VERSION ""

NS_ :

BS_:

BU_: PowertrainControlModule AtmosphericSensor SafetyRestraintSystem2 Aftertreatment_2_GasOutlet Aftertreatment_2_GasIntake DieselParticulateFilterControl Turbocharger SafetyRestraintSystem1 CabDisplay2 Aftertreatment_1_GasOutlet Aftertreatment_1_GasIntake OnBoardDataLogger OffBoardDiagnosticTool2 OffBoardDiagnosticTool1 FileServer ParkingBrakeController SeatController2 FanDriveController SteeringColumnUnit CommunicationUnitRadio CommunicationUnitSatellite CommunicationUnitCellular PropulsionBatteryCharger ChassisController2 ChassisController1 EngineValveControl AuxiliaryHeater2 AuxiliaryHeater1 ClutchUnit RampControl InformationSystem1 SuspensionSystemController2 OilSensor VehicleDynamicStability ExhaustEmissionController TransmissionDisplay2 TransmissionDisplay1 ClimateControl2 WaterPumpController RearAxleSteeringController LightingOperatorControl SeatController1 IgnitionController2 IgnitionController1 TirePressureController CabController2 CabController1 PneumaticSystemController SuspensionSystemController1 HydraulicPumpController EnduranceBrakingSystem RetarderExhaustEngine2 OnBoardDiagnosticUnit HeadwayController RetarderExhaustEngine1 CabDisplay1 ManagementComputer VirtualTerminal OffVehicleGateway PowerTakeOffFront HitchControl AuxiliaryValveControl BodyController TractorTrailerBridge1 StarterSystem ElectricalSystem VehicleSecurity VehicleNavigation AerodynamicControl ElectricalChargingSystem ClimateControl1 TripRecorder InstrumentCluster SuspensionDriveAxle2 SuspensionDriveAxle1 SuspensionSteerAxle SteeringController FuelSystem CruiseControl RetarderDriveline RetarderEngine BrakesDriveAxle2 BrakesDriveAxle1 BrakesSystemController BrakesSteerAxle AxleDrive2 AxleDrive1 AxleSteering PowerTakeOff ShiftConsoleSecondary ShiftConsolePrimary Transmission2 Transmission1 Engine2 Engine1

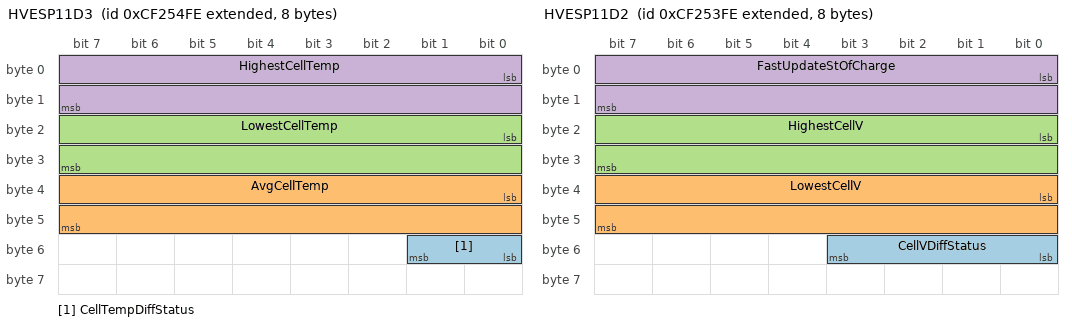
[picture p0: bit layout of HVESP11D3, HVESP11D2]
BO_ 2364691710 HVESP11D3: 8 Vector__XXX
 SG_ CellTempDiffStatus : 48|2@1+ (1,0) [0|3] "" Vector__XXX
 SG_ AvgCellTemp : 32|16@1+ (0.03125,-273) [-273|1734.96875] "°C" Vector__XXX
 SG_ LowestCellTemp : 16|16@1+ (0.03125,-273) [-273|1734.96875] "°C" Vector__XXX
 SG_ HighestCellTemp : 0|16@1+ (0.03125,-273) [-273|1734.96875] "°C" Vector__XXX

BO_ 2364691454 HVESP11D2: 8 Vector__XXX
 SG_ CellVDiffStatus : 48|4@1+ (1,0) [0|15] "" Vector__XXX
 SG_ LowestCellV : 32|16@1+ (0.001,0) [0|64.255] "V" Vector__XXX
 SG_ HighestCellV : 16|16@1+ (0.001,0) [0|64.255] "V" Vector__XXX
 SG_ FastUpdateStOfCharge : 0|16@1+ (0.0015625,0) [0|100.3984375] "%" Vector__XXX

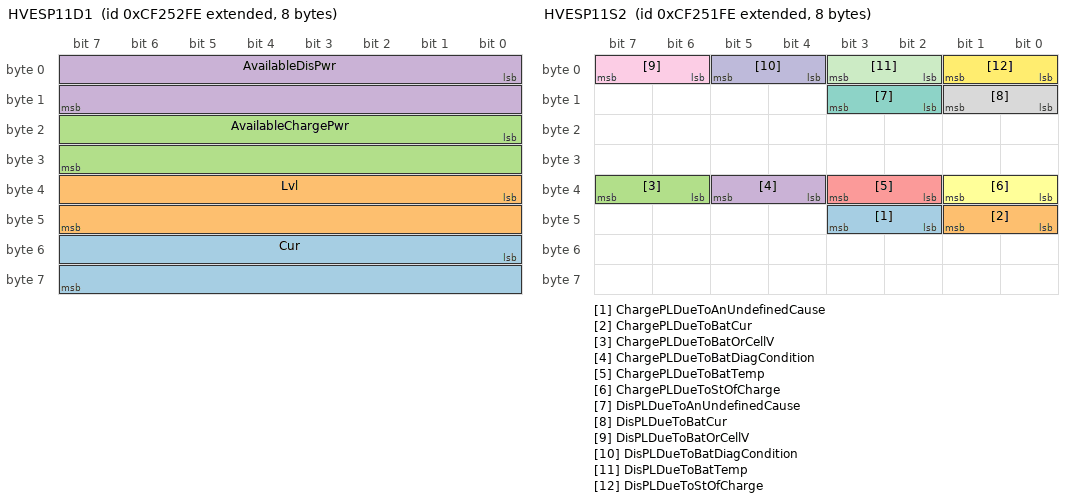
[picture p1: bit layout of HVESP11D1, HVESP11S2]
BO_ 2364691198 HVESP11D1: 8 Vector__XXX
 SG_ Cur : 48|16@1+ (0.05,-1600) [-1600|1612.75] "A" Vector__XXX
 SG_ Lvl : 32|16@1+ (0.05,0) [0|3212.75] "V" Vector__XXX
 SG_ AvailableChargePwr : 16|16@1+ (0.05,0) [0|3212.75] "kW" Vector__XXX
 SG_ AvailableDisPwr : 0|16@1+ (0.05,0) [0|3212.75] "kW" Vector__XXX

BO_ 2364690942 HVESP11S2: 8 Vector__XXX
 SG_ ChargePLDueToAnUndefinedCause : 42|2@1+ (1,0) [0|3] "" Vector__XXX
 SG_ ChargePLDueToBatCur : 40|2@1+ (1,0) [0|3] "" Vector__XXX
 SG_ ChargePLDueToBatOrCellV : 38|2@1+ (1,0) [0|3] "" Vector__XXX
 SG_ ChargePLDueToBatDiagCondition : 36|2@1+ (1,0) [0|3] "" Vector__XXX
 SG_ ChargePLDueToBatTemp : 34|2@1+ (1,0) [0|3] "" Vector__XXX
 SG_ ChargePLDueToStOfCharge : 32|2@1+ (1,0) [0|3] "" Vector__XXX
 SG_ DisPLDueToAnUndefinedCause : 10|2@1+ (1,0) [0|3] "" Vector__XXX
 SG_ DisPLDueToBatCur : 8|2@1+ (1,0) [0|3] "" Vector__XXX
 SG_ DisPLDueToBatOrCellV : 6|2@1+ (1,0) [0|3] "" Vector__XXX
 SG_ DisPLDueToBatDiagCondition : 4|2@1+ (1,0) [0|3] "" Vector__XXX
 SG_ DisPLDueToBatTemp : 2|2@1+ (1,0) [0|3] "" Vector__XXX
 SG_ DisPLDueToStOfCharge : 0|2@1+ (1,0) [0|3] "" Vector__XXX

BO_ 2364690686 EATC1: 8 Vector__XXX
 SG_ OutSpd : 0|16@1+ (0.125,0) [0|8031.875] "rpm" Vector__XXX

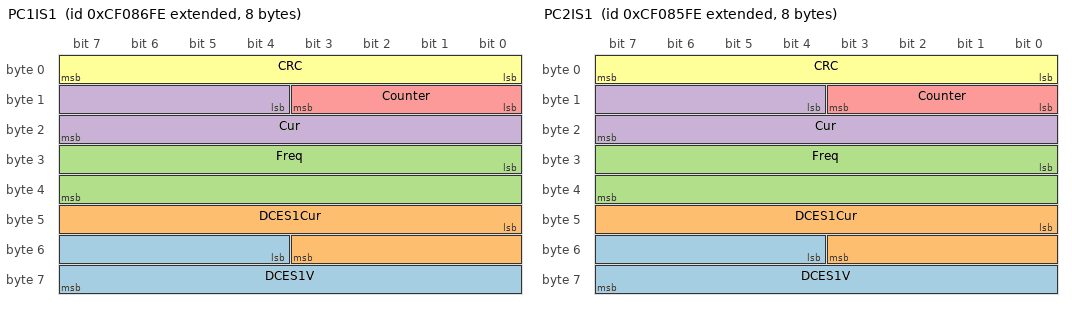
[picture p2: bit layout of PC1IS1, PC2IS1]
BO_ 2364573438 PC1IS1: 8 Vector__XXX
 SG_ DCES1V : 52|12@1+ (0.0625,-125) [-125|125.9375] "%" Vector__XXX
 SG_ DCES1Cur : 40|12@1+ (0.0625,-125) [-125|125.9375] "%" Vector__XXX
 SG_ Freq : 24|16@1+ (0.00390625,-125) [-125|125.99609375] "%" Vector__XXX
 SG_ Cur : 12|12@1+ (0.0625,-125) [-125|125.9375] "%" Vector__XXX
 SG_ Counter : 8|4@1+ (1,0) [0|15] "" Vector__XXX
 SG_ CRC : 0|8@1+ (1,0) [0|255] "" Vector__XXX

BO_ 2364573182 PC2IS1: 8 Vector__XXX
 SG_ DCES1V : 52|12@1+ (0.0625,-125) [-125|125.9375] "%" Vector__XXX
 SG_ DCES1Cur : 40|12@1+ (0.0625,-125) [-125|125.9375] "%" Vector__XXX
 SG_ Freq : 24|16@1+ (0.00390625,-125) [-125|125.99609375] "%" Vector__XXX
 SG_ Cur : 12|12@1+ (0.0625,-125) [-125|125.9375] "%" Vector__XXX
 SG_ Counter : 8|4@1+ (1,0) [0|15] "" Vector__XXX
 SG_ CRC : 0|8@1+ (1,0) [0|255] "" Vector__XXX

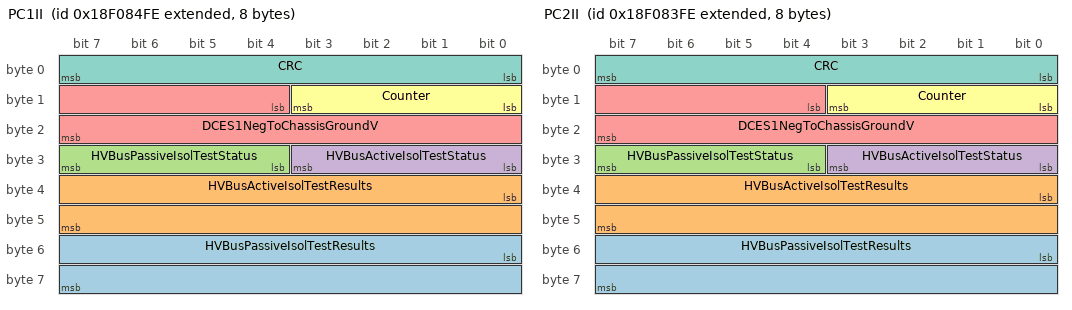
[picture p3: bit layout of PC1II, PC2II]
BO_ 2565899518 PC1II: 8 Vector__XXX
 SG_ HVBusPassiveIsolTestResults : 48|16@1+ (0.1,0) [0|6425.5] "Ohm/V" Vector__XXX
 SG_ HVBusActiveIsolTestResults : 32|16@1+ (0.1,0) [0|6425.5] "Ohm/V" Vector__XXX
 SG_ HVBusPassiveIsolTestStatus : 28|4@1+ (1,0) [0|15] "" Vector__XXX
 SG_ HVBusActiveIsolTestStatus : 24|4@1+ (1,0) [0|15] "" Vector__XXX
 SG_ DCES1NegToChassisGroundV : 12|12@1+ (0.0625,-125) [-125|125.9375] "%" Vector__XXX
 SG_ Counter : 8|4@1+ (1,0) [0|15] "" Vector__XXX
 SG_ CRC : 0|8@1+ (1,0) [0|255] "" Vector__XXX

BO_ 2565899262 PC2II: 8 Vector__XXX
 SG_ HVBusPassiveIsolTestResults : 48|16@1+ (0.1,0) [0|6425.5] "Ohm/V" Vector__XXX
 SG_ HVBusActiveIsolTestResults : 32|16@1+ (0.1,0) [0|6425.5] "Ohm/V" Vector__XXX
 SG_ HVBusPassiveIsolTestStatus : 28|4@1+ (1,0) [0|15] "" Vector__XXX
 SG_ HVBusActiveIsolTestStatus : 24|4@1+ (1,0) [0|15] "" Vector__XXX
 SG_ DCES1NegToChassisGroundV : 12|12@1+ (0.0625,-125) [-125|125.9375] "%" Vector__XXX
 SG_ Counter : 8|4@1+ (1,0) [0|15] "" Vector__XXX
 SG_ CRC : 0|8@1+ (1,0) [0|255] "" Vector__XXX

BO_ 2565899006 PC2IRLA1: 8 Vector__XXX
 SG_ AbsCurRateLmt : 24|12@1+ (2,0) [0|8030] "%/s" Vector__XXX
 SG_ Counter : 8|4@1+ (1,0) [0|15] "" Vector__XXX
 SG_ CRC : 0|8@1+ (1,0) [0|255] "" Vector__XXX

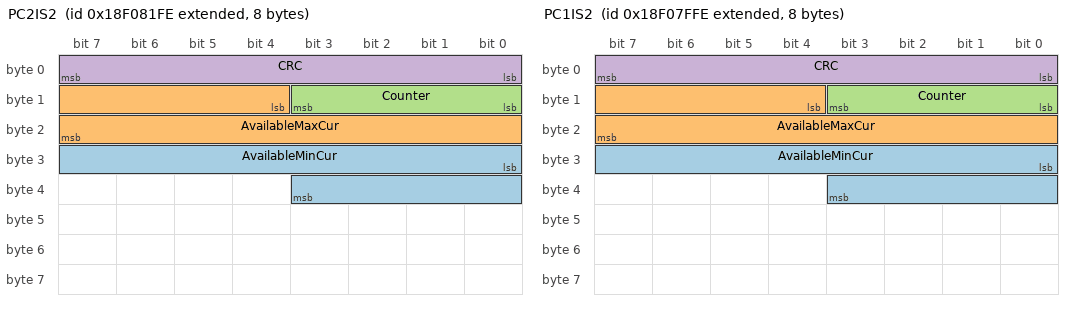
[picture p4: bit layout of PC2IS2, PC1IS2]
BO_ 2565898750 PC2IS2: 8 Vector__XXX
 SG_ AvailableMinCur : 24|12@1+ (0.0625,-125) [-125|125.9375] "%" Vector__XXX
 SG_ AvailableMaxCur : 12|12@1+ (0.0625,-125) [-125|125.9375] "%" Vector__XXX
 SG_ Counter : 8|4@1+ (1,0) [0|15] "" Vector__XXX
 SG_ CRC : 0|8@1+ (1,0) [0|255] "" Vector__XXX

BO_ 2565898494 PC1IRLA1: 8 Vector__XXX
 SG_ AbsCurRateLmt : 24|12@1+ (2,0) [0|8030] "%/s" Vector__XXX
 SG_ Counter : 8|4@1+ (1,0) [0|15] "" Vector__XXX
 SG_ CRC : 0|8@1+ (1,0) [0|255] "" Vector__XXX

BO_ 2565898238 PC1IS2: 8 Vector__XXX
 SG_ AvailableMinCur : 24|12@1+ (0.0625,-125) [-125|125.9375] "%" Vector__XXX
 SG_ AvailableMaxCur : 12|12@1+ (0.0625,-125) [-125|125.9375] "%" Vector__XXX
 SG_ Counter : 8|4@1+ (1,0) [0|15] "" Vector__XXX
 SG_ CRC : 0|8@1+ (1,0) [0|255] "" Vector__XXX

BO_ 2565897982 PC2ILV: 8 Vector__XXX
 SG_ UnswitchedSLIV : 16|16@1+ (0.05,0) [0|3212.75] "V" Vector__XXX
 SG_ SwitchedIgntV : 0|16@1+ (0.05,0) [0|3212.75] "V" Vector__XXX

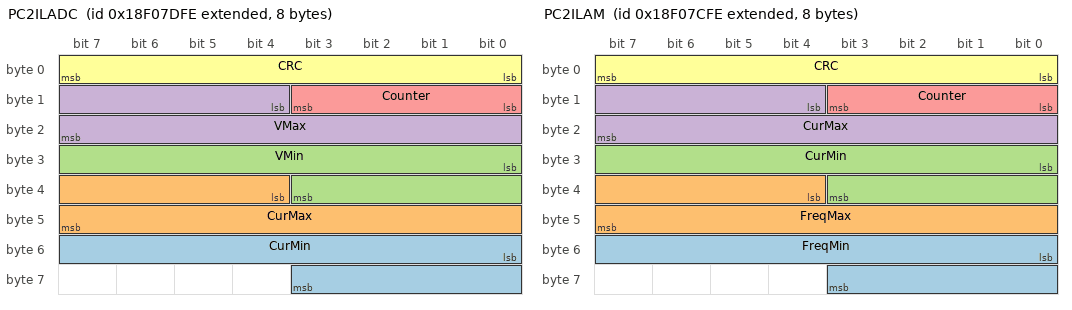
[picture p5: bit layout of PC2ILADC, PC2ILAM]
BO_ 2565897726 PC2ILADC: 8 Vector__XXX
 SG_ CurMin : 48|12@1+ (0.0625,-125) [-125|125.9375] "%" Vector__XXX
 SG_ CurMax : 36|12@1+ (0.0625,-125) [-125|125.9375] "%" Vector__XXX
 SG_ VMin : 24|12@1+ (0.0625,-125) [-125|125.9375] "%" Vector__XXX
 SG_ VMax : 12|12@1+ (0.0625,-125) [-125|125.9375] "%" Vector__XXX
 SG_ Counter : 8|4@1+ (1,0) [0|15] "" Vector__XXX
 SG_ CRC : 0|8@1+ (1,0) [0|255] "" Vector__XXX

BO_ 2565897470 PC2ILAM: 8 Vector__XXX
 SG_ FreqMin : 48|12@1+ (0.0625,-125) [-125|125.9375] "%" Vector__XXX
 SG_ FreqMax : 36|12@1+ (0.0625,-125) [-125|125.9375] "%" Vector__XXX
 SG_ CurMin : 24|12@1+ (0.0625,-125) [-125|125.9375] "%" Vector__XXX
 SG_ CurMax : 12|12@1+ (0.0625,-125) [-125|125.9375] "%" Vector__XXX
 SG_ Counter : 8|4@1+ (1,0) [0|15] "" Vector__XXX
 SG_ CRC : 0|8@1+ (1,0) [0|255] "" Vector__XXX

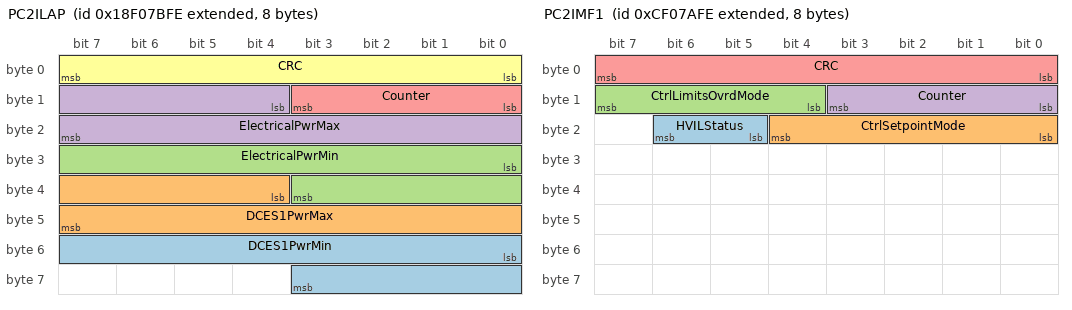
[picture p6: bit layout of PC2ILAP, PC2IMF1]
BO_ 2565897214 PC2ILAP: 8 Vector__XXX
 SG_ DCES1PwrMin : 48|12@1+ (0.0625,-125) [-125|125.9375] "%" Vector__XXX
 SG_ DCES1PwrMax : 36|12@1+ (0.0625,-125) [-125|125.9375] "%" Vector__XXX
 SG_ ElectricalPwrMin : 24|12@1+ (0.0625,-125) [-125|125.9375] "%" Vector__XXX
 SG_ ElectricalPwrMax : 12|12@1+ (0.0625,-125) [-125|125.9375] "%" Vector__XXX
 SG_ Counter : 8|4@1+ (1,0) [0|15] "" Vector__XXX
 SG_ CRC : 0|8@1+ (1,0) [0|255] "" Vector__XXX

BO_ 2364570366 PC2IMF1: 8 Vector__XXX
 SG_ HVILStatus : 21|2@1+ (1,0) [0|3] "" Vector__XXX
 SG_ CtrlSetpointMode : 16|5@1+ (1,0) [0|31] "" Vector__XXX
 SG_ CtrlLimitsOvrdMode : 12|4@1+ (1,0) [0|15] "" Vector__XXX
 SG_ Counter : 8|4@1+ (1,0) [0|15] "" Vector__XXX
 SG_ CRC : 0|8@1+ (1,0) [0|255] "" Vector__XXX

BO_ 2565896702 PC1ILV: 8 Vector__XXX
 SG_ UnswitchedSLIV : 16|16@1+ (0.05,0) [0|3212.75] "V" Vector__XXX
 SG_ SwitchedIgntV : 0|16@1+ (0.05,0) [0|3212.75] "V" Vector__XXX

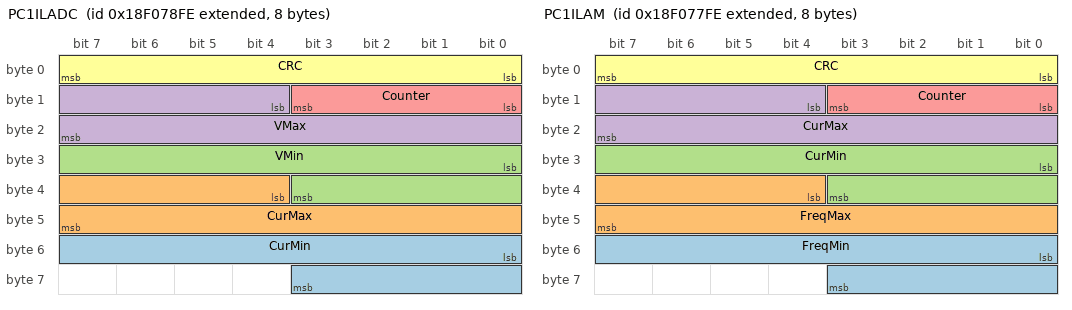
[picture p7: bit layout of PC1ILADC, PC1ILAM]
BO_ 2565896446 PC1ILADC: 8 Vector__XXX
 SG_ CurMin : 48|12@1+ (0.0625,-125) [-125|125.9375] "%" Vector__XXX
 SG_ CurMax : 36|12@1+ (0.0625,-125) [-125|125.9375] "%" Vector__XXX
 SG_ VMin : 24|12@1+ (0.0625,-125) [-125|125.9375] "%" Vector__XXX
 SG_ VMax : 12|12@1+ (0.0625,-125) [-125|125.9375] "%" Vector__XXX
 SG_ Counter : 8|4@1+ (1,0) [0|15] "" Vector__XXX
 SG_ CRC : 0|8@1+ (1,0) [0|255] "" Vector__XXX

BO_ 2565896190 PC1ILAM: 8 Vector__XXX
 SG_ FreqMin : 48|12@1+ (0.0625,-125) [-125|125.9375] "%" Vector__XXX
 SG_ FreqMax : 36|12@1+ (0.0625,-125) [-125|125.9375] "%" Vector__XXX
 SG_ CurMin : 24|12@1+ (0.0625,-125) [-125|125.9375] "%" Vector__XXX
 SG_ CurMax : 12|12@1+ (0.0625,-125) [-125|125.9375] "%" Vector__XXX
 SG_ Counter : 8|4@1+ (1,0) [0|15] "" Vector__XXX
 SG_ CRC : 0|8@1+ (1,0) [0|255] "" Vector__XXX

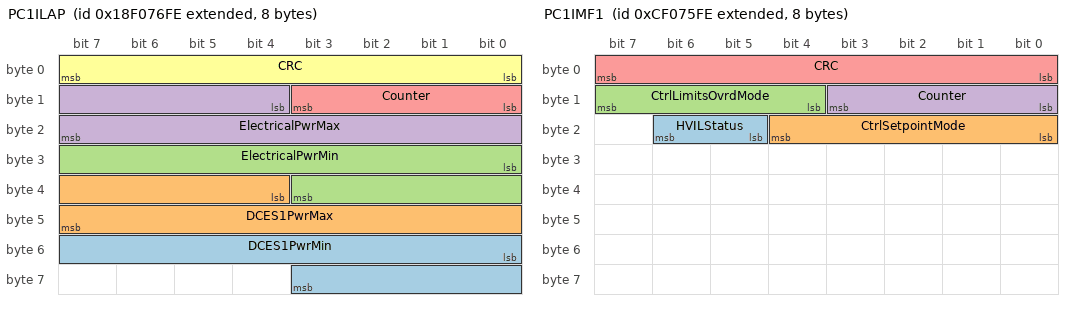
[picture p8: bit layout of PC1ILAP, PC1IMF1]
BO_ 2565895934 PC1ILAP: 8 Vector__XXX
 SG_ DCES1PwrMin : 48|12@1+ (0.0625,-125) [-125|125.9375] "%" Vector__XXX
 SG_ DCES1PwrMax : 36|12@1+ (0.0625,-125) [-125|125.9375] "%" Vector__XXX
 SG_ ElectricalPwrMin : 24|12@1+ (0.0625,-125) [-125|125.9375] "%" Vector__XXX
 SG_ ElectricalPwrMax : 12|12@1+ (0.0625,-125) [-125|125.9375] "%" Vector__XXX
 SG_ Counter : 8|4@1+ (1,0) [0|15] "" Vector__XXX
 SG_ CRC : 0|8@1+ (1,0) [0|255] "" Vector__XXX

BO_ 2364569086 PC1IMF1: 8 Vector__XXX
 SG_ HVILStatus : 21|2@1+ (1,0) [0|3] "" Vector__XXX
 SG_ CtrlSetpointMode : 16|5@1+ (1,0) [0|31] "" Vector__XXX
 SG_ CtrlLimitsOvrdMode : 12|4@1+ (1,0) [0|15] "" Vector__XXX
 SG_ Counter : 8|4@1+ (1,0) [0|15] "" Vector__XXX
 SG_ CRC : 0|8@1+ (1,0) [0|255] "" Vector__XXX

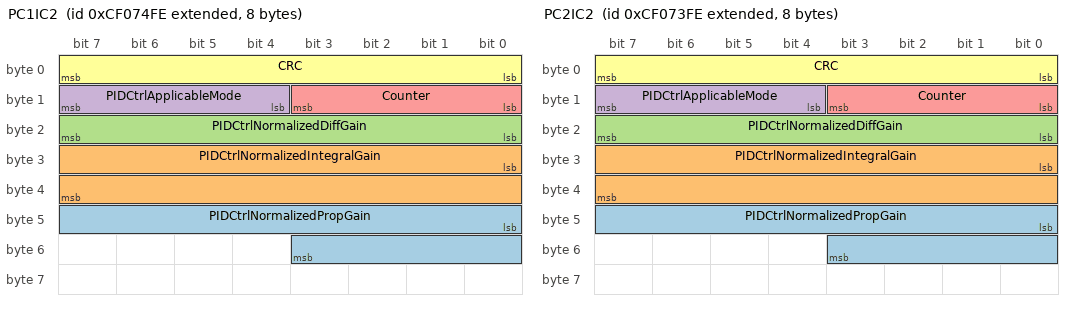
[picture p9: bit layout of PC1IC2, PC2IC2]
BO_ 2364568830 PC1IC2: 8 Vector__XXX
 SG_ PIDCtrlNormalizedPropGain : 40|12@1+ (0.0625,0) [0|250.9375] "%/%" Vector__XXX
 SG_ PIDCtrlNormalizedIntegralGain : 24|16@1+ (0.015625,0) [0|1003.984375] "%/(%*s)" Vector__XXX
 SG_ PIDCtrlNormalizedDiffGain : 16|8@1+ (0.03125,0) [0|7.8125] "%/(%/s)" Vector__XXX
 SG_ PIDCtrlApplicableMode : 12|4@1+ (1,0) [0|15] "" Vector__XXX
 SG_ Counter : 8|4@1+ (1,0) [0|15] "" Vector__XXX
 SG_ CRC : 0|8@1+ (1,0) [0|255] "" Vector__XXX

BO_ 2364568574 PC2IC2: 8 Vector__XXX
 SG_ PIDCtrlNormalizedPropGain : 40|12@1+ (0.0625,0) [0|250.9375] "%/%" Vector__XXX
 SG_ PIDCtrlNormalizedIntegralGain : 24|16@1+ (0.015625,0) [0|1003.984375] "%/(%*s)" Vector__XXX
 SG_ PIDCtrlNormalizedDiffGain : 16|8@1+ (0.03125,0) [0|7.8125] "%/(%/s)" Vector__XXX
 SG_ PIDCtrlApplicableMode : 12|4@1+ (1,0) [0|15] "" Vector__XXX
 SG_ Counter : 8|4@1+ (1,0) [0|15] "" Vector__XXX
 SG_ CRC : 0|8@1+ (1,0) [0|255] "" Vector__XXX

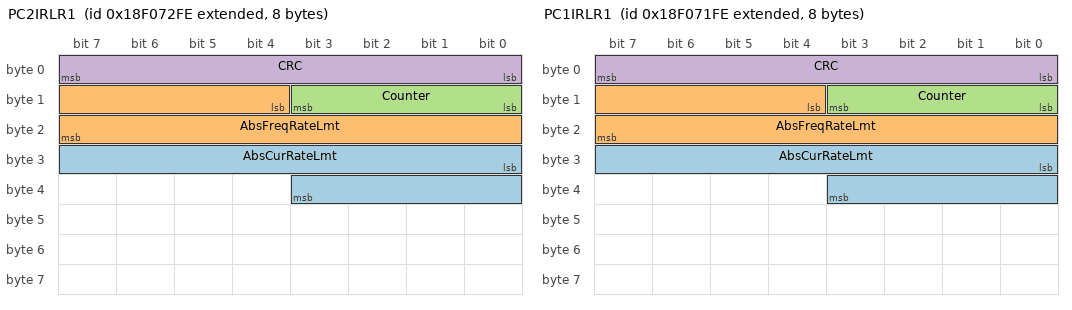
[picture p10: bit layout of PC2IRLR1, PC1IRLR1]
BO_ 2565894910 PC2IRLR1: 8 Vector__XXX
 SG_ AbsCurRateLmt : 24|12@1+ (2,0) [0|8030] "%/s" Vector__XXX
 SG_ AbsFreqRateLmt : 12|12@1+ (0.25,0) [0|1003.75] "%/s" Vector__XXX
 SG_ Counter : 8|4@1+ (1,0) [0|15] "" Vector__XXX
 SG_ CRC : 0|8@1+ (1,0) [0|255] "" Vector__XXX

BO_ 2565894654 PC1IRLR1: 8 Vector__XXX
 SG_ AbsCurRateLmt : 24|12@1+ (2,0) [0|8030] "%/s" Vector__XXX
 SG_ AbsFreqRateLmt : 12|12@1+ (0.25,0) [0|1003.75] "%/s" Vector__XXX
 SG_ Counter : 8|4@1+ (1,0) [0|15] "" Vector__XXX
 SG_ CRC : 0|8@1+ (1,0) [0|255] "" Vector__XXX

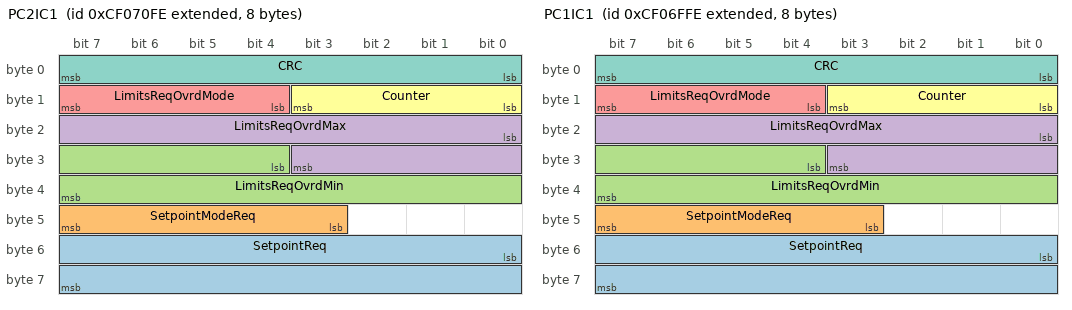
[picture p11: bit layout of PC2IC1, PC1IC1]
BO_ 2364567806 PC2IC1: 8 Vector__XXX
 SG_ SetpointReq : 48|16@1+ (0.00390625,-125) [-125|125.99609375] "%" Vector__XXX
 SG_ SetpointModeReq : 43|5@1+ (1,0) [0|31] "" Vector__XXX
 SG_ LimitsReqOvrdMin : 28|12@1+ (0.0625,-125) [-125|125.9375] "%" Vector__XXX
 SG_ LimitsReqOvrdMax : 16|12@1+ (0.0625,-125) [-125|125.9375] "%" Vector__XXX
 SG_ LimitsReqOvrdMode : 12|4@1+ (1,0) [0|15] "" Vector__XXX
 SG_ Counter : 8|4@1+ (1,0) [0|15] "" Vector__XXX
 SG_ CRC : 0|8@1+ (1,0) [0|255] "" Vector__XXX

BO_ 2364567550 PC1IC1: 8 Vector__XXX
 SG_ SetpointReq : 48|16@1+ (0.00390625,-125) [-125|125.99609375] "%" Vector__XXX
 SG_ SetpointModeReq : 43|5@1+ (1,0) [0|31] "" Vector__XXX
 SG_ LimitsReqOvrdMin : 28|12@1+ (0.0625,-125) [-125|125.9375] "%" Vector__XXX
 SG_ LimitsReqOvrdMax : 16|12@1+ (0.0625,-125) [-125|125.9375] "%" Vector__XXX
 SG_ LimitsReqOvrdMode : 12|4@1+ (1,0) [0|15] "" Vector__XXX
 SG_ Counter : 8|4@1+ (1,0) [0|15] "" Vector__XXX
 SG_ CRC : 0|8@1+ (1,0) [0|255] "" Vector__XXX

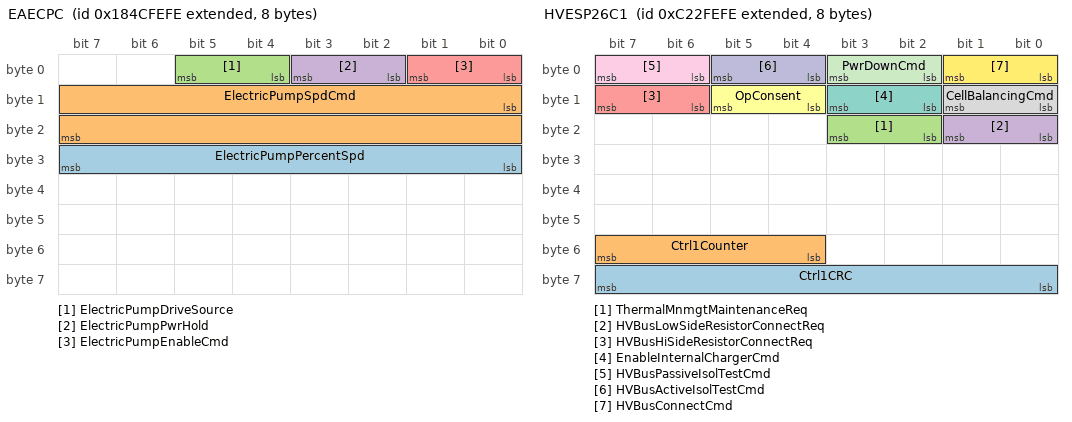
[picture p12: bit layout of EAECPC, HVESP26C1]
BO_ 2555182846 EAECPC: 8 Vector__XXX
 SG_ ElectricPumpPercentSpd : 24|8@1+ (0.5,0) [0|125] "%" Vector__XXX
 SG_ ElectricPumpSpdCmd : 8|16@1+ (0.5,0) [0|32127.5] "rpm" Vector__XXX
 SG_ ElectricPumpDriveSource : 4|2@1+ (1,0) [0|3] "" Vector__XXX
 SG_ ElectricPumpPwrHold : 2|2@1+ (1,0) [0|3] "" Vector__XXX
 SG_ ElectricPumpEnableCmd : 0|2@1+ (1,0) [0|3] "" Vector__XXX

BO_ 2351103742 HVESP26C1: 8 Vector__XXX
 SG_ Ctrl1CRC : 56|8@1+ (1,0) [0|255] "" Vector__XXX
 SG_ Ctrl1Counter : 52|4@1+ (1,0) [0|15] "" Vector__XXX
 SG_ ThermalMnmgtMaintenanceReq : 18|2@1+ (1,0) [0|3] "" Vector__XXX
 SG_ HVBusLowSideResistorConnectReq : 16|2@1+ (1,0) [0|3] "" Vector__XXX
 SG_ HVBusHiSideResistorConnectReq : 14|2@1+ (1,0) [0|3] "" Vector__XXX
 SG_ OpConsent : 12|2@1+ (1,0) [0|3] "" Vector__XXX
 SG_ EnableInternalChargerCmd : 10|2@1+ (1,0) [0|3] "" Vector__XXX
 SG_ CellBalancingCmd : 8|2@1+ (1,0) [0|3] "" Vector__XXX
 SG_ HVBusPassiveIsolTestCmd : 6|2@1+ (1,0) [0|3] "" Vector__XXX
 SG_ HVBusActiveIsolTestCmd : 4|2@1+ (1,0) [0|3] "" Vector__XXX
 SG_ PwrDownCmd : 2|2@1+ (1,0) [0|3] "" Vector__XXX
 SG_ HVBusConnectCmd : 0|2@1+ (1,0) [0|3] "" Vector__XXX

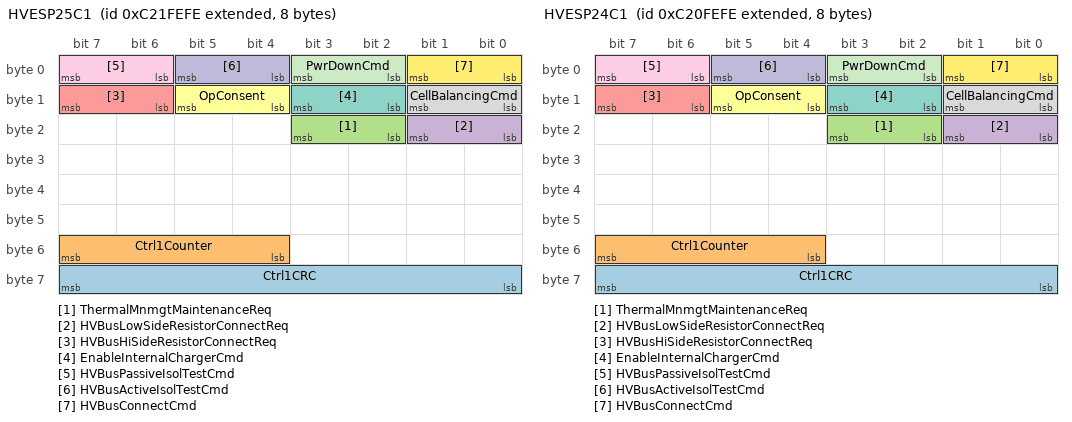
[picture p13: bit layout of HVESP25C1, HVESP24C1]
BO_ 2351038206 HVESP25C1: 8 Vector__XXX
 SG_ Ctrl1CRC : 56|8@1+ (1,0) [0|255] "" Vector__XXX
 SG_ Ctrl1Counter : 52|4@1+ (1,0) [0|15] "" Vector__XXX
 SG_ ThermalMnmgtMaintenanceReq : 18|2@1+ (1,0) [0|3] "" Vector__XXX
 SG_ HVBusLowSideResistorConnectReq : 16|2@1+ (1,0) [0|3] "" Vector__XXX
 SG_ HVBusHiSideResistorConnectReq : 14|2@1+ (1,0) [0|3] "" Vector__XXX
 SG_ OpConsent : 12|2@1+ (1,0) [0|3] "" Vector__XXX
 SG_ EnableInternalChargerCmd : 10|2@1+ (1,0) [0|3] "" Vector__XXX
 SG_ CellBalancingCmd : 8|2@1+ (1,0) [0|3] "" Vector__XXX
 SG_ HVBusPassiveIsolTestCmd : 6|2@1+ (1,0) [0|3] "" Vector__XXX
 SG_ HVBusActiveIsolTestCmd : 4|2@1+ (1,0) [0|3] "" Vector__XXX
 SG_ PwrDownCmd : 2|2@1+ (1,0) [0|3] "" Vector__XXX
 SG_ HVBusConnectCmd : 0|2@1+ (1,0) [0|3] "" Vector__XXX

BO_ 2350972670 HVESP24C1: 8 Vector__XXX
 SG_ Ctrl1CRC : 56|8@1+ (1,0) [0|255] "" Vector__XXX
 SG_ Ctrl1Counter : 52|4@1+ (1,0) [0|15] "" Vector__XXX
 SG_ ThermalMnmgtMaintenanceReq : 18|2@1+ (1,0) [0|3] "" Vector__XXX
 SG_ HVBusLowSideResistorConnectReq : 16|2@1+ (1,0) [0|3] "" Vector__XXX
 SG_ HVBusHiSideResistorConnectReq : 14|2@1+ (1,0) [0|3] "" Vector__XXX
 SG_ OpConsent : 12|2@1+ (1,0) [0|3] "" Vector__XXX
 SG_ EnableInternalChargerCmd : 10|2@1+ (1,0) [0|3] "" Vector__XXX
 SG_ CellBalancingCmd : 8|2@1+ (1,0) [0|3] "" Vector__XXX
 SG_ HVBusPassiveIsolTestCmd : 6|2@1+ (1,0) [0|3] "" Vector__XXX
 SG_ HVBusActiveIsolTestCmd : 4|2@1+ (1,0) [0|3] "" Vector__XXX
 SG_ PwrDownCmd : 2|2@1+ (1,0) [0|3] "" Vector__XXX
 SG_ HVBusConnectCmd : 0|2@1+ (1,0) [0|3] "" Vector__XXX

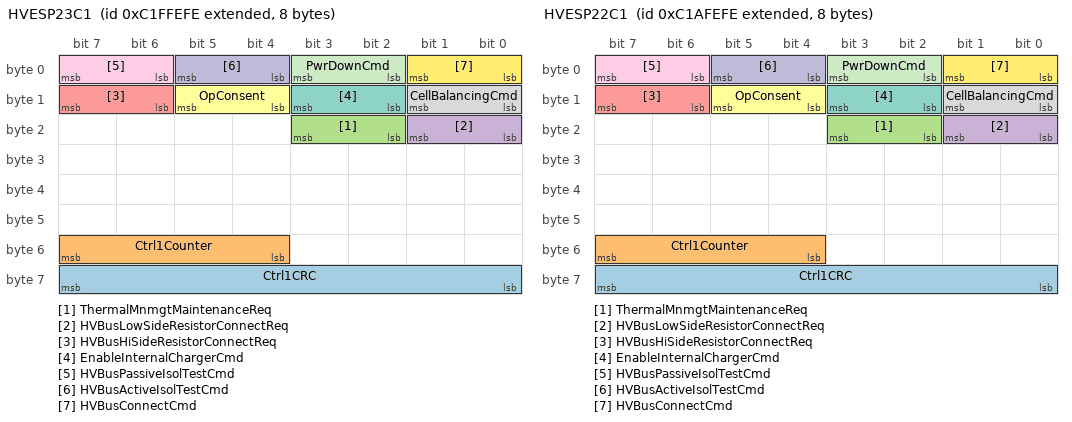
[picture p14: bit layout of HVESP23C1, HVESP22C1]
BO_ 2350907134 HVESP23C1: 8 Vector__XXX
 SG_ Ctrl1CRC : 56|8@1+ (1,0) [0|255] "" Vector__XXX
 SG_ Ctrl1Counter : 52|4@1+ (1,0) [0|15] "" Vector__XXX
 SG_ ThermalMnmgtMaintenanceReq : 18|2@1+ (1,0) [0|3] "" Vector__XXX
 SG_ HVBusLowSideResistorConnectReq : 16|2@1+ (1,0) [0|3] "" Vector__XXX
 SG_ HVBusHiSideResistorConnectReq : 14|2@1+ (1,0) [0|3] "" Vector__XXX
 SG_ OpConsent : 12|2@1+ (1,0) [0|3] "" Vector__XXX
 SG_ EnableInternalChargerCmd : 10|2@1+ (1,0) [0|3] "" Vector__XXX
 SG_ CellBalancingCmd : 8|2@1+ (1,0) [0|3] "" Vector__XXX
 SG_ HVBusPassiveIsolTestCmd : 6|2@1+ (1,0) [0|3] "" Vector__XXX
 SG_ HVBusActiveIsolTestCmd : 4|2@1+ (1,0) [0|3] "" Vector__XXX
 SG_ PwrDownCmd : 2|2@1+ (1,0) [0|3] "" Vector__XXX
 SG_ HVBusConnectCmd : 0|2@1+ (1,0) [0|3] "" Vector__XXX

BO_ 2350579454 HVESP22C1: 8 Vector__XXX
 SG_ Ctrl1CRC : 56|8@1+ (1,0) [0|255] "" Vector__XXX
 SG_ Ctrl1Counter : 52|4@1+ (1,0) [0|15] "" Vector__XXX
 SG_ ThermalMnmgtMaintenanceReq : 18|2@1+ (1,0) [0|3] "" Vector__XXX
 SG_ HVBusLowSideResistorConnectReq : 16|2@1+ (1,0) [0|3] "" Vector__XXX
 SG_ HVBusHiSideResistorConnectReq : 14|2@1+ (1,0) [0|3] "" Vector__XXX
 SG_ OpConsent : 12|2@1+ (1,0) [0|3] "" Vector__XXX
 SG_ EnableInternalChargerCmd : 10|2@1+ (1,0) [0|3] "" Vector__XXX
 SG_ CellBalancingCmd : 8|2@1+ (1,0) [0|3] "" Vector__XXX
 SG_ HVBusPassiveIsolTestCmd : 6|2@1+ (1,0) [0|3] "" Vector__XXX
 SG_ HVBusActiveIsolTestCmd : 4|2@1+ (1,0) [0|3] "" Vector__XXX
 SG_ PwrDownCmd : 2|2@1+ (1,0) [0|3] "" Vector__XXX
 SG_ HVBusConnectCmd : 0|2@1+ (1,0) [0|3] "" Vector__XXX

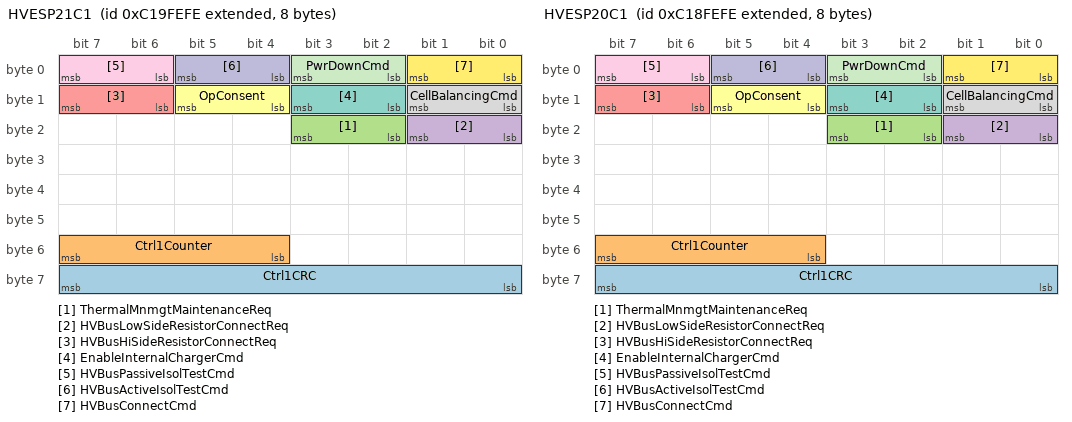
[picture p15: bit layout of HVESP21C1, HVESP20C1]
BO_ 2350513918 HVESP21C1: 8 Vector__XXX
 SG_ Ctrl1CRC : 56|8@1+ (1,0) [0|255] "" Vector__XXX
 SG_ Ctrl1Counter : 52|4@1+ (1,0) [0|15] "" Vector__XXX
 SG_ ThermalMnmgtMaintenanceReq : 18|2@1+ (1,0) [0|3] "" Vector__XXX
 SG_ HVBusLowSideResistorConnectReq : 16|2@1+ (1,0) [0|3] "" Vector__XXX
 SG_ HVBusHiSideResistorConnectReq : 14|2@1+ (1,0) [0|3] "" Vector__XXX
 SG_ OpConsent : 12|2@1+ (1,0) [0|3] "" Vector__XXX
 SG_ EnableInternalChargerCmd : 10|2@1+ (1,0) [0|3] "" Vector__XXX
 SG_ CellBalancingCmd : 8|2@1+ (1,0) [0|3] "" Vector__XXX
 SG_ HVBusPassiveIsolTestCmd : 6|2@1+ (1,0) [0|3] "" Vector__XXX
 SG_ HVBusActiveIsolTestCmd : 4|2@1+ (1,0) [0|3] "" Vector__XXX
 SG_ PwrDownCmd : 2|2@1+ (1,0) [0|3] "" Vector__XXX
 SG_ HVBusConnectCmd : 0|2@1+ (1,0) [0|3] "" Vector__XXX

BO_ 2350448382 HVESP20C1: 8 Vector__XXX
 SG_ Ctrl1CRC : 56|8@1+ (1,0) [0|255] "" Vector__XXX
 SG_ Ctrl1Counter : 52|4@1+ (1,0) [0|15] "" Vector__XXX
 SG_ ThermalMnmgtMaintenanceReq : 18|2@1+ (1,0) [0|3] "" Vector__XXX
 SG_ HVBusLowSideResistorConnectReq : 16|2@1+ (1,0) [0|3] "" Vector__XXX
 SG_ HVBusHiSideResistorConnectReq : 14|2@1+ (1,0) [0|3] "" Vector__XXX
 SG_ OpConsent : 12|2@1+ (1,0) [0|3] "" Vector__XXX
 SG_ EnableInternalChargerCmd : 10|2@1+ (1,0) [0|3] "" Vector__XXX
 SG_ CellBalancingCmd : 8|2@1+ (1,0) [0|3] "" Vector__XXX
 SG_ HVBusPassiveIsolTestCmd : 6|2@1+ (1,0) [0|3] "" Vector__XXX
 SG_ HVBusActiveIsolTestCmd : 4|2@1+ (1,0) [0|3] "" Vector__XXX
 SG_ PwrDownCmd : 2|2@1+ (1,0) [0|3] "" Vector__XXX
 SG_ HVBusConnectCmd : 0|2@1+ (1,0) [0|3] "" Vector__XXX

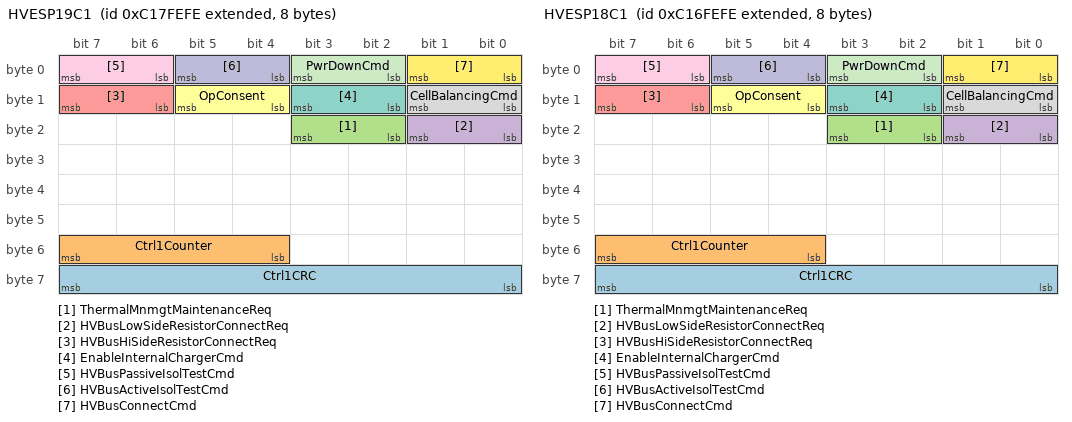
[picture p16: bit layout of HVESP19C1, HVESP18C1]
BO_ 2350382846 HVESP19C1: 8 Vector__XXX
 SG_ Ctrl1CRC : 56|8@1+ (1,0) [0|255] "" Vector__XXX
 SG_ Ctrl1Counter : 52|4@1+ (1,0) [0|15] "" Vector__XXX
 SG_ ThermalMnmgtMaintenanceReq : 18|2@1+ (1,0) [0|3] "" Vector__XXX
 SG_ HVBusLowSideResistorConnectReq : 16|2@1+ (1,0) [0|3] "" Vector__XXX
 SG_ HVBusHiSideResistorConnectReq : 14|2@1+ (1,0) [0|3] "" Vector__XXX
 SG_ OpConsent : 12|2@1+ (1,0) [0|3] "" Vector__XXX
 SG_ EnableInternalChargerCmd : 10|2@1+ (1,0) [0|3] "" Vector__XXX
 SG_ CellBalancingCmd : 8|2@1+ (1,0) [0|3] "" Vector__XXX
 SG_ HVBusPassiveIsolTestCmd : 6|2@1+ (1,0) [0|3] "" Vector__XXX
 SG_ HVBusActiveIsolTestCmd : 4|2@1+ (1,0) [0|3] "" Vector__XXX
 SG_ PwrDownCmd : 2|2@1+ (1,0) [0|3] "" Vector__XXX
 SG_ HVBusConnectCmd : 0|2@1+ (1,0) [0|3] "" Vector__XXX

BO_ 2350317310 HVESP18C1: 8 Vector__XXX
 SG_ Ctrl1CRC : 56|8@1+ (1,0) [0|255] "" Vector__XXX
 SG_ Ctrl1Counter : 52|4@1+ (1,0) [0|15] "" Vector__XXX
 SG_ ThermalMnmgtMaintenanceReq : 18|2@1+ (1,0) [0|3] "" Vector__XXX
 SG_ HVBusLowSideResistorConnectReq : 16|2@1+ (1,0) [0|3] "" Vector__XXX
 SG_ HVBusHiSideResistorConnectReq : 14|2@1+ (1,0) [0|3] "" Vector__XXX
 SG_ OpConsent : 12|2@1+ (1,0) [0|3] "" Vector__XXX
 SG_ EnableInternalChargerCmd : 10|2@1+ (1,0) [0|3] "" Vector__XXX
 SG_ CellBalancingCmd : 8|2@1+ (1,0) [0|3] "" Vector__XXX
 SG_ HVBusPassiveIsolTestCmd : 6|2@1+ (1,0) [0|3] "" Vector__XXX
 SG_ HVBusActiveIsolTestCmd : 4|2@1+ (1,0) [0|3] "" Vector__XXX
 SG_ PwrDownCmd : 2|2@1+ (1,0) [0|3] "" Vector__XXX
 SG_ HVBusConnectCmd : 0|2@1+ (1,0) [0|3] "" Vector__XXX

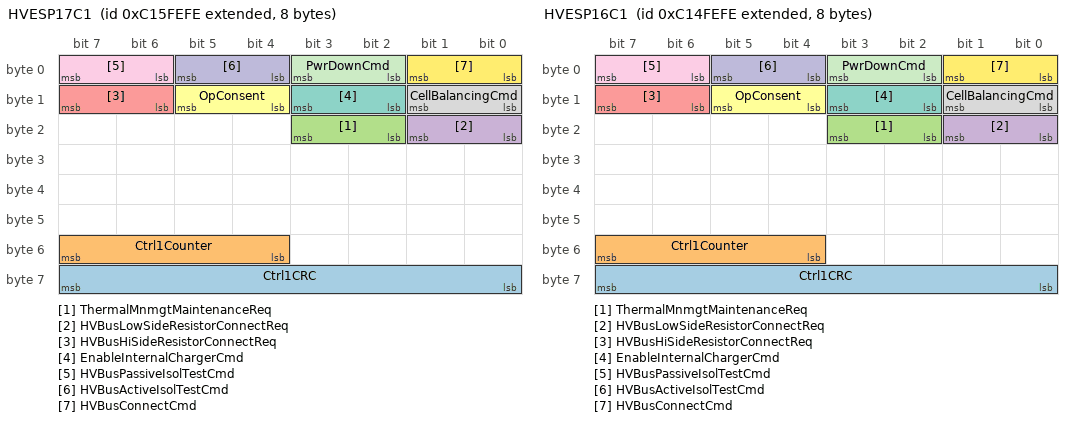
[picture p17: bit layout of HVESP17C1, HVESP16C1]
BO_ 2350251774 HVESP17C1: 8 Vector__XXX
 SG_ Ctrl1CRC : 56|8@1+ (1,0) [0|255] "" Vector__XXX
 SG_ Ctrl1Counter : 52|4@1+ (1,0) [0|15] "" Vector__XXX
 SG_ ThermalMnmgtMaintenanceReq : 18|2@1+ (1,0) [0|3] "" Vector__XXX
 SG_ HVBusLowSideResistorConnectReq : 16|2@1+ (1,0) [0|3] "" Vector__XXX
 SG_ HVBusHiSideResistorConnectReq : 14|2@1+ (1,0) [0|3] "" Vector__XXX
 SG_ OpConsent : 12|2@1+ (1,0) [0|3] "" Vector__XXX
 SG_ EnableInternalChargerCmd : 10|2@1+ (1,0) [0|3] "" Vector__XXX
 SG_ CellBalancingCmd : 8|2@1+ (1,0) [0|3] "" Vector__XXX
 SG_ HVBusPassiveIsolTestCmd : 6|2@1+ (1,0) [0|3] "" Vector__XXX
 SG_ HVBusActiveIsolTestCmd : 4|2@1+ (1,0) [0|3] "" Vector__XXX
 SG_ PwrDownCmd : 2|2@1+ (1,0) [0|3] "" Vector__XXX
 SG_ HVBusConnectCmd : 0|2@1+ (1,0) [0|3] "" Vector__XXX

BO_ 2350186238 HVESP16C1: 8 Vector__XXX
 SG_ Ctrl1CRC : 56|8@1+ (1,0) [0|255] "" Vector__XXX
 SG_ Ctrl1Counter : 52|4@1+ (1,0) [0|15] "" Vector__XXX
 SG_ ThermalMnmgtMaintenanceReq : 18|2@1+ (1,0) [0|3] "" Vector__XXX
 SG_ HVBusLowSideResistorConnectReq : 16|2@1+ (1,0) [0|3] "" Vector__XXX
 SG_ HVBusHiSideResistorConnectReq : 14|2@1+ (1,0) [0|3] "" Vector__XXX
 SG_ OpConsent : 12|2@1+ (1,0) [0|3] "" Vector__XXX
 SG_ EnableInternalChargerCmd : 10|2@1+ (1,0) [0|3] "" Vector__XXX
 SG_ CellBalancingCmd : 8|2@1+ (1,0) [0|3] "" Vector__XXX
 SG_ HVBusPassiveIsolTestCmd : 6|2@1+ (1,0) [0|3] "" Vector__XXX
 SG_ HVBusActiveIsolTestCmd : 4|2@1+ (1,0) [0|3] "" Vector__XXX
 SG_ PwrDownCmd : 2|2@1+ (1,0) [0|3] "" Vector__XXX
 SG_ HVBusConnectCmd : 0|2@1+ (1,0) [0|3] "" Vector__XXX

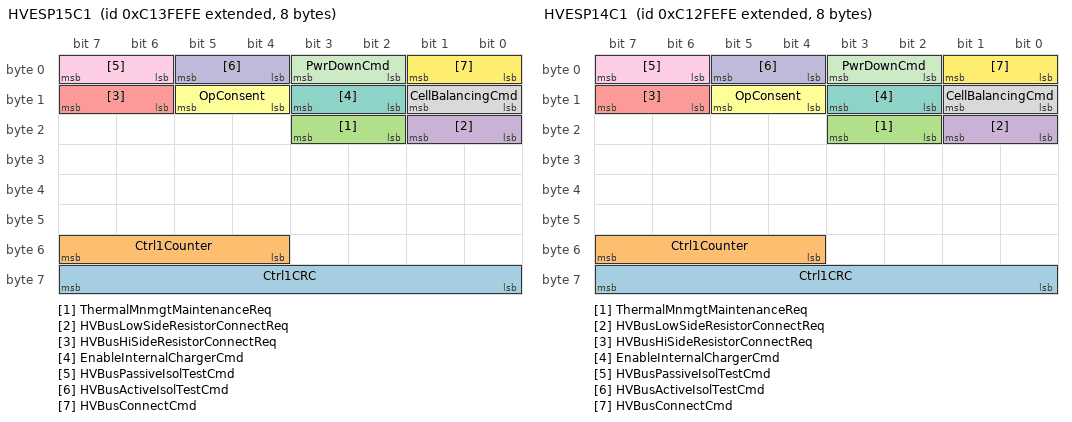
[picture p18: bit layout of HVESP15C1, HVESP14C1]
BO_ 2350120702 HVESP15C1: 8 Vector__XXX
 SG_ Ctrl1CRC : 56|8@1+ (1,0) [0|255] "" Vector__XXX
 SG_ Ctrl1Counter : 52|4@1+ (1,0) [0|15] "" Vector__XXX
 SG_ ThermalMnmgtMaintenanceReq : 18|2@1+ (1,0) [0|3] "" Vector__XXX
 SG_ HVBusLowSideResistorConnectReq : 16|2@1+ (1,0) [0|3] "" Vector__XXX
 SG_ HVBusHiSideResistorConnectReq : 14|2@1+ (1,0) [0|3] "" Vector__XXX
 SG_ OpConsent : 12|2@1+ (1,0) [0|3] "" Vector__XXX
 SG_ EnableInternalChargerCmd : 10|2@1+ (1,0) [0|3] "" Vector__XXX
 SG_ CellBalancingCmd : 8|2@1+ (1,0) [0|3] "" Vector__XXX
 SG_ HVBusPassiveIsolTestCmd : 6|2@1+ (1,0) [0|3] "" Vector__XXX
 SG_ HVBusActiveIsolTestCmd : 4|2@1+ (1,0) [0|3] "" Vector__XXX
 SG_ PwrDownCmd : 2|2@1+ (1,0) [0|3] "" Vector__XXX
 SG_ HVBusConnectCmd : 0|2@1+ (1,0) [0|3] "" Vector__XXX

BO_ 2350055166 HVESP14C1: 8 Vector__XXX
 SG_ Ctrl1CRC : 56|8@1+ (1,0) [0|255] "" Vector__XXX
 SG_ Ctrl1Counter : 52|4@1+ (1,0) [0|15] "" Vector__XXX
 SG_ ThermalMnmgtMaintenanceReq : 18|2@1+ (1,0) [0|3] "" Vector__XXX
 SG_ HVBusLowSideResistorConnectReq : 16|2@1+ (1,0) [0|3] "" Vector__XXX
 SG_ HVBusHiSideResistorConnectReq : 14|2@1+ (1,0) [0|3] "" Vector__XXX
 SG_ OpConsent : 12|2@1+ (1,0) [0|3] "" Vector__XXX
 SG_ EnableInternalChargerCmd : 10|2@1+ (1,0) [0|3] "" Vector__XXX
 SG_ CellBalancingCmd : 8|2@1+ (1,0) [0|3] "" Vector__XXX
 SG_ HVBusPassiveIsolTestCmd : 6|2@1+ (1,0) [0|3] "" Vector__XXX
 SG_ HVBusActiveIsolTestCmd : 4|2@1+ (1,0) [0|3] "" Vector__XXX
 SG_ PwrDownCmd : 2|2@1+ (1,0) [0|3] "" Vector__XXX
 SG_ HVBusConnectCmd : 0|2@1+ (1,0) [0|3] "" Vector__XXX

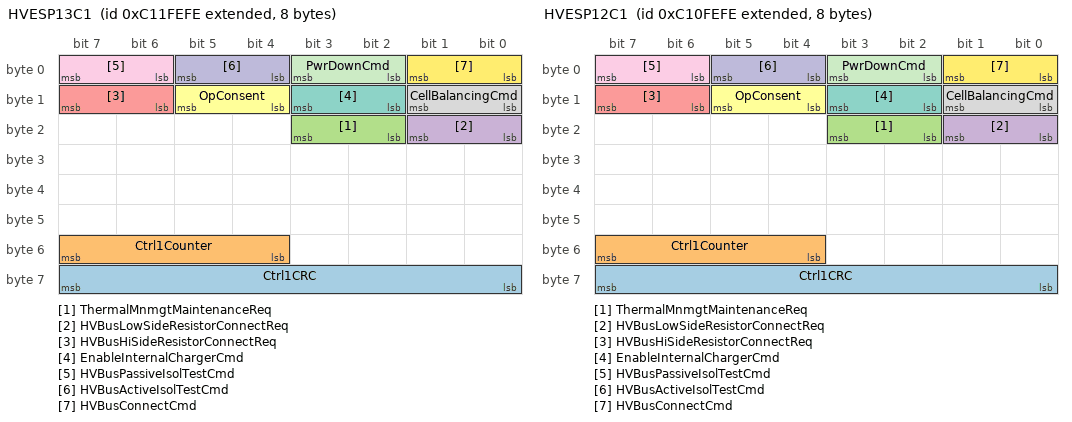
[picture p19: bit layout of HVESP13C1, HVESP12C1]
BO_ 2349989630 HVESP13C1: 8 Vector__XXX
 SG_ Ctrl1CRC : 56|8@1+ (1,0) [0|255] "" Vector__XXX
 SG_ Ctrl1Counter : 52|4@1+ (1,0) [0|15] "" Vector__XXX
 SG_ ThermalMnmgtMaintenanceReq : 18|2@1+ (1,0) [0|3] "" Vector__XXX
 SG_ HVBusLowSideResistorConnectReq : 16|2@1+ (1,0) [0|3] "" Vector__XXX
 SG_ HVBusHiSideResistorConnectReq : 14|2@1+ (1,0) [0|3] "" Vector__XXX
 SG_ OpConsent : 12|2@1+ (1,0) [0|3] "" Vector__XXX
 SG_ EnableInternalChargerCmd : 10|2@1+ (1,0) [0|3] "" Vector__XXX
 SG_ CellBalancingCmd : 8|2@1+ (1,0) [0|3] "" Vector__XXX
 SG_ HVBusPassiveIsolTestCmd : 6|2@1+ (1,0) [0|3] "" Vector__XXX
 SG_ HVBusActiveIsolTestCmd : 4|2@1+ (1,0) [0|3] "" Vector__XXX
 SG_ PwrDownCmd : 2|2@1+ (1,0) [0|3] "" Vector__XXX
 SG_ HVBusConnectCmd : 0|2@1+ (1,0) [0|3] "" Vector__XXX

BO_ 2349924094 HVESP12C1: 8 Vector__XXX
 SG_ Ctrl1CRC : 56|8@1+ (1,0) [0|255] "" Vector__XXX
 SG_ Ctrl1Counter : 52|4@1+ (1,0) [0|15] "" Vector__XXX
 SG_ ThermalMnmgtMaintenanceReq : 18|2@1+ (1,0) [0|3] "" Vector__XXX
 SG_ HVBusLowSideResistorConnectReq : 16|2@1+ (1,0) [0|3] "" Vector__XXX
 SG_ HVBusHiSideResistorConnectReq : 14|2@1+ (1,0) [0|3] "" Vector__XXX
 SG_ OpConsent : 12|2@1+ (1,0) [0|3] "" Vector__XXX
 SG_ EnableInternalChargerCmd : 10|2@1+ (1,0) [0|3] "" Vector__XXX
 SG_ CellBalancingCmd : 8|2@1+ (1,0) [0|3] "" Vector__XXX
 SG_ HVBusPassiveIsolTestCmd : 6|2@1+ (1,0) [0|3] "" Vector__XXX
 SG_ HVBusActiveIsolTestCmd : 4|2@1+ (1,0) [0|3] "" Vector__XXX
 SG_ PwrDownCmd : 2|2@1+ (1,0) [0|3] "" Vector__XXX
 SG_ HVBusConnectCmd : 0|2@1+ (1,0) [0|3] "" Vector__XXX

CM_ BO_ 2364691710 "High Voltage Energy Storage Pack 11 Data 3
Data set 3 (thermal data) for High Voltage Energy Storage Pack 11.";
CM_ SG_ 2364691710 CellTempDiffStatus "Indicates whether or not the differential between the highest and lowest cell temperatures are within acceptable limits per this High Voltage Energy Storage Pack instance. The actual temperature differential can be calculated by subtracting SPN ...";
CM_ SG_ 2364691710 AvgCellTemp "The average temperature level of all cells in this High Voltage Energy Storage Pack instance.
This parameter is for one of multiple packs in an HVESS.  If there is only one pack in the system, the HVESS parameters should be used.  If there are ...";
CM_ SG_ 2364691710 LowestCellTemp "The lowest temperature level reported by any cell in this High Voltage Energy Storage Pack instance. If a single temperature sensor covers more than one cell, the value in this parameter is for the smallest group of cells measured. See SPN 15384 ...";
CM_ SG_ 2364691710 HighestCellTemp "The highest temperature level reported by any cell in this High Voltage Energy Storage Pack instance. If a single temperature sensor covers more than one cell, the value in this parameter is for the smallest group of cells measured. See SPN 15382 ...";
CM_ BO_ 2364691454 "High Voltage Energy Storage Pack 11 Data 2
Data set 2 (electrical data) for High Voltage Energy Storage Pack 11.";
CM_ SG_ 2364691454 CellVDiffStatus "Indicates whether or not the differential between the highest and lowest cell voltages are within acceptable limits, according to this High Voltage Energy Storage Pack instance. The actual voltage differential can be calculated by subtracting SPN ...";
CM_ SG_ 2364691454 LowestCellV "The lowest voltage level reported by any cell in this High Voltage Energy Storage Pack instance. If a single voltage sensor covers more than one cell, the value in this parameter is for the smallest group of cells measured. See SPN 15379 (HVESP11 ...";
CM_ SG_ 2364691454 HighestCellV "The highest voltage level reported by any cell in this High Voltage Energy Storage Pack instance. If a single voltage sensor covers more than one cell, the value in this parameter is for the smallest group of cells measured. See SPN 15377 (HVESP11 ...";
CM_ SG_ 2364691454 FastUpdateStOfCharge "Indicates this High Voltage Energy Storage Pack instance state of charge. 0% means no charge remaining, 100% means the system is fully charged in terms of physical limits of this energy storage pack instance. Acceptable state of charge upper and ...";
CM_ BO_ 2364691198 "High Voltage Energy Storage Pack 11 Data 1
Data set 1 (electrical data) for High Voltage Energy Storage Pack 11.";
CM_ SG_ 2364691198 Cur "The current in or out of this High Voltage Energy Storage Pack instance. This parameter should be synchronized with SPN 15294 (HVESP11 Voltage Level) such that a realized power value can be calculated. This parameter is defined from the high voltage ...";
CM_ SG_ 2364691198 Lvl "The voltage level of this High Voltage Energy Storage Pack instance. This parameter should be synchronized with SPN 15295 (HVESP11 Current) such that a realized power value can be calculated. If the HVES component physically contains the contactors ...";
CM_ SG_ 2364691198 AvailableChargePwr "The rate at which this High Voltage Energy Storage Pack instance can currently receive energy from a regenerative or recharging system.
This parameter is for one of multiple packs in an HVESS.  If there is only one pack in the system, the HVESS ...";
CM_ SG_ 2364691198 AvailableDisPwr "The rate at which this High Voltage Energy Storage Pack instance can currently provide energy for propulsion or other uses.
This parameter is for one of multiple packs in an HVESS.  If there is only one pack in the system, the HVESS parameters ...";
CM_ BO_ 2364690942 "High Voltage Energy Storage Pack 11 Status 2
Status data set 2 for High Voltage Energy Storage Pack 11.";
CM_ SG_ 2364690942 ChargePLDueToAnUndefinedCause "Indicates whether or not charge power of this HVES instance is being limited due to an undefined cause.
This parameter is for one of multiple packs in an HVESS.  If there is only one pack in the system, the HVESS parameters should be used. If there ...";
CM_ SG_ 2364690942 ChargePLDueToBatCur "Indicates whether or not charge power of this HVES instance is being limited due to battery current.
This parameter is for one of multiple packs in an HVESS.  If there is only one pack in the system, the HVESS parameters should be used. If there ...";
CM_ SG_ 2364690942 ChargePLDueToBatOrCellV "Indicates whether or not charge power of this HVES instance is being limited due to a battery or cell voltage level.
This parameter is for one of multiple packs in an HVESS.  If there is only one pack in the system, the HVESS parameters should be ...";
CM_ SG_ 2364690942 ChargePLDueToBatDiagCondition "Indicates whether or not charge power of this HVES instance is being limited due to a battery diagnostic condition.
This parameter is for one of multiple packs in an HVESS.  If there is only one pack in the system, the HVESS parameters should be ...";
CM_ SG_ 2364690942 ChargePLDueToBatTemp "Indicates whether or not charge power of this HVES instance is being limited due to battery temperature.
This parameter is for one of multiple packs in an HVESS.  If there is only one pack in the system, the HVESS parameters should be used. If ...";
CM_ SG_ 2364690942 ChargePLDueToStOfCharge "Indicates whether or not charge power of this HVES instance is being limited due to state of charge.
This parameter is for one of multiple packs in an HVESS.  If there is only one pack in the system, the HVESS parameters should be used. If there ...";
CM_ SG_ 2364690942 DisPLDueToAnUndefinedCause "Indicates whether or not discharge power of this HVES instance is being limited due to an undefined cause.
This parameter is for one of multiple packs in an HVESS.  If there is only one pack in the system, the HVESS parameters should be used. If ...";
CM_ SG_ 2364690942 DisPLDueToBatCur "Indicates whether or not discharge power of this HVES instance is being limited due to battery current.
This parameter is for one of multiple packs in an HVESS.  If there is only one pack in the system, the HVESS parameters should be used. If there ...";
CM_ SG_ 2364690942 DisPLDueToBatOrCellV "Indicates whether or not discharge power of this HVES instance is being limited due to a battery or cell voltage level.
This parameter is for one of multiple packs in an HVESS.  If there is only one pack in the system, the HVESS parameters should ...";
CM_ SG_ 2364690942 DisPLDueToBatDiagCondition "Indicates whether or not discharge power of this HVES instance is being limited due to a battery diagnostic condition.
This parameter is for one of multiple packs in an HVESS.  If there is only one pack in the system, the HVESS parameters should be ...";
CM_ SG_ 2364690942 DisPLDueToBatTemp "Indicates whether or not discharge power of this HVES instance is being limited due to battery temperature.
This parameter is for one of multiple packs in an HVESS.  If there is only one pack in the system, the HVESS parameters should be used. If ...";
CM_ SG_ 2364690942 DisPLDueToStOfCharge "Indicates whether or not discharge power of this HVES instance is being limited due to state of charge.
This parameter is for one of multiple packs in an HVESS.  If there is only one pack in the system, the HVESS parameters should be used. If there ...";
CM_ BO_ 2364690686 "Electronic Auxiliary Transmission Controller 1
Information pertaining to an Electronic Auxiliary Transmission.";
CM_ SG_ 2364690686 OutSpd "Auxiliary transmission output speed";
CM_ BO_ 2364573438 "Power Converter 1 Status 1
First Status Message from the Power Converter.   An example would be for use with an HVESS.";
CM_ SG_ 2364573438 DCES1V "The measured or estimated DC Energy Source 1 voltage.  

Refer to SPN 20691 (Power Converter 1 Reference Voltage) to convert % to Volts.";
CM_ SG_ 2364573438 DCES1Cur "This is the DC Energy Source 1 current of the Power Converter.
Refer to SPN 20690 (Power Converter 1 Reference Current) to convert % to Amps.
While systeming, the current is defined as positive.  For example, in a hybrid propulsion system, ...";
CM_ SG_ 2364573438 Freq "The measured or estimated system frequency.  This refers to the system rotor output and excludes any gearbox that may be attached to the system.   

Refer to SPN 20701 (Power Converter 1 Reference Frequency) to convert % to Hz.";
CM_ SG_ 2364573438 Cur "The measured or estimated system current.  This refers to the system rotor output and excludes any gearbox that may be attached to the system.
Refer to SPN 20690 (Power Converter 1 Reference Current) to convert % to A.
The system is generating ...";
CM_ SG_ 2364573438 Counter "The message counter is used to detect situations where the transmitting ECU malfunction repeats the same frame all the time. The receiver of the information may use the counter parameter to detect this situation. The transmitting device will ...";
CM_ SG_ 2364573438 CRC "The CRC is defined as follows:
• Length: 8 bits
• Polynomial: x^8+x^5+x^3+x^2+x+1
• Initial Value: FFh
• Input Data Reflection: Not reflected
• Result Data Reflection: Not reflected
• XOR value: FFh
SAE makes no claim of the functional safety ...";
CM_ BO_ 2364573182 "Power Converter 2 Status 1
First Status Message from the Power Converter.   An example would be for use with an HVESS.";
CM_ SG_ 2364573182 DCES1V "The measured or estimated DC Energy Source 1 voltage.  

Refer to SPN 20679 (Power Converter 2 Reference Voltage) to convert % to Volts.";
CM_ SG_ 2364573182 DCES1Cur "This is the DC Energy Source 1 current of the Power Converter.
Refer to SPN 20667 (Power Converter 2 Reference Current) to convert % to Amps.
While systeming, the current is defined as positive.  For example, in a hybrid propulsion system, ...";
CM_ SG_ 2364573182 Freq "The measured or estimated system frequency.  This refers to the system rotor output and excludes any gearbox that may be attached to the system.
Refer to SPN 20668 (Power Converter 2 Reference Frequency) to convert % to Hz.
The system is ...";
CM_ SG_ 2364573182 Cur "The measured or estimated system current.  This refers to the system rotor output and excludes any gearbox that may be attached to the system.
Refer to SPN 20667 (Power Converter 2 Reference Current) to convert % to A.
The system is generating ...";
CM_ SG_ 2364573182 Counter "The message counter is used to detect situations where the transmitting ECU malfunction repeats the same frame all the time. The receiver of the information may use the counter parameter to detect this situation. The transmitting device will ...";
CM_ SG_ 2364573182 CRC "The CRC is defined as follows:
• Length: 8 bits
• Polynomial: x^8+x^5+x^3+x^2+x+1
• Initial Value: FFh
• Input Data Reflection: Not reflected
• Result Data Reflection: Not reflected
• XOR value: FFh
SAE makes no claim of the functional safety ...";
CM_ BO_ 2565899518 "Power Converter 1 Isolation Integrity
The electrical isolation Integrity status of the Power Converter.   An example would be for use with an HVESS.";
CM_ SG_ 2565899518 HVBusPassiveIsolTestResults "The isolation resistance that resulted from the High-Voltage Bus Passive Isolation Test.
See SPN 20662 (Power Converter 1 High-Voltage Bus Passive Isolation Test Status) for test status and SPN 20504(Power Converter 1 High-Voltage Bus Passive ...";
CM_ SG_ 2565899518 HVBusActiveIsolTestResults "The isolation resistance that resulted from the High-Voltage Bus Active Isolation Test.
See SPN 20661 (Power Converter 1 High-Voltage Bus Active Isolation Test Status) for test status and SPN 20503 (Power Converter 1 High-Voltage Bus Active ...";
CM_ SG_ 2565899518 HVBusPassiveIsolTestStatus "Status of the high-voltage bus electrical passive isolation test as performed by this instance of the Power Converter.
0000b = No test requested / No test in process
0001b = Test requested but not yet in process
0010b = Test in process
0011b = ...";
CM_ SG_ 2565899518 HVBusActiveIsolTestStatus "Status of the high-voltage bus electrical active isolation test as performed by this instance of the Power Converter.
0000b = No test requested / No test in process
0001b = Test requested but not yet in process
0010b = Test in process
0011b = ...";
CM_ SG_ 2565899518 DCES1NegToChassisGroundV "The voltage level of the high voltage DC Energy Source 1, as measured by the Power Converter between the negative side of the High Voltage DC Energy Source 1 input and the chassis of the Power Converter enclosure.  This voltage can be used for ...";
CM_ SG_ 2565899518 Counter "The message counter is used to detect situations where the transmitting ECU malfunction repeats the same frame all the time. The receiver of the information may use the counter parameter to detect this situation. The transmitting device will ...";
CM_ SG_ 2565899518 CRC "The CRC is defined as follows:
• Length: 8 bits
• Polynomial: x^8+x^5+x^3+x^2+x+1
• Initial Value: FFh
• Input Data Reflection: Not reflected
• Result Data Reflection: Not reflected
• XOR value: FFh
SAE makes no claim of the functional safety ...";
CM_ BO_ 2565899262 "Power Converter 2 Isolation Integrity
The electrical isolation Integrity status of the Power Converter.   An example would be for use with an HVESS.";
CM_ SG_ 2565899262 HVBusPassiveIsolTestResults "The isolation resistance that resulted from the High-Voltage Bus Passive Isolation Test.
See SPN 20637 (Power Converter 2 High-Voltage Bus Passive Isolation Test Status) for test status and SPN 20500 (Power Converter 2 High-Voltage Bus Passive ...";
CM_ SG_ 2565899262 HVBusActiveIsolTestResults "The isolation resistance that resulted from the High-Voltage Bus Active Isolation Test.
See SPN 20636 (Power Converter 2 High-Voltage Bus Active Isolation Test Status) for test status and SPN 20499 (Power Converter 2 High-Voltage Bus Active ...";
CM_ SG_ 2565899262 HVBusPassiveIsolTestStatus "Status of the high-voltage bus electrical passive isolation test as performed by this instance of the Power Converter.
0000b = No test requested / No test in process
0001b = Test requested but not yet in process
0010b = Test in process
0011b = ...";
CM_ SG_ 2565899262 HVBusActiveIsolTestStatus "Status of the high-voltage bus electrical active isolation test as performed by this instance of the Power Converter.
0000b = No test requested / No test in process
0001b = Test requested but not yet in process
0010b = Test in process
0011b = ...";
CM_ SG_ 2565899262 DCES1NegToChassisGroundV "The voltage level of the high voltage DC Energy Source 1, as measured by the Power Converter between the negative side of the High Voltage DC Energy Source 1 input and the chassis of the Power Converter enclosure.  This voltage can be used for ...";
CM_ SG_ 2565899262 Counter "The message counter is used to detect situations where the transmitting ECU malfunction repeats the same frame all the time. The receiver of the information may use the counter parameter to detect this situation. The transmitting device will ...";
CM_ SG_ 2565899262 CRC "The CRC is defined as follows:
• Length: 8 bits
• Polynomial: x^8+x^5+x^3+x^2+x+1
• Initial Value: FFh
• Input Data Reflection: Not reflected
• Result Data Reflection: Not reflected
• XOR value: FFh
SAE makes no claim of the functional safety ...";
CM_ BO_ 2565899006 "Power Converter 2 Rate Limits Active 1
Reports the active rate limits for this instance of inverter being controlled.  An example would be for use with an HVESS.";
CM_ SG_ 2565899006 AbsCurRateLmt "the Power Converter reports its active maximum rate of change for the absolute system current (i.e. |d(current)|/dt) in all control modes.
Refer to SPN 20667 (Power Converter 2 Reference Current) to convert %/sec to A/sec.
(Power Converter 2 ...";
CM_ SG_ 2565899006 Counter "The message counter is used to detect situations where the transmitting ECU malfunction repeats the same frame all the time. The receiver of the information may use the counter parameter to detect this situation. The transmitting device will ...";
CM_ SG_ 2565899006 CRC "The CRC is defined as follows:
• Length: 8 bits
• Polynomial: x^8+x^5+x^3+x^2+x+1
• Initial Value: FFh
• Input Data Reflection: Not reflected
• Result Data Reflection: Not reflected
• XOR value: FFh
SAE makes no claim of the functional safety ...";
CM_ BO_ 2565898750 "Power Converter 2 Status 2
Second Status Message from the Power Converter.   An example would be for use with an HVESS.";
CM_ SG_ 2565898750 AvailableMinCur "This is an estimate of the minimum available system current including active deratings.
Refer to SPN 20667 (Power Converter 2 Reference Current) to convert % to A.
The system is regenerating when SPN 20673(Power Converter 2 Frequency) and SPN ...";
CM_ SG_ 2565898750 AvailableMaxCur "This is an estimate of the maximum available system current including active deratings.
Refer to SPN 20667 (Power Converter 2 Reference Current) to convert % to A.
The system is regenerating when SPN 20673(Power Converter 2 Frequency) and SPN ...";
CM_ SG_ 2565898750 Counter "The message counter is used to detect situations where the transmitting ECU malfunction repeats the same frame all the time. The receiver of the information may use the counter parameter to detect this situation. The transmitting device will ...";
CM_ SG_ 2565898750 CRC "The CRC is defined as follows:
• Length: 8 bits
• Polynomial: x^8+x^5+x^3+x^2+x+1
• Initial Value: FFh
• Input Data Reflection: Not reflected
• Result Data Reflection: Not reflected
• XOR value: FFh
SAE makes no claim of the functional safety ...";
CM_ BO_ 2565898494 "Power Converter 1 Rate Limits Active 1
Reports the active rate limits for this instance of inverter being controlled.  An example would be for use with an HVESS.";
CM_ SG_ 2565898494 AbsCurRateLmt "The active maximum rate of change for the absolute system current (i.e. |d(current)|/dt) in all control modes of this Power Converter instance.
Refer to SPN 20690 (Power Converter 1 Reference Current) to convert %/sec to A/sec.
(Current Rate Limit ...";
CM_ SG_ 2565898494 Counter "The message counter is used to detect situations where the transmitting ECU malfunction repeats the same frame all the time. The receiver of the information may use the counter parameter to detect this situation. The transmitting device will ...";
CM_ SG_ 2565898494 CRC "The CRC is defined as follows:
• Length: 8 bits
• Polynomial: x^8+x^5+x^3+x^2+x+1
• Initial Value: FFh
• Input Data Reflection: Not reflected
• Result Data Reflection: Not reflected
• XOR value: FFh
SAE makes no claim of the functional safety ...";
CM_ BO_ 2565898238 "Power Converter 1 Status 2
Second Status Message from the Power Converter.   An example would be for use with an HVESS.";
CM_ SG_ 2565898238 AvailableMinCur "This is an estimate of the minimum available system current including active deratings.
Refer to SPN 20690 (Power Converter 1 Reference Current) to convert % to A.
The system is regenerating when SPN 20695(Power Converter 1 Frequency) and SPN ...";
CM_ SG_ 2565898238 AvailableMaxCur "This is an estimate of the maximum available system current including active deratings.
Refer to SPN 20690 (Power Converter 1 Reference Current) to convert % to A.
The system is regenerating when SPN 20695(Power Converter 1 Frequency) and SPN ...";
CM_ SG_ 2565898238 Counter "The message counter is used to detect situations where the transmitting ECU malfunction repeats the same frame all the time. The receiver of the information may use the counter parameter to detect this situation. The transmitting device will ...";
CM_ SG_ 2565898238 CRC "The CRC is defined as follows:
• Length: 8 bits
• Polynomial: x^8+x^5+x^3+x^2+x+1
• Initial Value: FFh
• Input Data Reflection: Not reflected
• Result Data Reflection: Not reflected
• XOR value: FFh
SAE makes no claim of the functional safety ...";
CM_ BO_ 2565897982 "Power Converter 2 Low Voltage
Low Voltage data from this Power Converter.";
CM_ SG_ 2565897982 UnswitchedSLIV "Continuously supplied SLI power to this instance of the Power Converter controller.";
CM_ SG_ 2565897982 SwitchedIgntV "Switched Ignition voltage supplied to this instance of the Power Converter controller.";
CM_ BO_ 2565897726 "Power Converter 2 Limits Active DC Energy Source 1
The DC Energy Source 1 electrical limits the Power Converter is actually using.  These may differ from the requested limits.";
CM_ SG_ 2565897726 CurMin "the Power Converter keeps the DC Energy Source 1 current above this value.  This limit may be set in response to a Limits Request or determined by the Power Converter based on operating conditions.
Refer to SPN 20667 (Power Converter 2 Reference ...";
CM_ SG_ 2565897726 CurMax "the Power Converter keeps the DC Energy Source 1 current below this value.  This limit may be set in response to a Limits Request or determined by the Power Converter based on operating conditions.
Refer to SPN 20667 (Power Converter 2 Reference ...";
CM_ SG_ 2565897726 VMin "the Power Converter keeps the DC Energy Source 1 voltage above this value.  This limit may be set in response to a Limits Request or determined by the Power Converter based on operating conditions.
Refer to SPN 20679 (Power Converter 2 Reference ...";
CM_ SG_ 2565897726 VMax "the Power Converter keeps the DC Energy Source 1 voltage below this value.  This limit may be set in response to a Limits Request or determined by the Power Converter based on operating conditions.
Refer to SPN 20679 (Power Converter 2 Reference ...";
CM_ SG_ 2565897726 Counter "The message counter is used to detect situations where the transmitting ECU malfunction repeats the same frame all the time. The receiver of the information may use the counter parameter to detect this situation. The transmitting device will ...";
CM_ SG_ 2565897726 CRC "The CRC is defined as follows:
• Length: 8 bits
• Polynomial: x^8+x^5+x^3+x^2+x+1
• Initial Value: FFh
• Input Data Reflection: Not reflected
• Result Data Reflection: Not reflected
• XOR value: FFh
SAE makes no claim of the functional safety ...";
CM_ BO_ 2565897470 "Power Converter 2 Limits Active Electrical
The Current and Frequency limits the Power Converter is actually using.  These may differ from the requested limits.";
CM_ SG_ 2565897470 FreqMin "the Power Converter keeps the system Frequency above this value.  This limit may be set in response to a Limits Request or determined by the Power Converter based on operating conditions.
Refer to SPN 20668 (Power Converter 2 Reference Frequency) ...";
CM_ SG_ 2565897470 FreqMax "the Power Converter keeps the system frequency below this value.  This limit may be set in response to a Limits Request or determined by the Power Converter based on operating conditions.
Refer to SPN 20668 (Power Converter 2 Reference Frequency) ...";
CM_ SG_ 2565897470 CurMin "the Power Converter keeps the system current above this value.  This limit may be set in response to a Limits Request or determined by the Power Converter based on operating conditions.
Refer to SPN 20667 (Power Converter 2 Reference Current) to ...";
CM_ SG_ 2565897470 CurMax "the Power Converter keeps the system current below this value.  This limit may be set in response to a Limits Request or determined by the Power Converter based on operating conditions.
Refer to SPN 20667 (Power Converter 2 Reference Current) to ...";
CM_ SG_ 2565897470 Counter "The message counter is used to detect situations where the transmitting ECU malfunction repeats the same frame all the time. The receiver of the information may use the counter parameter to detect this situation. The transmitting device will ...";
CM_ SG_ 2565897470 CRC "The CRC is defined as follows:
• Length: 8 bits
• Polynomial: x^8+x^5+x^3+x^2+x+1
• Initial Value: FFh
• Input Data Reflection: Not reflected
• Result Data Reflection: Not reflected
• XOR value: FFh
SAE makes no claim of the functional safety ...";
CM_ BO_ 2565897214 "Power Converter 2 Limits Active Power
The electrical and electrical power limits the Power Converter is actually using.  These may differ from the requested limits.";
CM_ SG_ 2565897214 DCES1PwrMin "the Power Converter keeps the DC Energy Source 1 power above this value.   This limit may be set in response to a Limits Request or determined by the Power Converter based on operating conditions.
Refer to SPN 20669 (Power Converter 2 Reference ...";
CM_ SG_ 2565897214 DCES1PwrMax "the Power Converter keeps the DC Energy Source 1 power below this value.   This limit may be set in response to a Limits Request or determined by the Power Converter based on operating conditions.
Refer to SPN 20669 (Power Converter 2 Reference ...";
CM_ SG_ 2565897214 ElectricalPwrMin "the Power Converter keeps the electrical system power above this value.   This limit may be set in response to a Limits Request or determined by the Power Converter based on operating conditions.
Refer to SPN 20669 (Power Converter 2 Reference ...";
CM_ SG_ 2565897214 ElectricalPwrMax "the Power Converter keeps the electrical system power below this value.   This limit may be set in response to a Limits Request or determined by the Power Converter based on operating conditions.
Refer to SPN 20669 (Power Converter 2 Reference ...";
CM_ SG_ 2565897214 Counter "The message counter is used to detect situations where the transmitting ECU malfunction repeats the same frame all the time. The receiver of the information may use the counter parameter to detect this situation. The transmitting device will ...";
CM_ SG_ 2565897214 CRC "The CRC is defined as follows:
• Length: 8 bits
• Polynomial: x^8+x^5+x^3+x^2+x+1
• Initial Value: FFh
• Input Data Reflection: Not reflected
• Result Data Reflection: Not reflected
• XOR value: FFh
SAE makes no claim of the functional safety ...";
CM_ BO_ 2364570366 "Power Converter 2 Mode Feedback 1
The first mode feedback message from the Power Converter.";
CM_ SG_ 2364570366 HVILStatus "Reports the High Voltage Interlock Loop (HVIL) state.

00b = HVIL Closed
01b = HVIL Open
10b = Error
11b = Not Available";
CM_ SG_ 2364570366 CtrlSetpointMode "Reports the Power Converter mode (See SPN 20477 (Power Converter 2 Control Setpoint Mode Request) for requested mode).
Passive modes:
0 = Powered On - the Power Converter is commanded to be powered on and able to communicate, but the Power Stage ...";
CM_ SG_ 2364570366 CtrlLimitsOvrdMode "During normal operation this will have the same value as SPN 20474 (Power Converter 2 Control Limits Request Override Mode).
0 = Operating limits are not overridden.  If a limit was previously active, then it has reverted to its normal value as ...";
CM_ SG_ 2364570366 Counter "The message counter is used to detect situations where the transmitting ECU malfunction repeats the same frame all the time. The receiver of the information may use the counter parameter to detect this situation. The transmitting device will ...";
CM_ SG_ 2364570366 CRC "The CRC is defined as follows:
• Length: 8 bits
• Polynomial: x^8+x^5+x^3+x^2+x+1
• Initial Value: FFh
• Input Data Reflection: Not reflected
• Result Data Reflection: Not reflected
• XOR value: FFh
SAE makes no claim of the functional safety ...";
CM_ BO_ 2565896702 "Power Converter 1 Low Voltage
Low Voltage data from this Power Converter.";
CM_ SG_ 2565896702 UnswitchedSLIV "Continuously supplied SLI power to this instance of the Power Converter controller.";
CM_ SG_ 2565896702 SwitchedIgntV "Switched Ignition voltage supplied to this instance of the Power Converter controller.";
CM_ BO_ 2565896446 "Power Converter 1 Limits Active DC Energy Source 1
The DC Energy Source 1 electrical limits the Power Converter is actually using.  These may differ from the requested limits.";
CM_ SG_ 2565896446 CurMin "the Power Converter keeps the DC Energy Source 1 current above this value.  This limit may be set in response to a Limits Request or determined by the Power Converter based on operating conditions.
Refer to SPN 20690 (Power Converter 1 Reference ...";
CM_ SG_ 2565896446 CurMax "the Power Converter keeps the DC Energy Source 1 current below this value.  This limit may be set in response to a Limits Request or determined by the Power Converter based on operating conditions.
Refer to SPN 20690 (Power Converter 1 Reference ...";
CM_ SG_ 2565896446 VMin "the Power Converter keeps the DC Energy Source 1 voltage above this value.  This limit may be set in response to a Limits Request or determined by the Power Converter based on operating conditions.
Refer to SPN 20691 (Power Converter 1 Reference ...";
CM_ SG_ 2565896446 VMax "the Power Converter keeps the DC Energy Source 1 voltage below this value.  This limit may be set in response to a Limits Request or determined by the Power Converter based on operating conditions.
Refer to SPN 20691 (Power Converter 1 Reference ...";
CM_ SG_ 2565896446 Counter "The message counter is used to detect situations where the transmitting ECU malfunction repeats the same frame all the time. The receiver of the information may use the counter parameter to detect this situation. The transmitting device will ...";
CM_ SG_ 2565896446 CRC "The CRC is defined as follows:
• Length: 8 bits
• Polynomial: x^8+x^5+x^3+x^2+x+1
• Initial Value: FFh
• Input Data Reflection: Not reflected
• Result Data Reflection: Not reflected
• XOR value: FFh
SAE makes no claim of the functional safety ...";
CM_ BO_ 2565896190 "Power Converter 1 Limits Active Electrical
The Current and Frequency limits the Power Converter is actually using.  These may differ from the requested limits.";
CM_ SG_ 2565896190 FreqMin "the Power Converter keeps the system Frequency above this value.  This limit may be set in response to a Limits Request or determined by the Power Converter based on operating conditions.
Refer to SPN 20701 (Power Converter 1 Reference Frequency) ...";
CM_ SG_ 2565896190 FreqMax "the Power Converter keeps the system frequency below this value.  This limit may be set in response to a Limits Request or determined by the Power Converter based on operating conditions.
Refer to SPN 20701 (Power Converter 1 Reference Frequency) ...";
CM_ SG_ 2565896190 CurMin "the Power Converter keeps the system current above this value.  This limit may be set in response to a Limits Request or determined by the Power Converter based on operating conditions.
Refer to SPN 20690 (Power Converter 1 Reference Current) to ...";
CM_ SG_ 2565896190 CurMax "the Power Converter keeps the system current below this value.  This limit may be set in response to a Limits Request or determined by the Power Converter based on operating conditions.
Refer to SPN 20690 (Power Converter 1 Reference Current) to ...";
CM_ SG_ 2565896190 Counter "The message counter is used to detect situations where the transmitting ECU malfunction repeats the same frame all the time. The receiver of the information may use the counter parameter to detect this situation. The transmitting device will ...";
CM_ SG_ 2565896190 CRC "The CRC is defined as follows:
• Length: 8 bits
• Polynomial: x^8+x^5+x^3+x^2+x+1
• Initial Value: FFh
• Input Data Reflection: Not reflected
• Result Data Reflection: Not reflected
• XOR value: FFh
SAE makes no claim of the functional safety ...";
CM_ BO_ 2565895934 "Power Converter 1 Limits Active Power
The electrical and electrical power limits the Power Converter is actually using.  These may differ from the requested limits.";
CM_ SG_ 2565895934 DCES1PwrMin "the Power Converter keeps the DC Energy Source 1 power above this value.   This limit may be set in response to a Limits Request or determined by the Power Converter based on operating conditions.
Refer to SPN 20702 (Power Converter 1 Reference ...";
CM_ SG_ 2565895934 DCES1PwrMax "the Power Converter keeps the DC Energy Source 1 power below this value.   This limit may be set in response to a Limits Request or determined by the Power Converter based on operating conditions.
Refer to SPN 20702 (Power Converter 1 Reference ...";
CM_ SG_ 2565895934 ElectricalPwrMin "the Power Converter keeps the electrical system power above this value.   This limit may be set in response to a Limits Request or determined by the Power Converter based on operating conditions.
Refer to SPN 20702 (Power Converter 1 Reference ...";
CM_ SG_ 2565895934 ElectricalPwrMax "the Power Converter keeps the electrical system power below this value.   This limit may be set in response to a Limits Request or determined by the Power Converter based on operating conditions.
Refer to SPN 20702 (Power Converter 1 Reference ...";
CM_ SG_ 2565895934 Counter "The message counter is used to detect situations where the transmitting ECU malfunction repeats the same frame all the time. The receiver of the information may use the counter parameter to detect this situation. The transmitting device will ...";
CM_ SG_ 2565895934 CRC "The CRC is defined as follows:
• Length: 8 bits
• Polynomial: x^8+x^5+x^3+x^2+x+1
• Initial Value: FFh
• Input Data Reflection: Not reflected
• Result Data Reflection: Not reflected
• XOR value: FFh
SAE makes no claim of the functional safety ...";
CM_ BO_ 2364569086 "Power Converter 1 Mode Feedback 1
The first mode feedback message from the Power Converter.";
CM_ SG_ 2364569086 HVILStatus "Reports the High Voltage Interlock Loop (HVIL) state.

00b = HVIL Closed
01b = HVIL Open
10b = Error
11b = Not Available";
CM_ SG_ 2364569086 CtrlSetpointMode "Reports the Power Converter mode (See SPN 20470 (Power Converter 1 Control Setpoint Mode Request) for requested mode).
Passive modes:
0 = Powered On - the Power Converter is commanded to be powered on and able to communicate, but the Power Stage ...";
CM_ SG_ 2364569086 CtrlLimitsOvrdMode "During normal operation this will have the same value as SPN 20467 (Power Converter 1 Control Limits Request Override Mode).
0 = Operating limits are not overridden.  If a limit was previously active, then it has reverted to its normal value as ...";
CM_ SG_ 2364569086 Counter "The message counter is used to detect situations where the transmitting ECU malfunction repeats the same frame all the time. The receiver of the information may use the counter parameter to detect this situation. The transmitting device will ...";
CM_ SG_ 2364569086 CRC "The CRC is defined as follows:
• Length: 8 bits
• Polynomial: x^8+x^5+x^3+x^2+x+1
• Initial Value: FFh
• Input Data Reflection: Not reflected
• Result Data Reflection: Not reflected
• XOR value: FFh
SAE makes no claim of the functional safety ...";
CM_ BO_ 2364568830 "Power Converter 1 Control 2
Secondary control message for this Power Converter Instance.   An example would be for use with an HVESS.";
CM_ SG_ 2364568830 PIDCtrlNormalizedPropGain "A PID controller can be parametrized by factors Kp, Ki and Kd. This parameter defines the normalized proportional gain (Kpn) for control applications in this inverter instance. The normalization converts absolute physical ranges into normalized ...";
CM_ SG_ 2364568830 PIDCtrlNormalizedIntegralGain "A PID controller can be parametrized by factors Kp, Ki and Kd. This parameter defines the normalized integral gain (Kin) for control applications in this inverter instance. The normalization converts absolute physical ranges into normalized values, ...";
CM_ SG_ 2364568830 PIDCtrlNormalizedDiffGain "A PID controller can be parametrized by factors Kp, Ki and Kd. This parameter defines the normalized differential gain (Kdn) for control applications in this inverter instance. The normalization converts absolute physical ranges into normalized ...";
CM_ SG_ 2364568830 PIDCtrlApplicableMode "Defines the Mode that the PID Gain parameters apply for this instance of the Power Converter.  See SPN 20546 (Power Converter 1 Control Setpoint Mode) for a definition of modes for control purposes.
Applicable modes:
0000b = Frequency Control Mode
 ...";
CM_ SG_ 2364568830 Counter "The message counter is used to detect situations where the transmitting ECU malfunction repeats the same frame all the time. The receiver of the information may use the counter parameter to detect this situation. The transmitting device will ...";
CM_ SG_ 2364568830 CRC "The CRC is defined as follows:
• Length: 8 bits
• Polynomial: x^8+x^5+x^3+x^2+x+1
• Initial Value: FFh
• Input Data Reflection: Not reflected
• Result Data Reflection: Not reflected
• XOR value: FFh
SAE makes no claim of the functional safety ...";
CM_ BO_ 2364568574 "Power Converter 2 Control 2
Secondary control message for this Power Converter Instance.   An example would be for use with an HVESS.";
CM_ SG_ 2364568574 PIDCtrlNormalizedPropGain "A PID controller can be parametrized by factors Kp, Ki and Kd. This parameter defines the normalized proportional gain (Kpn) for control applications in this inverter instance. The normalization converts absolute physical ranges into normalized ...";
CM_ SG_ 2364568574 PIDCtrlNormalizedIntegralGain "A PID controller can be parametrized by factors Kp, Ki and Kd. This parameter defines the normalized integral gain (Kin) for control applications in this inverter instance. The normalization converts absolute physical ranges into normalized values, ...";
CM_ SG_ 2364568574 PIDCtrlNormalizedDiffGain "A PID controller can be parametrized by factors Kp, Ki and Kd. This parameter defines the normalized differential gain (Kdn) for control applications in this inverter instance. The normalization converts absolute physical ranges into normalized ...";
CM_ SG_ 2364568574 PIDCtrlApplicableMode "Defines the Mode that the PID Gain parameters apply for this instance of the Power Converter.  See SPN 20571 (Power Converter 2 Control Setpoint Mode) for a definition of modes for control purposes.
Applicable modes:
0000b = Frequency Control Mode
 ...";
CM_ SG_ 2364568574 Counter "The message counter is used to detect situations where the transmitting ECU malfunction repeats the same frame all the time. The receiver of the information may use the counter parameter to detect this situation. The transmitting device will ...";
CM_ SG_ 2364568574 CRC "The CRC is defined as follows:
• Length: 8 bits
• Polynomial: x^8+x^5+x^3+x^2+x+1
• Initial Value: FFh
• Input Data Reflection: Not reflected
• Result Data Reflection: Not reflected
• XOR value: FFh
SAE makes no claim of the functional safety ...";
CM_ BO_ 2565894910 "Power Converter 2 Rate Limits Request 1
Requests the rate limits for this instance of inverter being controlled.  An example would be for use with an HVESS.";
CM_ SG_ 2565894910 AbsCurRateLmt "The maximum rate of change for the absolute system current (i.e. |d(current)|/dt) in all control modes.
Refer to SPN 20667 (Power Converter 2 Reference Current) to convert %/sec to A/sec.
Request a value of FBFh to instruct the Power Converter to ...";
CM_ SG_ 2565894910 AbsFreqRateLmt "The maximum rate of change for the absolute system frequency (i.e. |d(frequency)|/dt) in all control modes.
This limit shall solely lead to reducing the absolute current, not increasing it nor changing the current direction. Therefore, when limits ...";
CM_ SG_ 2565894910 Counter "The message counter is used to detect situations where the transmitting ECU malfunction repeats the same frame all the time. The receiver of the information may use the counter parameter to detect this situation. The transmitting device will ...";
CM_ SG_ 2565894910 CRC "The CRC is defined as follows:
• Length: 8 bits
• Polynomial: x^8+x^5+x^3+x^2+x+1
• Initial Value: FFh
• Input Data Reflection: Not reflected
• Result Data Reflection: Not reflected
• XOR value: FFh
SAE makes no claim of the functional safety ...";
CM_ BO_ 2565894654 "Power Converter 1 Rate Limits Request 1
Requests the rate limits for this instance of inverter being controlled.  An example would be for use with an HVESS.";
CM_ SG_ 2565894654 AbsCurRateLmt "The maximum rate of change for the absolute system current (i.e. |d(current)|/dt) in all control modes.
Refer to SPN 20690 (Power Converter 1 Reference Current) to convert %/sec to A/sec.
Request a value of FBFh to instruct the Power Converter to ...";
CM_ SG_ 2565894654 AbsFreqRateLmt "The maximum rate of change for the absolute system frequency  (i.e. |d(frequency)|/dt) in all control modes.
This limit shall solely lead to reducing the absolute current, not increasing it nor changing the current direction. Therefore, when limits ...";
CM_ SG_ 2565894654 Counter "The message counter is used to detect situations where the transmitting ECU malfunction repeats the same frame all the time. The receiver of the information may use the counter parameter to detect this situation. The transmitting device will ...";
CM_ SG_ 2565894654 CRC "The CRC is defined as follows:
• Length: 8 bits
• Polynomial: x^8+x^5+x^3+x^2+x+1
• Initial Value: FFh
• Input Data Reflection: Not reflected
• Result Data Reflection: Not reflected
• XOR value: FFh
SAE makes no claim of the functional safety ...";
CM_ BO_ 2364567806 "Power Converter 2 Control 1
Primary Control Message for this Power Converter Instance.   An example for use is a stationary or mobile inverter powered from an HVESS source.";
CM_ SG_ 2364567806 SetpointReq "Requests the set point for this inverter.  The type of set point requested by this parameter depends on the value of SPN 20477 (Power Converter 2 Control Setpoint Mode Request) as follows:
Passive Modes:
In any Passive Mode, a bit value of FBFFh ...";
CM_ SG_ 2364567806 SetpointModeReq "Requests the modes for this instance of the Power Converter.  See SPN 20571 (Power Converter 2 Control Setpoint Mode) for the feedback to this request.
Passive modes:  Modes where the Power Converter does not actively control the system current, ...";
CM_ SG_ 2364567806 LimitsReqOvrdMin "The Minimum limit requested by this parameter depends on the value of SPN 20474 (Power Converter 2 Control Limits Request Override Mode).
In normal operating conditions, the Power Converter operating limits are based on internal settings or Limits ...";
CM_ SG_ 2364567806 LimitsReqOvrdMax "The Maximum limit requested by this parameter depends on the value of SPN 20474 (Power Converter 2 Control Limits Request Override Mode).
In normal operating conditions, the Power Converter operating limits are based on internal settings or Limits ...";
CM_ SG_ 2364567806 LimitsReqOvrdMode "This parameter provides a way to temporarily override limits that are being received by the Power Converter in other messages.  It allows a specific type of limit to be transmitted at a high rate or at the same moment as the set point for ...";
CM_ SG_ 2364567806 Counter "The message counter is used to detect situations where the transmitting ECU malfunction repeats the same frame all the time. The receiver of the information may use the counter parameter to detect this situation. The transmitting device will ...";
CM_ SG_ 2364567806 CRC "The CRC is defined as follows:
• Length: 8 bits
• Polynomial: x^8+x^5+x^3+x^2+x+1
• Initial Value: FFh
• Input Data Reflection: Not reflected
• Result Data Reflection: Not reflected
• XOR value: FFh
SAE makes no claim of the functional safety ...";
CM_ BO_ 2364567550 "Power Converter 1 Control 1
Primary Control Message for this Power Converter Instance.   An example for use is a stationary or mobile inverter powered from an HVESS source.";
CM_ SG_ 2364567550 SetpointReq "Requests the set point for this inverter.  The type of set point requested by this parameter depends on the value of SPN 20470 (Power Converter 1 Control Setpoint Mode Request) as follows:
Passive Modes:
In any Passive Mode, a bit value of FBFFh ...";
CM_ SG_ 2364567550 SetpointModeReq "Requests the modes for this instance of the Power Converter.  See SPN 20546 (Power Converter 1 Control Setpoint Mode) for the feedback to this request.
Passive modes:  Modes where the Power Converter does not actively control the system current, ...";
CM_ SG_ 2364567550 LimitsReqOvrdMin "The Minimum limit requested by this parameter depends on the value of SPN 20467 (Power Converter 1 Control Limits Request Override Mode).
In normal operating conditions, the Power Converter operating limits are based on internal settings or Limits ...";
CM_ SG_ 2364567550 LimitsReqOvrdMax "The Maximum limit requested by this parameter depends on the value of SPN 20467 (Power Converter 1 Control Limits Request Override Mode).
In normal operating conditions, the Power Converter operating limits are based on internal settings or Limits ...";
CM_ SG_ 2364567550 LimitsReqOvrdMode "This parameter provides a way to temporarily override limits that are being received by the Power Converter in other messages.  It allows a specific type of limit to be transmitted at a high rate or at the same moment as the set point for ...";
CM_ SG_ 2364567550 Counter "The message counter is used to detect situations where the transmitting ECU malfunction repeats the same frame all the time. The receiver of the information may use the counter parameter to detect this situation. The transmitting device will ...";
CM_ SG_ 2364567550 CRC "The CRC is defined as follows:
• Length: 8 bits
• Polynomial: x^8+x^5+x^3+x^2+x+1
• Initial Value: FFh
• Input Data Reflection: Not reflected
• Result Data Reflection: Not reflected
• XOR value: FFh
SAE makes no claim of the functional safety ...";
CM_ BO_ 2555182846 "Electrified Accessory Engine Coolant Pump Command
The command message to the electrified accessory: Engine Coolant pump.

See PGN 64131 for the corresponding status message.";
CM_ SG_ 2555182846 ElectricPumpPercentSpd "Speed command to the Engine Electric Coolant Pump in percentage of maximum speed.
Note: Both Speed Command and Percent Speed Command cannot be used at the same time.  Always set the unused speed command to Not Available. If both commands are set to ...";
CM_ SG_ 2555182846 ElectricPumpSpdCmd "Speed command to the Engine Electric Coolant Pump.
Note:  Both Speed Command and Percent Speed Command cannot be used at the same time.  Always set the unused speed command to Not Available. If both commands are set to Not Available, a ...";
CM_ SG_ 2555182846 ElectricPumpDriveSource "Signal to the electric motor to indicate that the engine coolant pump is being powered by some other means, for example by a clutched belt from the engine.
00b = Pump driven from electric motor
01b = Pump driven from another source
10b = Error
 ...";
CM_ SG_ 2555182846 ElectricPumpPwrHold "Command to allow the Engine Electric Coolant Pump to remain alive independently of the electrical enable input to the Accessory Motor. For example, this could allow continued device operation after the keyswitch has turned off.
00b = Power Hold ...";
CM_ SG_ 2555182846 ElectricPumpEnableCmd "Enable and direction command to the Engine Electric Coolant Pump.

00b = Motor Off
01b = Motor On Normal/Default Direction
10b = Motor On Reverse Direction
11b = Don't Care/Take no action";
CM_ BO_ 2351103742 "High Voltage Energy Storage Pack 26 Control 1
Control commands to be sent to High Voltage Energy Storage Pack 26.";
CM_ SG_ 2351103742 Ctrl1CRC "The CRC is defined as follows:
• Length: 8 bits
• Polynomial: x^8+x^5+x^3+x^2+x+1
• Initial Value: FFh
• Input Data Reflection: Not reflected
• Result Data Reflection: Not reflected
• XOR value: FFh
SAE makes no claim of the functional safety ...";
CM_ SG_ 2351103742 Ctrl1Counter "The message counter is used to detect situations where the transmitting ECU malfunction repeats the same frame all the time. The receiver of the information may use the counter parameter to detect this situation. The transmitting device will ...";
CM_ SG_ 2351103742 ThermalMnmgtMaintenanceReq "Request to engage Thermal Management Maintenance Mode for this High Voltage Energy Storage System Pack instance.
00b = HVESS Thermal Management Maintenance Mode is not requested
01b = HVESS Thermal Management Maintenance Mode is requested
10b = ...";
CM_ SG_ 2351103742 HVBusLowSideResistorConnectReq "This parameter is used to request connection of this HVES instance High-Voltage bus low side resistor in order to perform an isolation test. See also SPN 17406 (HVESP26 High-Voltage Bus High Side Resistor Connect Request).
This parameter is for one ...";
CM_ SG_ 2351103742 HVBusHiSideResistorConnectReq "This parameter is used to request connection of this HVES instance High-Voltage bus high side resistor in order to perform an isolation test. See also SPN 17407 (HVESP26 High-Voltage Bus Low Side Resistor Connect Request).
This parameter is for one ...";
CM_ SG_ 2351103742 OpConsent "This parameter provides an indication to this High Voltage Energy Storage Pack instance that an external device is ready for this HVES instance to proceed with normal operation.  In applications which support this parameter, the HVES instance may ...";
CM_ SG_ 2351103742 EnableInternalChargerCmd "When the HVES has an internal charger this parameter will enable it.   External chargers may use the External Energy Source Connection Demand (SPN 7890) and related SPs.
This parameter is for one of multiple packs in an HVESS.  If there is only one ...";
CM_ SG_ 2351103742 CellBalancingCmd "Command for this High Voltage Energy Storage Pack instance to perform cell balancing.
This parameter is for one of multiple packs in an HVESS.  If there is only one pack in the system, the HVESS parameters should be used. If there are multiple ...";
CM_ SG_ 2351103742 HVBusPassiveIsolTestCmd "Command for this High Voltage Energy Storage Pack instance to perform a passive electrical isolation test on the high voltage bus.
A passive isolation test uses additional circuitry (e.g. a high impedance network) to monitor the delta between the ...";
CM_ SG_ 2351103742 HVBusActiveIsolTestCmd "Command for this High Voltage Energy Storage Pack instance to perform an active electrical isolation test on the high voltage bus.
An active isolation test might use a generated signal (e.g. an injected AC signal) and then monitor changes in the ...";
CM_ SG_ 2351103742 PwrDownCmd "Command to shut down this High Voltage Energy Storage Pack instance.  A normal power-down may involve steps that take some period of time (tests, writing of data, etc.).  However, an emergency power-down should shut down the storage system as ...";
CM_ SG_ 2351103742 HVBusConnectCmd "Command to connect this High Voltage Energy Storage Pack instance to the high-voltage bus.  The emergency contactor closure request may be used in situations where one or more faults in the hybrid powertrain prevent normal operation, but the vehicle ...";
CM_ BO_ 2351038206 "High Voltage Energy Storage Pack 25 Control 1
Control commands to be sent to High Voltage Energy Storage Pack 25.";
CM_ SG_ 2351038206 Ctrl1CRC "The CRC is defined as follows:
• Length: 8 bits
• Polynomial: x^8+x^5+x^3+x^2+x+1
• Initial Value: FFh
• Input Data Reflection: Not reflected
• Result Data Reflection: Not reflected
• XOR value: FFh
SAE makes no claim of the functional safety ...";
CM_ SG_ 2351038206 Ctrl1Counter "The message counter is used to detect situations where the transmitting ECU malfunction repeats the same frame all the time. The receiver of the information may use the counter parameter to detect this situation. The transmitting device will ...";
CM_ SG_ 2351038206 ThermalMnmgtMaintenanceReq "Request to engage Thermal Management Maintenance Mode for this High Voltage Energy Storage System Pack instance.
00b = HVESS Thermal Management Maintenance Mode is not requested
01b = HVESS Thermal Management Maintenance Mode is requested
10b = ...";
CM_ SG_ 2351038206 HVBusLowSideResistorConnectReq "This parameter is used to request connection of this HVES instance High-Voltage bus low side resistor in order to perform an isolation test. See also SPN 17264 (HVESP25 High-Voltage Bus High Side Resistor Connect Request).
This parameter is for one ...";
CM_ SG_ 2351038206 HVBusHiSideResistorConnectReq "This parameter is used to request connection of this HVES instance High-Voltage bus high side resistor in order to perform an isolation test. See also SPN 17265 (HVESP25 High-Voltage Bus Low Side Resistor Connect Request).
This parameter is for one ...";
CM_ SG_ 2351038206 OpConsent "This parameter provides an indication to this High Voltage Energy Storage Pack instance that an external device is ready for this HVES instance to proceed with normal operation.  In applications which support this parameter, the HVES instance may ...";
CM_ SG_ 2351038206 EnableInternalChargerCmd "When the HVES has an internal charger this parameter will enable it.   External chargers may use the External Energy Source Connection Demand (SPN 7890) and related SPs.
This parameter is for one of multiple packs in an HVESS.  If there is only one ...";
CM_ SG_ 2351038206 CellBalancingCmd "Command for this High Voltage Energy Storage Pack instance to perform cell balancing.
This parameter is for one of multiple packs in an HVESS.  If there is only one pack in the system, the HVESS parameters should be used. If there are multiple ...";
CM_ SG_ 2351038206 HVBusPassiveIsolTestCmd "Command for this High Voltage Energy Storage Pack instance to perform a passive electrical isolation test on the high voltage bus.
A passive isolation test uses additional circuitry (e.g. a high impedance network) to monitor the delta between the ...";
CM_ SG_ 2351038206 HVBusActiveIsolTestCmd "Command for this High Voltage Energy Storage Pack instance to perform an active electrical isolation test on the high voltage bus.
An active isolation test might use a generated signal (e.g. an injected AC signal) and then monitor changes in the ...";
CM_ SG_ 2351038206 PwrDownCmd "Command to shut down this High Voltage Energy Storage Pack instance.  A normal power-down may involve steps that take some period of time (tests, writing of data, etc.).  However, an emergency power-down should shut down the storage system as ...";
CM_ SG_ 2351038206 HVBusConnectCmd "Command to connect this High Voltage Energy Storage Pack instance to the high-voltage bus.  The emergency contactor closure request may be used in situations where one or more faults in the hybrid powertrain prevent normal operation, but the vehicle ...";
CM_ BO_ 2350972670 "High Voltage Energy Storage Pack 24 Control 1
Control commands to be sent to High Voltage Energy Storage Pack 24.";
CM_ SG_ 2350972670 Ctrl1CRC "The CRC is defined as follows:
• Length: 8 bits
• Polynomial: x^8+x^5+x^3+x^2+x+1
• Initial Value: FFh
• Input Data Reflection: Not reflected
• Result Data Reflection: Not reflected
• XOR value: FFh
SAE makes no claim of the functional safety ...";
CM_ SG_ 2350972670 Ctrl1Counter "The message counter is used to detect situations where the transmitting ECU malfunction repeats the same frame all the time. The receiver of the information may use the counter parameter to detect this situation. The transmitting device will ...";
CM_ SG_ 2350972670 ThermalMnmgtMaintenanceReq "Request to engage Thermal Management Maintenance Mode for this High Voltage Energy Storage System Pack instance.
00b = HVESS Thermal Management Maintenance Mode is not requested
01b = HVESS Thermal Management Maintenance Mode is requested
10b = ...";
CM_ SG_ 2350972670 HVBusLowSideResistorConnectReq "This parameter is used to request connection of this HVES instance High-Voltage bus low side resistor in order to perform an isolation test. See also SPN 17122 (HVESP24 High-Voltage Bus High Side Resistor Connect Request).
This parameter is for one ...";
CM_ SG_ 2350972670 HVBusHiSideResistorConnectReq "This parameter is used to request connection of this HVES instance High-Voltage bus high side resistor in order to perform an isolation test. See also SPN 17123 (HVESP24 High-Voltage Bus Low Side Resistor Connect Request).
This parameter is for one ...";
CM_ SG_ 2350972670 OpConsent "This parameter provides an indication to this High Voltage Energy Storage Pack instance that an external device is ready for this HVES instance to proceed with normal operation.  In applications which support this parameter, the HVES instance may ...";
CM_ SG_ 2350972670 EnableInternalChargerCmd "When the HVES has an internal charger this parameter will enable it.   External chargers may use the External Energy Source Connection Demand (SPN 7890) and related SPs.
This parameter is for one of multiple packs in an HVESS.  If there is only one ...";
CM_ SG_ 2350972670 CellBalancingCmd "Command for this High Voltage Energy Storage Pack instance to perform cell balancing.
This parameter is for one of multiple packs in an HVESS.  If there is only one pack in the system, the HVESS parameters should be used. If there are multiple ...";
CM_ SG_ 2350972670 HVBusPassiveIsolTestCmd "Command for this High Voltage Energy Storage Pack instance to perform a passive electrical isolation test on the high voltage bus.
A passive isolation test uses additional circuitry (e.g. a high impedance network) to monitor the delta between the ...";
CM_ SG_ 2350972670 HVBusActiveIsolTestCmd "Command for this High Voltage Energy Storage Pack instance to perform an active electrical isolation test on the high voltage bus.
An active isolation test might use a generated signal (e.g. an injected AC signal) and then monitor changes in the ...";
CM_ SG_ 2350972670 PwrDownCmd "Command to shut down this High Voltage Energy Storage Pack instance.  A normal power-down may involve steps that take some period of time (tests, writing of data, etc.).  However, an emergency power-down should shut down the storage system as ...";
CM_ SG_ 2350972670 HVBusConnectCmd "Command to connect this High Voltage Energy Storage Pack instance to the high-voltage bus.  The emergency contactor closure request may be used in situations where one or more faults in the hybrid powertrain prevent normal operation, but the vehicle ...";
CM_ BO_ 2350907134 "High Voltage Energy Storage Pack 23 Control 1
Control commands to be sent to High Voltage Energy Storage Pack 23.";
CM_ SG_ 2350907134 Ctrl1CRC "The CRC is defined as follows:
• Length: 8 bits
• Polynomial: x^8+x^5+x^3+x^2+x+1
• Initial Value: FFh
• Input Data Reflection: Not reflected
• Result Data Reflection: Not reflected
• XOR value: FFh
SAE makes no claim of the functional safety ...";
CM_ SG_ 2350907134 Ctrl1Counter "The message counter is used to detect situations where the transmitting ECU malfunction repeats the same frame all the time. The receiver of the information may use the counter parameter to detect this situation. The transmitting device will ...";
CM_ SG_ 2350907134 ThermalMnmgtMaintenanceReq "Request to engage Thermal Management Maintenance Mode for this High Voltage Energy Storage System Pack instance.
00b = HVESS Thermal Management Maintenance Mode is not requested
01b = HVESS Thermal Management Maintenance Mode is requested
10b = ...";
CM_ SG_ 2350907134 HVBusLowSideResistorConnectReq "This parameter is used to request connection of this HVES instance High-Voltage bus low side resistor in order to perform an isolation test. See also SPN 16980 (HVESP23 High-Voltage Bus High Side Resistor Connect Request).
This parameter is for one ...";
CM_ SG_ 2350907134 HVBusHiSideResistorConnectReq "This parameter is used to request connection of this HVES instance High-Voltage bus high side resistor in order to perform an isolation test. See also SPN 16981 (HVESP23 High-Voltage Bus Low Side Resistor Connect Request).
This parameter is for one ...";
CM_ SG_ 2350907134 OpConsent "This parameter provides an indication to this High Voltage Energy Storage Pack instance that an external device is ready for this HVES instance to proceed with normal operation.  In applications which support this parameter, the HVES instance may ...";
CM_ SG_ 2350907134 EnableInternalChargerCmd "When the HVES has an internal charger this parameter will enable it.   External chargers may use the External Energy Source Connection Demand (SPN 7890) and related SPs.
This parameter is for one of multiple packs in an HVESS.  If there is only one ...";
CM_ SG_ 2350907134 CellBalancingCmd "Command for this High Voltage Energy Storage Pack instance to perform cell balancing.
This parameter is for one of multiple packs in an HVESS.  If there is only one pack in the system, the HVESS parameters should be used. If there are multiple ...";
CM_ SG_ 2350907134 HVBusPassiveIsolTestCmd "Command for this High Voltage Energy Storage Pack instance to perform a passive electrical isolation test on the high voltage bus.
A passive isolation test uses additional circuitry (e.g. a high impedance network) to monitor the delta between the ...";
CM_ SG_ 2350907134 HVBusActiveIsolTestCmd "Command for this High Voltage Energy Storage Pack instance to perform an active electrical isolation test on the high voltage bus.
An active isolation test might use a generated signal (e.g. an injected AC signal) and then monitor changes in the ...";
CM_ SG_ 2350907134 PwrDownCmd "Command to shut down this High Voltage Energy Storage Pack instance.  A normal power-down may involve steps that take some period of time (tests, writing of data, etc.).  However, an emergency power-down should shut down the storage system as ...";
CM_ SG_ 2350907134 HVBusConnectCmd "Command to connect this High Voltage Energy Storage Pack instance to the high-voltage bus.  The emergency contactor closure request may be used in situations where one or more faults in the hybrid powertrain prevent normal operation, but the vehicle ...";
CM_ BO_ 2350579454 "High Voltage Energy Storage Pack 22 Control 1
Control commands to be sent to High Voltage Energy Storage Pack 22.";
CM_ SG_ 2350579454 Ctrl1CRC "The CRC is defined as follows:
• Length: 8 bits
• Polynomial: x^8+x^5+x^3+x^2+x+1
• Initial Value: FFh
• Input Data Reflection: Not reflected
• Result Data Reflection: Not reflected
• XOR value: FFh
SAE makes no claim of the functional safety ...";
CM_ SG_ 2350579454 Ctrl1Counter "The message counter is used to detect situations where the transmitting ECU malfunction repeats the same frame all the time. The receiver of the information may use the counter parameter to detect this situation. The transmitting device will ...";
CM_ SG_ 2350579454 ThermalMnmgtMaintenanceReq "Request to engage Thermal Management Maintenance Mode for this High Voltage Energy Storage System Pack instance.
00b = HVESS Thermal Management Maintenance Mode is not requested
01b = HVESS Thermal Management Maintenance Mode is requested
10b = ...";
CM_ SG_ 2350579454 HVBusLowSideResistorConnectReq "This parameter is used to request connection of this HVES instance High-Voltage bus low side resistor in order to perform an isolation test. See also SPN 16838 (HVESP22 High-Voltage Bus High Side Resistor Connect Request).
This parameter is for one ...";
CM_ SG_ 2350579454 HVBusHiSideResistorConnectReq "This parameter is used to request connection of this HVES instance High-Voltage bus high side resistor in order to perform an isolation test. See also SPN 16839 (HVESP22 High-Voltage Bus Low Side Resistor Connect Request).
This parameter is for one ...";
CM_ SG_ 2350579454 OpConsent "This parameter provides an indication to this High Voltage Energy Storage Pack instance that an external device is ready for this HVES instance to proceed with normal operation.  In applications which support this parameter, the HVES instance may ...";
CM_ SG_ 2350579454 EnableInternalChargerCmd "When the HVES has an internal charger this parameter will enable it.   External chargers may use the External Energy Source Connection Demand (SPN 7890) and related SPs.
This parameter is for one of multiple packs in an HVESS.  If there is only one ...";
CM_ SG_ 2350579454 CellBalancingCmd "Command for this High Voltage Energy Storage Pack instance to perform cell balancing.
This parameter is for one of multiple packs in an HVESS.  If there is only one pack in the system, the HVESS parameters should be used. If there are multiple ...";
CM_ SG_ 2350579454 HVBusPassiveIsolTestCmd "Command for this High Voltage Energy Storage Pack instance to perform a passive electrical isolation test on the high voltage bus.
A passive isolation test uses additional circuitry (e.g. a high impedance network) to monitor the delta between the ...";
CM_ SG_ 2350579454 HVBusActiveIsolTestCmd "Command for this High Voltage Energy Storage Pack instance to perform an active electrical isolation test on the high voltage bus.
An active isolation test might use a generated signal (e.g. an injected AC signal) and then monitor changes in the ...";
CM_ SG_ 2350579454 PwrDownCmd "Command to shut down this High Voltage Energy Storage Pack instance.  A normal power-down may involve steps that take some period of time (tests, writing of data, etc.).  However, an emergency power-down should shut down the storage system as ...";
CM_ SG_ 2350579454 HVBusConnectCmd "Command to connect this High Voltage Energy Storage Pack instance to the high-voltage bus.  The emergency contactor closure request may be used in situations where one or more faults in the hybrid powertrain prevent normal operation, but the vehicle ...";
CM_ BO_ 2350513918 "High Voltage Energy Storage Pack 21 Control 1
Control commands to be sent to High Voltage Energy Storage Pack 21.";
CM_ SG_ 2350513918 Ctrl1CRC "The CRC is defined as follows:
• Length: 8 bits
• Polynomial: x^8+x^5+x^3+x^2+x+1
• Initial Value: FFh
• Input Data Reflection: Not reflected
• Result Data Reflection: Not reflected
• XOR value: FFh
SAE makes no claim of the functional safety ...";
CM_ SG_ 2350513918 Ctrl1Counter "The message counter is used to detect situations where the transmitting ECU malfunction repeats the same frame all the time. The receiver of the information may use the counter parameter to detect this situation. The transmitting device will ...";
CM_ SG_ 2350513918 ThermalMnmgtMaintenanceReq "Request to engage Thermal Management Maintenance Mode for this High Voltage Energy Storage System Pack instance.
00b = HVESS Thermal Management Maintenance Mode is not requested
01b = HVESS Thermal Management Maintenance Mode is requested
10b = ...";
CM_ SG_ 2350513918 HVBusLowSideResistorConnectReq "This parameter is used to request connection of this HVES instance High-Voltage bus low side resistor in order to perform an isolation test. See also SPN 16696 (HVESP21 High-Voltage Bus High Side Resistor Connect Request).
This parameter is for one ...";
CM_ SG_ 2350513918 HVBusHiSideResistorConnectReq "This parameter is used to request connection of this HVES instance High-Voltage bus high side resistor in order to perform an isolation test. See also SPN 16697 (HVESP21 High-Voltage Bus Low Side Resistor Connect Request).
This parameter is for one ...";
CM_ SG_ 2350513918 OpConsent "This parameter provides an indication to this High Voltage Energy Storage Pack instance that an external device is ready for this HVES instance to proceed with normal operation.  In applications which support this parameter, the HVES instance may ...";
CM_ SG_ 2350513918 EnableInternalChargerCmd "When the HVES has an internal charger this parameter will enable it.   External chargers may use the External Energy Source Connection Demand (SPN 7890) and related SPs.
This parameter is for one of multiple packs in an HVESS.  If there is only one ...";
CM_ SG_ 2350513918 CellBalancingCmd "Command for this High Voltage Energy Storage Pack instance to perform cell balancing.
This parameter is for one of multiple packs in an HVESS.  If there is only one pack in the system, the HVESS parameters should be used. If there are multiple ...";
CM_ SG_ 2350513918 HVBusPassiveIsolTestCmd "Command for this High Voltage Energy Storage Pack instance to perform a passive electrical isolation test on the high voltage bus.
A passive isolation test uses additional circuitry (e.g. a high impedance network) to monitor the delta between the ...";
CM_ SG_ 2350513918 HVBusActiveIsolTestCmd "Command for this High Voltage Energy Storage Pack instance to perform an active electrical isolation test on the high voltage bus.
An active isolation test might use a generated signal (e.g. an injected AC signal) and then monitor changes in the ...";
CM_ SG_ 2350513918 PwrDownCmd "Command to shut down this High Voltage Energy Storage Pack instance.  A normal power-down may involve steps that take some period of time (tests, writing of data, etc.).  However, an emergency power-down should shut down the storage system as ...";
CM_ SG_ 2350513918 HVBusConnectCmd "Command to connect this High Voltage Energy Storage Pack instance to the high-voltage bus.  The emergency contactor closure request may be used in situations where one or more faults in the hybrid powertrain prevent normal operation, but the vehicle ...";
CM_ BO_ 2350448382 "High Voltage Energy Storage Pack 20 Control 1
Control commands to be sent to High Voltage Energy Storage Pack 20.";
CM_ SG_ 2350448382 Ctrl1CRC "The CRC is defined as follows:
• Length: 8 bits
• Polynomial: x^8+x^5+x^3+x^2+x+1
• Initial Value: FFh
• Input Data Reflection: Not reflected
• Result Data Reflection: Not reflected
• XOR value: FFh
SAE makes no claim of the functional safety ...";
CM_ SG_ 2350448382 Ctrl1Counter "The message counter is used to detect situations where the transmitting ECU malfunction repeats the same frame all the time. The receiver of the information may use the counter parameter to detect this situation. The transmitting device will ...";
CM_ SG_ 2350448382 ThermalMnmgtMaintenanceReq "Request to engage Thermal Management Maintenance Mode for this High Voltage Energy Storage System Pack instance.
00b = HVESS Thermal Management Maintenance Mode is not requested
01b = HVESS Thermal Management Maintenance Mode is requested
10b = ...";
CM_ SG_ 2350448382 HVBusLowSideResistorConnectReq "This parameter is used to request connection of this HVES instance High-Voltage bus low side resistor in order to perform an isolation test. See also SPN 16554 (HVESP20 High-Voltage Bus High Side Resistor Connect Request).
This parameter is for one ...";
CM_ SG_ 2350448382 HVBusHiSideResistorConnectReq "This parameter is used to request connection of this HVES instance High-Voltage bus high side resistor in order to perform an isolation test. See also SPN 16555 (HVESP20 High-Voltage Bus Low Side Resistor Connect Request).
This parameter is for one ...";
CM_ SG_ 2350448382 OpConsent "This parameter provides an indication to this High Voltage Energy Storage Pack instance that an external device is ready for this HVES instance to proceed with normal operation.  In applications which support this parameter, the HVES instance may ...";
CM_ SG_ 2350448382 EnableInternalChargerCmd "When the HVES has an internal charger this parameter will enable it.   External chargers may use the External Energy Source Connection Demand (SPN 7890) and related SPs.
This parameter is for one of multiple packs in an HVESS.  If there is only one ...";
CM_ SG_ 2350448382 CellBalancingCmd "Command for this High Voltage Energy Storage Pack instance to perform cell balancing.
This parameter is for one of multiple packs in an HVESS.  If there is only one pack in the system, the HVESS parameters should be used. If there are multiple ...";
CM_ SG_ 2350448382 HVBusPassiveIsolTestCmd "Command for this High Voltage Energy Storage Pack instance to perform a passive electrical isolation test on the high voltage bus.
A passive isolation test uses additional circuitry (e.g. a high impedance network) to monitor the delta between the ...";
CM_ SG_ 2350448382 HVBusActiveIsolTestCmd "Command for this High Voltage Energy Storage Pack instance to perform an active electrical isolation test on the high voltage bus.
An active isolation test might use a generated signal (e.g. an injected AC signal) and then monitor changes in the ...";
CM_ SG_ 2350448382 PwrDownCmd "Command to shut down this High Voltage Energy Storage Pack instance.  A normal power-down may involve steps that take some period of time (tests, writing of data, etc.).  However, an emergency power-down should shut down the storage system as ...";
CM_ SG_ 2350448382 HVBusConnectCmd "Command to connect this High Voltage Energy Storage Pack instance to the high-voltage bus.  The emergency contactor closure request may be used in situations where one or more faults in the hybrid powertrain prevent normal operation, but the vehicle ...";
CM_ BO_ 2350382846 "High Voltage Energy Storage Pack 19 Control 1
Control commands to be sent to High Voltage Energy Storage Pack 19.";
CM_ SG_ 2350382846 Ctrl1CRC "The CRC is defined as follows:
• Length: 8 bits
• Polynomial: x^8+x^5+x^3+x^2+x+1
• Initial Value: FFh
• Input Data Reflection: Not reflected
• Result Data Reflection: Not reflected
• XOR value: FFh
SAE makes no claim of the functional safety ...";
CM_ SG_ 2350382846 Ctrl1Counter "The message counter is used to detect situations where the transmitting ECU malfunction repeats the same frame all the time. The receiver of the information may use the counter parameter to detect this situation. The transmitting device will ...";
CM_ SG_ 2350382846 ThermalMnmgtMaintenanceReq "Request to engage Thermal Management Maintenance Mode for this High Voltage Energy Storage System Pack instance.
00b = HVESS Thermal Management Maintenance Mode is not requested
01b = HVESS Thermal Management Maintenance Mode is requested
10b = ...";
CM_ SG_ 2350382846 HVBusLowSideResistorConnectReq "This parameter is used to request connection of this HVES instance High-Voltage bus low side resistor in order to perform an isolation test. See also SPN 16412 (HVESP19 High-Voltage Bus High Side Resistor Connect Request).
This parameter is for one ...";
CM_ SG_ 2350382846 HVBusHiSideResistorConnectReq "This parameter is used to request connection of this HVES instance High-Voltage bus high side resistor in order to perform an isolation test. See also SPN 16413 (HVESP19 High-Voltage Bus Low Side Resistor Connect Request).
This parameter is for one ...";
CM_ SG_ 2350382846 OpConsent "This parameter provides an indication to this High Voltage Energy Storage Pack instance that an external device is ready for this HVES instance to proceed with normal operation.  In applications which support this parameter, the HVES instance may ...";
CM_ SG_ 2350382846 EnableInternalChargerCmd "When the HVES has an internal charger this parameter will enable it.   External chargers may use the External Energy Source Connection Demand (SPN 7890) and related SPs.
This parameter is for one of multiple packs in an HVESS.  If there is only one ...";
CM_ SG_ 2350382846 CellBalancingCmd "Command for this High Voltage Energy Storage Pack instance to perform cell balancing.
This parameter is for one of multiple packs in an HVESS.  If there is only one pack in the system, the HVESS parameters should be used. If there are multiple ...";
CM_ SG_ 2350382846 HVBusPassiveIsolTestCmd "Command for this High Voltage Energy Storage Pack instance to perform a passive electrical isolation test on the high voltage bus.
A passive isolation test uses additional circuitry (e.g. a high impedance network) to monitor the delta between the ...";
CM_ SG_ 2350382846 HVBusActiveIsolTestCmd "Command for this High Voltage Energy Storage Pack instance to perform an active electrical isolation test on the high voltage bus.
An active isolation test might use a generated signal (e.g. an injected AC signal) and then monitor changes in the ...";
CM_ SG_ 2350382846 PwrDownCmd "Command to shut down this High Voltage Energy Storage Pack instance.  A normal power-down may involve steps that take some period of time (tests, writing of data, etc.).  However, an emergency power-down should shut down the storage system as ...";
CM_ SG_ 2350382846 HVBusConnectCmd "Command to connect this High Voltage Energy Storage Pack instance to the high-voltage bus.  The emergency contactor closure request may be used in situations where one or more faults in the hybrid powertrain prevent normal operation, but the vehicle ...";
CM_ BO_ 2350317310 "High Voltage Energy Storage Pack 18 Control 1
Control commands to be sent to High Voltage Energy Storage Pack 18.";
CM_ SG_ 2350317310 Ctrl1CRC "The CRC is defined as follows:
• Length: 8 bits
• Polynomial: x^8+x^5+x^3+x^2+x+1
• Initial Value: FFh
• Input Data Reflection: Not reflected
• Result Data Reflection: Not reflected
• XOR value: FFh
SAE makes no claim of the functional safety ...";
CM_ SG_ 2350317310 Ctrl1Counter "The message counter is used to detect situations where the transmitting ECU malfunction repeats the same frame all the time. The receiver of the information may use the counter parameter to detect this situation. The transmitting device will ...";
CM_ SG_ 2350317310 ThermalMnmgtMaintenanceReq "Request to engage Thermal Management Maintenance Mode for this High Voltage Energy Storage System Pack instance.
00b = HVESS Thermal Management Maintenance Mode is not requested
01b = HVESS Thermal Management Maintenance Mode is requested
10b = ...";
CM_ SG_ 2350317310 HVBusLowSideResistorConnectReq "This parameter is used to request connection of this HVES instance High-Voltage bus low side resistor in order to perform an isolation test. See also SPN 16270 (HVESP18 High-Voltage Bus High Side Resistor Connect Request).
This parameter is for one ...";
CM_ SG_ 2350317310 HVBusHiSideResistorConnectReq "This parameter is used to request connection of this HVES instance High-Voltage bus high side resistor in order to perform an isolation test. See also SPN 16271 (HVESP18 High-Voltage Bus Low Side Resistor Connect Request).
This parameter is for one ...";
CM_ SG_ 2350317310 OpConsent "This parameter provides an indication to this High Voltage Energy Storage Pack instance that an external device is ready for this HVES instance to proceed with normal operation.  In applications which support this parameter, the HVES instance may ...";
CM_ SG_ 2350317310 EnableInternalChargerCmd "When the HVES has an internal charger this parameter will enable it.   External chargers may use the External Energy Source Connection Demand (SPN 7890) and related SPs.
This parameter is for one of multiple packs in an HVESS.  If there is only one ...";
CM_ SG_ 2350317310 CellBalancingCmd "Command for this High Voltage Energy Storage Pack instance to perform cell balancing.
This parameter is for one of multiple packs in an HVESS.  If there is only one pack in the system, the HVESS parameters should be used. If there are multiple ...";
CM_ SG_ 2350317310 HVBusPassiveIsolTestCmd "Command for this High Voltage Energy Storage Pack instance to perform a passive electrical isolation test on the high voltage bus.
A passive isolation test uses additional circuitry (e.g. a high impedance network) to monitor the delta between the ...";
CM_ SG_ 2350317310 HVBusActiveIsolTestCmd "Command for this High Voltage Energy Storage Pack instance to perform an active electrical isolation test on the high voltage bus.
An active isolation test might use a generated signal (e.g. an injected AC signal) and then monitor changes in the ...";
CM_ SG_ 2350317310 PwrDownCmd "Command to shut down this High Voltage Energy Storage Pack instance.  A normal power-down may involve steps that take some period of time (tests, writing of data, etc.).  However, an emergency power-down should shut down the storage system as ...";
CM_ SG_ 2350317310 HVBusConnectCmd "Command to connect this High Voltage Energy Storage Pack instance to the high-voltage bus.  The emergency contactor closure request may be used in situations where one or more faults in the hybrid powertrain prevent normal operation, but the vehicle ...";
CM_ BO_ 2350251774 "High Voltage Energy Storage Pack 17 Control 1
Control commands to be sent to High Voltage Energy Storage Pack 17.";
CM_ SG_ 2350251774 Ctrl1CRC "The CRC is defined as follows:
• Length: 8 bits
• Polynomial: x^8+x^5+x^3+x^2+x+1
• Initial Value: FFh
• Input Data Reflection: Not reflected
• Result Data Reflection: Not reflected
• XOR value: FFh
SAE makes no claim of the functional safety ...";
CM_ SG_ 2350251774 Ctrl1Counter "The message counter is used to detect situations where the transmitting ECU malfunction repeats the same frame all the time. The receiver of the information may use the counter parameter to detect this situation. The transmitting device will ...";
CM_ SG_ 2350251774 ThermalMnmgtMaintenanceReq "Request to engage Thermal Management Maintenance Mode for this High Voltage Energy Storage System Pack instance.
00b = HVESS Thermal Management Maintenance Mode is not requested
01b = HVESS Thermal Management Maintenance Mode is requested
10b = ...";
CM_ SG_ 2350251774 HVBusLowSideResistorConnectReq "This parameter is used to request connection of this HVES instance High-Voltage bus low side resistor in order to perform an isolation test. See also SPN 16128 (HVESP17 High-Voltage Bus High Side Resistor Connect Request).
This parameter is for one ...";
CM_ SG_ 2350251774 HVBusHiSideResistorConnectReq "This parameter is used to request connection of this HVES instance High-Voltage bus high side resistor in order to perform an isolation test. See also SPN 16129 (HVESP17 High-Voltage Bus Low Side Resistor Connect Request).
This parameter is for one ...";
CM_ SG_ 2350251774 OpConsent "This parameter provides an indication to this High Voltage Energy Storage Pack instance that an external device is ready for this HVES instance to proceed with normal operation.  In applications which support this parameter, the HVES instance may ...";
CM_ SG_ 2350251774 EnableInternalChargerCmd "When the HVES has an internal charger this parameter will enable it.   External chargers may use the External Energy Source Connection Demand (SPN 7890) and related SPs.
This parameter is for one of multiple packs in an HVESS.  If there is only one ...";
CM_ SG_ 2350251774 CellBalancingCmd "Command for this High Voltage Energy Storage Pack instance to perform cell balancing.
This parameter is for one of multiple packs in an HVESS.  If there is only one pack in the system, the HVESS parameters should be used. If there are multiple ...";
CM_ SG_ 2350251774 HVBusPassiveIsolTestCmd "Command for this High Voltage Energy Storage Pack instance to perform a passive electrical isolation test on the high voltage bus.
A passive isolation test uses additional circuitry (e.g. a high impedance network) to monitor the delta between the ...";
CM_ SG_ 2350251774 HVBusActiveIsolTestCmd "Command for this High Voltage Energy Storage Pack instance to perform an active electrical isolation test on the high voltage bus.
An active isolation test might use a generated signal (e.g. an injected AC signal) and then monitor changes in the ...";
CM_ SG_ 2350251774 PwrDownCmd "Command to shut down this High Voltage Energy Storage Pack instance.  A normal power-down may involve steps that take some period of time (tests, writing of data, etc.).  However, an emergency power-down should shut down the storage system as ...";
CM_ SG_ 2350251774 HVBusConnectCmd "Command to connect this High Voltage Energy Storage Pack instance to the high-voltage bus.  The emergency contactor closure request may be used in situations where one or more faults in the hybrid powertrain prevent normal operation, but the vehicle ...";
CM_ BO_ 2350186238 "High Voltage Energy Storage Pack 16 Control 1
Control commands to be sent to High Voltage Energy Storage Pack 16.";
CM_ SG_ 2350186238 Ctrl1CRC "The CRC is defined as follows:
• Length: 8 bits
• Polynomial: x^8+x^5+x^3+x^2+x+1
• Initial Value: FFh
• Input Data Reflection: Not reflected
• Result Data Reflection: Not reflected
• XOR value: FFh
SAE makes no claim of the functional safety ...";
CM_ SG_ 2350186238 Ctrl1Counter "The message counter is used to detect situations where the transmitting ECU malfunction repeats the same frame all the time. The receiver of the information may use the counter parameter to detect this situation. The transmitting device will ...";
CM_ SG_ 2350186238 ThermalMnmgtMaintenanceReq "Request to engage Thermal Management Maintenance Mode for this High Voltage Energy Storage System Pack instance.
00b = HVESS Thermal Management Maintenance Mode is not requested
01b = HVESS Thermal Management Maintenance Mode is requested
10b = ...";
CM_ SG_ 2350186238 HVBusLowSideResistorConnectReq "This parameter is used to request connection of this HVES instance High-Voltage bus low side resistor in order to perform an isolation test. See also SPN 15986 (HVESP16 High-Voltage Bus High Side Resistor Connect Request).
This parameter is for one ...";
CM_ SG_ 2350186238 HVBusHiSideResistorConnectReq "This parameter is used to request connection of this HVES instance High-Voltage bus high side resistor in order to perform an isolation test. See also SPN 15987 (HVESP16 High-Voltage Bus Low Side Resistor Connect Request).
This parameter is for one ...";
CM_ SG_ 2350186238 OpConsent "This parameter provides an indication to this High Voltage Energy Storage Pack instance that an external device is ready for this HVES instance to proceed with normal operation.  In applications which support this parameter, the HVES instance may ...";
CM_ SG_ 2350186238 EnableInternalChargerCmd "When the HVES has an internal charger this parameter will enable it.   External chargers may use the External Energy Source Connection Demand (SPN 7890) and related SPs.
This parameter is for one of multiple packs in an HVESS.  If there is only one ...";
CM_ SG_ 2350186238 CellBalancingCmd "Command for this High Voltage Energy Storage Pack instance to perform cell balancing.
This parameter is for one of multiple packs in an HVESS.  If there is only one pack in the system, the HVESS parameters should be used. If there are multiple ...";
CM_ SG_ 2350186238 HVBusPassiveIsolTestCmd "Command for this High Voltage Energy Storage Pack instance to perform a passive electrical isolation test on the high voltage bus.
A passive isolation test uses additional circuitry (e.g. a high impedance network) to monitor the delta between the ...";
CM_ SG_ 2350186238 HVBusActiveIsolTestCmd "Command for this High Voltage Energy Storage Pack instance to perform an active electrical isolation test on the high voltage bus.
An active isolation test might use a generated signal (e.g. an injected AC signal) and then monitor changes in the ...";
CM_ SG_ 2350186238 PwrDownCmd "Command to shut down this High Voltage Energy Storage Pack instance.  A normal power-down may involve steps that take some period of time (tests, writing of data, etc.).  However, an emergency power-down should shut down the storage system as ...";
CM_ SG_ 2350186238 HVBusConnectCmd "Command to connect this High Voltage Energy Storage Pack instance to the high-voltage bus.  The emergency contactor closure request may be used in situations where one or more faults in the hybrid powertrain prevent normal operation, but the vehicle ...";
CM_ BO_ 2350120702 "High Voltage Energy Storage Pack 15 Control 1
Control commands to be sent to High Voltage Energy Storage Pack 15.";
CM_ SG_ 2350120702 Ctrl1CRC "The CRC is defined as follows:
• Length: 8 bits
• Polynomial: x^8+x^5+x^3+x^2+x+1
• Initial Value: FFh
• Input Data Reflection: Not reflected
• Result Data Reflection: Not reflected
• XOR value: FFh
SAE makes no claim of the functional safety ...";
CM_ SG_ 2350120702 Ctrl1Counter "The message counter is used to detect situations where the transmitting ECU malfunction repeats the same frame all the time. The receiver of the information may use the counter parameter to detect this situation. The transmitting device will ...";
CM_ SG_ 2350120702 ThermalMnmgtMaintenanceReq "Request to engage Thermal Management Maintenance Mode for this High Voltage Energy Storage System Pack instance.
00b = HVESS Thermal Management Maintenance Mode is not requested
01b = HVESS Thermal Management Maintenance Mode is requested
10b = ...";
CM_ SG_ 2350120702 HVBusLowSideResistorConnectReq "This parameter is used to request connection of this HVES instance High-Voltage bus low side resistor in order to perform an isolation test. See also SPN 15844 (HVESP15 High-Voltage Bus High Side Resistor Connect Request).
This parameter is for one ...";
CM_ SG_ 2350120702 HVBusHiSideResistorConnectReq "This parameter is used to request connection of this HVES instance High-Voltage bus high side resistor in order to perform an isolation test. See also SPN 15845 (HVESP15 High-Voltage Bus Low Side Resistor Connect Request).
This parameter is for one ...";
CM_ SG_ 2350120702 OpConsent "This parameter provides an indication to this High Voltage Energy Storage Pack instance that an external device is ready for this HVES instance to proceed with normal operation.  In applications which support this parameter, the HVES instance may ...";
CM_ SG_ 2350120702 EnableInternalChargerCmd "When the HVES has an internal charger this parameter will enable it.   External chargers may use the External Energy Source Connection Demand (SPN 7890) and related SPs.
This parameter is for one of multiple packs in an HVESS.  If there is only one ...";
CM_ SG_ 2350120702 CellBalancingCmd "Command for this High Voltage Energy Storage Pack instance to perform cell balancing.
This parameter is for one of multiple packs in an HVESS.  If there is only one pack in the system, the HVESS parameters should be used. If there are multiple ...";
CM_ SG_ 2350120702 HVBusPassiveIsolTestCmd "Command for this High Voltage Energy Storage Pack instance to perform a passive electrical isolation test on the high voltage bus.
A passive isolation test uses additional circuitry (e.g. a high impedance network) to monitor the delta between the ...";
CM_ SG_ 2350120702 HVBusActiveIsolTestCmd "Command for this High Voltage Energy Storage Pack instance to perform an active electrical isolation test on the high voltage bus.
An active isolation test might use a generated signal (e.g. an injected AC signal) and then monitor changes in the ...";
CM_ SG_ 2350120702 PwrDownCmd "Command to shut down this High Voltage Energy Storage Pack instance.  A normal power-down may involve steps that take some period of time (tests, writing of data, etc.).  However, an emergency power-down should shut down the storage system as ...";
CM_ SG_ 2350120702 HVBusConnectCmd "Command to connect this High Voltage Energy Storage Pack instance to the high-voltage bus.  The emergency contactor closure request may be used in situations where one or more faults in the hybrid powertrain prevent normal operation, but the vehicle ...";
CM_ BO_ 2350055166 "High Voltage Energy Storage Pack 14 Control 1
Control commands to be sent to High Voltage Energy Storage Pack 14.";
CM_ SG_ 2350055166 Ctrl1CRC "The CRC is defined as follows:
• Length: 8 bits
• Polynomial: x^8+x^5+x^3+x^2+x+1
• Initial Value: FFh
• Input Data Reflection: Not reflected
• Result Data Reflection: Not reflected
• XOR value: FFh
SAE makes no claim of the functional safety ...";
CM_ SG_ 2350055166 Ctrl1Counter "The message counter is used to detect situations where the transmitting ECU malfunction repeats the same frame all the time. The receiver of the information may use the counter parameter to detect this situation. The transmitting device will ...";
CM_ SG_ 2350055166 ThermalMnmgtMaintenanceReq "Request to engage Thermal Management Maintenance Mode for this High Voltage Energy Storage System Pack instance.
00b = HVESS Thermal Management Maintenance Mode is not requested
01b = HVESS Thermal Management Maintenance Mode is requested
10b = ...";
CM_ SG_ 2350055166 HVBusLowSideResistorConnectReq "This parameter is used to request connection of this HVES instance High-Voltage bus low side resistor in order to perform an isolation test. See also SPN 15702 (HVESP14 High-Voltage Bus High Side Resistor Connect Request).
This parameter is for one ...";
CM_ SG_ 2350055166 HVBusHiSideResistorConnectReq "This parameter is used to request connection of this HVES instance High-Voltage bus high side resistor in order to perform an isolation test. See also SPN 15703 (HVESP14 High-Voltage Bus Low Side Resistor Connect Request).
This parameter is for one ...";
CM_ SG_ 2350055166 OpConsent "This parameter provides an indication to this High Voltage Energy Storage Pack instance that an external device is ready for this HVES instance to proceed with normal operation.  In applications which support this parameter, the HVES instance may ...";
CM_ SG_ 2350055166 EnableInternalChargerCmd "When the HVES has an internal charger this parameter will enable it.   External chargers may use the External Energy Source Connection Demand (SPN 7890) and related SPs.
This parameter is for one of multiple packs in an HVESS.  If there is only one ...";
CM_ SG_ 2350055166 CellBalancingCmd "Command for this High Voltage Energy Storage Pack instance to perform cell balancing.
This parameter is for one of multiple packs in an HVESS.  If there is only one pack in the system, the HVESS parameters should be used. If there are multiple ...";
CM_ SG_ 2350055166 HVBusPassiveIsolTestCmd "Command for this High Voltage Energy Storage Pack instance to perform a passive electrical isolation test on the high voltage bus.
A passive isolation test uses additional circuitry (e.g. a high impedance network) to monitor the delta between the ...";
CM_ SG_ 2350055166 HVBusActiveIsolTestCmd "Command for this High Voltage Energy Storage Pack instance to perform an active electrical isolation test on the high voltage bus.
An active isolation test might use a generated signal (e.g. an injected AC signal) and then monitor changes in the ...";
CM_ SG_ 2350055166 PwrDownCmd "Command to shut down this High Voltage Energy Storage Pack instance.  A normal power-down may involve steps that take some period of time (tests, writing of data, etc.).  However, an emergency power-down should shut down the storage system as ...";
CM_ SG_ 2350055166 HVBusConnectCmd "Command to connect this High Voltage Energy Storage Pack instance to the high-voltage bus.  The emergency contactor closure request may be used in situations where one or more faults in the hybrid powertrain prevent normal operation, but the vehicle ...";
CM_ BO_ 2349989630 "High Voltage Energy Storage Pack 13 Control 1
Control commands to be sent to High Voltage Energy Storage Pack 13.";
CM_ SG_ 2349989630 Ctrl1CRC "The CRC is defined as follows:
• Length: 8 bits
• Polynomial: x^8+x^5+x^3+x^2+x+1
• Initial Value: FFh
• Input Data Reflection: Not reflected
• Result Data Reflection: Not reflected
• XOR value: FFh
SAE makes no claim of the functional safety ...";
CM_ SG_ 2349989630 Ctrl1Counter "The message counter is used to detect situations where the transmitting ECU malfunction repeats the same frame all the time. The receiver of the information may use the counter parameter to detect this situation. The transmitting device will ...";
CM_ SG_ 2349989630 ThermalMnmgtMaintenanceReq "Request to engage Thermal Management Maintenance Mode for this High Voltage Energy Storage System Pack instance.
00b = HVESS Thermal Management Maintenance Mode is not requested
01b = HVESS Thermal Management Maintenance Mode is requested
10b = ...";
CM_ SG_ 2349989630 HVBusLowSideResistorConnectReq "This parameter is used to request connection of this HVES instance High-Voltage bus low side resistor in order to perform an isolation test. See also SPN 15560 (HVESP13 High-Voltage Bus High Side Resistor Connect Request).
This parameter is for one ...";
CM_ SG_ 2349989630 HVBusHiSideResistorConnectReq "This parameter is used to request connection of this HVES instance High-Voltage bus high side resistor in order to perform an isolation test. See also SPN 15561 (HVESP13 High-Voltage Bus Low Side Resistor Connect Request).
This parameter is for one ...";
CM_ SG_ 2349989630 OpConsent "This parameter provides an indication to this High Voltage Energy Storage Pack instance that an external device is ready for this HVES instance to proceed with normal operation.  In applications which support this parameter, the HVES instance may ...";
CM_ SG_ 2349989630 EnableInternalChargerCmd "When the HVES has an internal charger this parameter will enable it.   External chargers may use the External Energy Source Connection Demand (SPN 7890) and related SPs.
This parameter is for one of multiple packs in an HVESS.  If there is only one ...";
CM_ SG_ 2349989630 CellBalancingCmd "Command for this High Voltage Energy Storage Pack instance to perform cell balancing.
This parameter is for one of multiple packs in an HVESS.  If there is only one pack in the system, the HVESS parameters should be used. If there are multiple ...";
CM_ SG_ 2349989630 HVBusPassiveIsolTestCmd "Command for this High Voltage Energy Storage Pack instance to perform a passive electrical isolation test on the high voltage bus.
A passive isolation test uses additional circuitry (e.g. a high impedance network) to monitor the delta between the ...";
CM_ SG_ 2349989630 HVBusActiveIsolTestCmd "Command for this High Voltage Energy Storage Pack instance to perform an active electrical isolation test on the high voltage bus.
An active isolation test might use a generated signal (e.g. an injected AC signal) and then monitor changes in the ...";
CM_ SG_ 2349989630 PwrDownCmd "Command to shut down this High Voltage Energy Storage Pack instance.  A normal power-down may involve steps that take some period of time (tests, writing of data, etc.).  However, an emergency power-down should shut down the storage system as ...";
CM_ SG_ 2349989630 HVBusConnectCmd "Command to connect this High Voltage Energy Storage Pack instance to the high-voltage bus.  The emergency contactor closure request may be used in situations where one or more faults in the hybrid powertrain prevent normal operation, but the vehicle ...";
CM_ BO_ 2349924094 "High Voltage Energy Storage Pack 12 Control 1
Control commands to be sent to High Voltage Energy Storage Pack 12.";
CM_ SG_ 2349924094 Ctrl1CRC "The CRC is defined as follows:
• Length: 8 bits
• Polynomial: x^8+x^5+x^3+x^2+x+1
• Initial Value: FFh
• Input Data Reflection: Not reflected
• Result Data Reflection: Not reflected
• XOR value: FFh
SAE makes no claim of the functional safety ...";
CM_ SG_ 2349924094 Ctrl1Counter "The message counter is used to detect situations where the transmitting ECU malfunction repeats the same frame all the time. The receiver of the information may use the counter parameter to detect this situation. The transmitting device will ...";
CM_ SG_ 2349924094 ThermalMnmgtMaintenanceReq "Request to engage Thermal Management Maintenance Mode for this High Voltage Energy Storage System Pack instance.
00b = HVESS Thermal Management Maintenance Mode is not requested
01b = HVESS Thermal Management Maintenance Mode is requested
10b = ...";
CM_ SG_ 2349924094 HVBusLowSideResistorConnectReq "This parameter is used to request connection of this HVES instance High-Voltage bus low side resistor in order to perform an isolation test. See also SPN 15418 (HVESP12 High-Voltage Bus High Side Resistor Connect Request).
This parameter is for one ...";
CM_ SG_ 2349924094 HVBusHiSideResistorConnectReq "This parameter is used to request connection of this HVES instance High-Voltage bus high side resistor in order to perform an isolation test. See also SPN 15419 (HVESP12 High-Voltage Bus Low Side Resistor Connect Request).
This parameter is for one ...";
CM_ SG_ 2349924094 OpConsent "This parameter provides an indication to this High Voltage Energy Storage Pack instance that an external device is ready for this HVES instance to proceed with normal operation.  In applications which support this parameter, the HVES instance may ...";
CM_ SG_ 2349924094 EnableInternalChargerCmd "When the HVES has an internal charger this parameter will enable it.   External chargers may use the External Energy Source Connection Demand (SPN 7890) and related SPs.
This parameter is for one of multiple packs in an HVESS.  If there is only one ...";
CM_ SG_ 2349924094 CellBalancingCmd "Command for this High Voltage Energy Storage Pack instance to perform cell balancing.
This parameter is for one of multiple packs in an HVESS.  If there is only one pack in the system, the HVESS parameters should be used. If there are multiple ...";
CM_ SG_ 2349924094 HVBusPassiveIsolTestCmd "Command for this High Voltage Energy Storage Pack instance to perform a passive electrical isolation test on the high voltage bus.
A passive isolation test uses additional circuitry (e.g. a high impedance network) to monitor the delta between the ...";
CM_ SG_ 2349924094 HVBusActiveIsolTestCmd "Command for this High Voltage Energy Storage Pack instance to perform an active electrical isolation test on the high voltage bus.
An active isolation test might use a generated signal (e.g. an injected AC signal) and then monitor changes in the ...";
CM_ SG_ 2349924094 PwrDownCmd "Command to shut down this High Voltage Energy Storage Pack instance.  A normal power-down may involve steps that take some period of time (tests, writing of data, etc.).  However, an emergency power-down should shut down the storage system as ...";
CM_ SG_ 2349924094 HVBusConnectCmd "Command to connect this High Voltage Energy Storage Pack instance to the high-voltage bus.  The emergency contactor closure request may be used in situations where one or more faults in the hybrid powertrain prevent normal operation, but the vehicle ...";
BA_DEF_ SG_  "GenSigInactiveValue" INT 0 0;
BA_DEF_ SG_  "SigType" ENUM  "Default","Range","RangeSigned","ASCII","Discrete","Control","ReferencePGN","DTC","StringDelimiter","StringLength","StringLengthControl","MessageCounter","MessageChecksum";
BA_DEF_ SG_  "GenSigStartValue" INT 0 2147483647;
BA_DEF_ SG_  "GenSigSendType" ENUM  "Cyclic","OnWrite","OnWriteWithRepetition","OnChange","OnChangeWithRepetition","IfActive","IfActiveWithRepetition","NoSigSendType";
BA_DEF_ SG_  "GenSigILSupport" ENUM  "No","Yes";
BA_DEF_ SG_  "SPN" INT 0 524287;
BA_DEF_ BO_  "J1939CPgSendTimeout" INT -1 3600000;
BA_DEF_ BO_  "J1939CPgTOS" INT 0 7;
BA_DEF_ BO_  "J1939PgAppearanceOnBus" ENUM  "Default","CAN_Extended","CANFD_Extended";
BA_DEF_ BO_  "FsJ1939UseCrcAndCounter" STRING ;
BA_DEF_ BO_  "TpJ1939VarDlc" ENUM  "No","Yes";
BA_DEF_ BO_  "GenMsgNrOfRepetition" INT 0 1000000;
BA_DEF_ BO_  "GenMsgCycleTimeFast" INT 0 3600000;
BA_DEF_ BO_  "GenMsgFastOnStart" INT 0 100000;
BA_DEF_ BO_  "GenMsgStartDelayTime" INT 0 100000;
BA_DEF_ BO_  "GenMsgILSupport" ENUM  "No","Yes";
BA_DEF_ BO_  "GenMsgDelayTime" INT 0 1000;
BA_DEF_ BO_  "GenMsgRequestable" INT 0 1;
BA_DEF_ BO_  "GenMsgSendType" ENUM  "cyclic","NotUsed","NotUsed","NotUsed","NotUsed","NotUsed","NotUsed","IfActive","noMsgSendType";
BA_DEF_ BO_  "VFrameFormat" ENUM  "StandardCAN","ExtendedCAN","reserved","J1939PG","reserved","reserved","reserved","reserved","reserved","reserved","reserved","reserved","reserved","reserved","StandardCAN_FD","ExtendedCAN_FD";
BA_DEF_ BO_  "SingleFrame" INT 0 1;
BA_DEF_ BO_  "GenMsgCycleTime" INT 0 3600000;
BA_DEF_ SG_  "SystemSignalLongSymbol" STRING ;
BA_DEF_DEF_  "GenSigInactiveValue" 0;
BA_DEF_DEF_  "SigType" "Default";
BA_DEF_DEF_  "GenSigStartValue" 0;
BA_DEF_DEF_  "GenSigSendType" "NoSigSendType";
BA_DEF_DEF_  "GenSigILSupport" "Yes";
BA_DEF_DEF_  "SPN" 0;
BA_DEF_DEF_  "J1939CPgSendTimeout" -1;
BA_DEF_DEF_  "J1939CPgTOS" 2;
BA_DEF_DEF_  "J1939PgAppearanceOnBus" "Default";
BA_DEF_DEF_  "FsJ1939UseCrcAndCounter" "";
BA_DEF_DEF_  "TpJ1939VarDlc" "No";
BA_DEF_DEF_  "GenMsgNrOfRepetition" 0;
BA_DEF_DEF_  "GenMsgCycleTimeFast" 0;
BA_DEF_DEF_  "GenMsgFastOnStart" 0;
BA_DEF_DEF_  "GenMsgStartDelayTime" 0;
BA_DEF_DEF_  "GenMsgILSupport" "Yes";
BA_DEF_DEF_  "GenMsgDelayTime" 0;
BA_DEF_DEF_  "GenMsgRequestable" 1;
BA_DEF_DEF_  "GenMsgSendType" "noMsgSendType";
BA_DEF_DEF_  "VFrameFormat" "J1939PG";
BA_DEF_DEF_  "SingleFrame" 1;
BA_DEF_DEF_  "GenMsgCycleTime" 0;
BA_DEF_DEF_  "SystemSignalLongSymbol" "";
BA_ "GenMsgSendType" BO_ 2364691710 0;
BA_ "GenMsgCycleTime" BO_ 2364691710 20;
BA_ "GenMsgSendType" BO_ 2364691454 0;
BA_ "GenMsgCycleTime" BO_ 2364691454 20;
BA_ "GenMsgSendType" BO_ 2364691198 0;
BA_ "GenMsgCycleTime" BO_ 2364691198 20;
BA_ "GenMsgSendType" BO_ 2364690942 0;
BA_ "GenMsgCycleTime" BO_ 2364690942 100;
BA_ "GenMsgSendType" BO_ 2364690686 0;
BA_ "GenMsgCycleTime" BO_ 2364690686 10;
BA_ "FsJ1939UseCrcAndCounter" BO_ 2364573438 "Bc";
BA_ "GenMsgSendType" BO_ 2364573438 0;
BA_ "GenMsgCycleTime" BO_ 2364573438 10;
BA_ "FsJ1939UseCrcAndCounter" BO_ 2364573182 "Bc";
BA_ "GenMsgSendType" BO_ 2364573182 0;
BA_ "GenMsgCycleTime" BO_ 2364573182 10;
BA_ "FsJ1939UseCrcAndCounter" BO_ 2565899518 "Bc";
BA_ "GenMsgSendType" BO_ 2565899518 0;
BA_ "GenMsgCycleTime" BO_ 2565899518 250;
BA_ "FsJ1939UseCrcAndCounter" BO_ 2565899262 "Bc";
BA_ "GenMsgSendType" BO_ 2565899262 0;
BA_ "GenMsgCycleTime" BO_ 2565899262 250;
BA_ "FsJ1939UseCrcAndCounter" BO_ 2565899006 "Bc";
BA_ "GenMsgSendType" BO_ 2565899006 0;
BA_ "GenMsgCycleTime" BO_ 2565899006 100;
BA_ "FsJ1939UseCrcAndCounter" BO_ 2565898750 "Bc";
BA_ "GenMsgSendType" BO_ 2565898750 0;
BA_ "GenMsgCycleTime" BO_ 2565898750 100;
BA_ "FsJ1939UseCrcAndCounter" BO_ 2565898494 "Bc";
BA_ "GenMsgSendType" BO_ 2565898494 0;
BA_ "GenMsgCycleTime" BO_ 2565898494 100;
BA_ "FsJ1939UseCrcAndCounter" BO_ 2565898238 "Bc";
BA_ "GenMsgSendType" BO_ 2565898238 0;
BA_ "GenMsgCycleTime" BO_ 2565898238 100;
BA_ "GenMsgSendType" BO_ 2565897982 0;
BA_ "GenMsgCycleTime" BO_ 2565897982 100;
BA_ "FsJ1939UseCrcAndCounter" BO_ 2565897726 "Bc";
BA_ "GenMsgSendType" BO_ 2565897726 0;
BA_ "GenMsgCycleTime" BO_ 2565897726 100;
BA_ "FsJ1939UseCrcAndCounter" BO_ 2565897470 "Bc";
BA_ "GenMsgSendType" BO_ 2565897470 0;
BA_ "GenMsgCycleTime" BO_ 2565897470 100;
BA_ "FsJ1939UseCrcAndCounter" BO_ 2565897214 "Bc";
BA_ "GenMsgSendType" BO_ 2565897214 0;
BA_ "GenMsgCycleTime" BO_ 2565897214 100;
BA_ "FsJ1939UseCrcAndCounter" BO_ 2364570366 "Bc";
BA_ "GenMsgSendType" BO_ 2364570366 0;
BA_ "GenMsgCycleTime" BO_ 2364570366 100;
BA_ "GenMsgSendType" BO_ 2565896702 0;
BA_ "GenMsgCycleTime" BO_ 2565896702 100;
BA_ "FsJ1939UseCrcAndCounter" BO_ 2565896446 "Bc";
BA_ "GenMsgSendType" BO_ 2565896446 0;
BA_ "GenMsgCycleTime" BO_ 2565896446 100;
BA_ "FsJ1939UseCrcAndCounter" BO_ 2565896190 "Bc";
BA_ "GenMsgSendType" BO_ 2565896190 0;
BA_ "GenMsgCycleTime" BO_ 2565896190 100;
BA_ "FsJ1939UseCrcAndCounter" BO_ 2565895934 "Bc";
BA_ "GenMsgSendType" BO_ 2565895934 0;
BA_ "GenMsgCycleTime" BO_ 2565895934 100;
BA_ "FsJ1939UseCrcAndCounter" BO_ 2364569086 "Bc";
BA_ "GenMsgSendType" BO_ 2364569086 0;
BA_ "GenMsgCycleTime" BO_ 2364569086 100;
BA_ "FsJ1939UseCrcAndCounter" BO_ 2364568830 "Bc";
BA_ "GenMsgSendType" BO_ 2364568830 0;
BA_ "GenMsgCycleTime" BO_ 2364568830 100;
BA_ "FsJ1939UseCrcAndCounter" BO_ 2364568574 "Bc";
BA_ "GenMsgSendType" BO_ 2364568574 0;
BA_ "GenMsgCycleTime" BO_ 2364568574 100;
BA_ "FsJ1939UseCrcAndCounter" BO_ 2565894910 "Bc";
BA_ "GenMsgSendType" BO_ 2565894910 0;
BA_ "GenMsgCycleTime" BO_ 2565894910 100;
BA_ "FsJ1939UseCrcAndCounter" BO_ 2565894654 "Bc";
BA_ "GenMsgSendType" BO_ 2565894654 0;
BA_ "GenMsgCycleTime" BO_ 2565894654 100;
BA_ "FsJ1939UseCrcAndCounter" BO_ 2364567806 "Bc";
BA_ "GenMsgSendType" BO_ 2364567806 0;
BA_ "GenMsgCycleTime" BO_ 2364567806 10;
BA_ "FsJ1939UseCrcAndCounter" BO_ 2364567550 "Bc";
BA_ "GenMsgSendType" BO_ 2364567550 0;
BA_ "GenMsgCycleTime" BO_ 2364567550 10;
BA_ "GenMsgSendType" BO_ 2555182846 0;
BA_ "GenMsgCycleTime" BO_ 2555182846 1000;
BA_ "FsJ1939UseCrcAndCounter" BO_ 2351103742 "Aa";
BA_ "GenMsgSendType" BO_ 2351103742 0;
BA_ "GenMsgCycleTime" BO_ 2351103742 20;
BA_ "FsJ1939UseCrcAndCounter" BO_ 2351038206 "Aa";
BA_ "GenMsgSendType" BO_ 2351038206 0;
BA_ "GenMsgCycleTime" BO_ 2351038206 20;
BA_ "FsJ1939UseCrcAndCounter" BO_ 2350972670 "Aa";
BA_ "GenMsgSendType" BO_ 2350972670 0;
BA_ "GenMsgCycleTime" BO_ 2350972670 20;
BA_ "FsJ1939UseCrcAndCounter" BO_ 2350907134 "Aa";
BA_ "GenMsgSendType" BO_ 2350907134 0;
BA_ "GenMsgCycleTime" BO_ 2350907134 20;
BA_ "FsJ1939UseCrcAndCounter" BO_ 2350579454 "Aa";
BA_ "GenMsgSendType" BO_ 2350579454 0;
BA_ "GenMsgCycleTime" BO_ 2350579454 20;
BA_ "FsJ1939UseCrcAndCounter" BO_ 2350513918 "Aa";
BA_ "GenMsgSendType" BO_ 2350513918 0;
BA_ "GenMsgCycleTime" BO_ 2350513918 20;
BA_ "FsJ1939UseCrcAndCounter" BO_ 2350448382 "Aa";
BA_ "GenMsgSendType" BO_ 2350448382 0;
BA_ "GenMsgCycleTime" BO_ 2350448382 20;
BA_ "FsJ1939UseCrcAndCounter" BO_ 2350382846 "Aa";
BA_ "GenMsgSendType" BO_ 2350382846 0;
BA_ "GenMsgCycleTime" BO_ 2350382846 20;
BA_ "FsJ1939UseCrcAndCounter" BO_ 2350317310 "Aa";
BA_ "GenMsgSendType" BO_ 2350317310 0;
BA_ "GenMsgCycleTime" BO_ 2350317310 20;
BA_ "FsJ1939UseCrcAndCounter" BO_ 2350251774 "Aa";
BA_ "GenMsgSendType" BO_ 2350251774 0;
BA_ "GenMsgCycleTime" BO_ 2350251774 20;
BA_ "FsJ1939UseCrcAndCounter" BO_ 2350186238 "Aa";
BA_ "GenMsgSendType" BO_ 2350186238 0;
BA_ "GenMsgCycleTime" BO_ 2350186238 20;
BA_ "FsJ1939UseCrcAndCounter" BO_ 2350120702 "Aa";
BA_ "GenMsgSendType" BO_ 2350120702 0;
BA_ "GenMsgCycleTime" BO_ 2350120702 20;
BA_ "FsJ1939UseCrcAndCounter" BO_ 2350055166 "Aa";
BA_ "GenMsgSendType" BO_ 2350055166 0;
BA_ "GenMsgCycleTime" BO_ 2350055166 20;
BA_ "FsJ1939UseCrcAndCounter" BO_ 2349989630 "Aa";
BA_ "GenMsgSendType" BO_ 2349989630 0;
BA_ "GenMsgCycleTime" BO_ 2349989630 20;
BA_ "FsJ1939UseCrcAndCounter" BO_ 2349924094 "Aa";
BA_ "GenMsgSendType" BO_ 2349924094 0;
BA_ "GenMsgCycleTime" BO_ 2349924094 20;
BA_ "SigType" SG_ 2364691710 CellTempDiffStatus 4;
BA_ "SPN" SG_ 2364691710 CellTempDiffStatus 15303;
BA_ "SigType" SG_ 2364691710 AvgCellTemp 1;
BA_ "SPN" SG_ 2364691710 AvgCellTemp 15302;
BA_ "SigType" SG_ 2364691710 LowestCellTemp 1;
BA_ "SPN" SG_ 2364691710 LowestCellTemp 15301;
BA_ "SigType" SG_ 2364691710 HighestCellTemp 1;
BA_ "SPN" SG_ 2364691710 HighestCellTemp 15300;
BA_ "SPN" SG_ 2364691454 CellVDiffStatus 15299;
BA_ "SigType" SG_ 2364691454 LowestCellV 1;
BA_ "SPN" SG_ 2364691454 LowestCellV 15298;
BA_ "SigType" SG_ 2364691454 HighestCellV 1;
BA_ "SPN" SG_ 2364691454 HighestCellV 15297;
BA_ "SigType" SG_ 2364691454 FastUpdateStOfCharge 1;
BA_ "SPN" SG_ 2364691454 FastUpdateStOfCharge 15296;
BA_ "SigType" SG_ 2364691198 Cur 1;
BA_ "SPN" SG_ 2364691198 Cur 15295;
BA_ "SigType" SG_ 2364691198 Lvl 1;
BA_ "SPN" SG_ 2364691198 Lvl 15294;
BA_ "SigType" SG_ 2364691198 AvailableChargePwr 1;
BA_ "SPN" SG_ 2364691198 AvailableChargePwr 15293;
BA_ "SigType" SG_ 2364691198 AvailableDisPwr 1;
BA_ "SPN" SG_ 2364691198 AvailableDisPwr 15292;
BA_ "SigType" SG_ 2364690942 ChargePLDueToAnUndefinedCause 4;
BA_ "SPN" SG_ 2364690942 ChargePLDueToAnUndefinedCause 15291;
BA_ "SigType" SG_ 2364690942 ChargePLDueToBatCur 4;
BA_ "SPN" SG_ 2364690942 ChargePLDueToBatCur 15290;
BA_ "SigType" SG_ 2364690942 ChargePLDueToBatOrCellV 4;
BA_ "SPN" SG_ 2364690942 ChargePLDueToBatOrCellV 15289;
BA_ "SigType" SG_ 2364690942 ChargePLDueToBatDiagCondition 4;
BA_ "SPN" SG_ 2364690942 ChargePLDueToBatDiagCondition 15288;
BA_ "SigType" SG_ 2364690942 ChargePLDueToBatTemp 4;
BA_ "SPN" SG_ 2364690942 ChargePLDueToBatTemp 15287;
BA_ "SigType" SG_ 2364690942 ChargePLDueToStOfCharge 4;
BA_ "SPN" SG_ 2364690942 ChargePLDueToStOfCharge 15286;
BA_ "SigType" SG_ 2364690942 DisPLDueToAnUndefinedCause 4;
BA_ "SPN" SG_ 2364690942 DisPLDueToAnUndefinedCause 15285;
BA_ "SigType" SG_ 2364690942 DisPLDueToBatCur 4;
BA_ "SPN" SG_ 2364690942 DisPLDueToBatCur 15284;
BA_ "SigType" SG_ 2364690942 DisPLDueToBatOrCellV 4;
BA_ "SPN" SG_ 2364690942 DisPLDueToBatOrCellV 15283;
BA_ "SigType" SG_ 2364690942 DisPLDueToBatDiagCondition 4;
BA_ "SPN" SG_ 2364690942 DisPLDueToBatDiagCondition 15282;
BA_ "SigType" SG_ 2364690942 DisPLDueToBatTemp 4;
BA_ "SPN" SG_ 2364690942 DisPLDueToBatTemp 15281;
BA_ "SigType" SG_ 2364690942 DisPLDueToStOfCharge 4;
BA_ "SPN" SG_ 2364690942 DisPLDueToStOfCharge 15280;
BA_ "SigType" SG_ 2364690686 OutSpd 1;
BA_ "SPN" SG_ 2364690686 OutSpd 15204;
BA_ "SPN" SG_ 2364573438 DCES1V 20697;
BA_ "SPN" SG_ 2364573438 DCES1Cur 20696;
BA_ "SigType" SG_ 2364573438 Freq 1;
BA_ "SPN" SG_ 2364573438 Freq 20695;
BA_ "SPN" SG_ 2364573438 Cur 20694;
BA_ "SigType" SG_ 2364573438 Counter 11;
BA_ "SPN" SG_ 2364573438 Counter 20693;
BA_ "SigType" SG_ 2364573438 CRC 12;
BA_ "SPN" SG_ 2364573438 CRC 20692;
BA_ "SPN" SG_ 2364573182 DCES1V 20675;
BA_ "SPN" SG_ 2364573182 DCES1Cur 20674;
BA_ "SigType" SG_ 2364573182 Freq 1;
BA_ "SPN" SG_ 2364573182 Freq 20673;
BA_ "SPN" SG_ 2364573182 Cur 20672;
BA_ "SigType" SG_ 2364573182 Counter 11;
BA_ "SPN" SG_ 2364573182 Counter 20671;
BA_ "SigType" SG_ 2364573182 CRC 12;
BA_ "SPN" SG_ 2364573182 CRC 20670;
BA_ "SigType" SG_ 2565899518 HVBusPassiveIsolTestResults 1;
BA_ "SPN" SG_ 2565899518 HVBusPassiveIsolTestResults 20664;
BA_ "SigType" SG_ 2565899518 HVBusActiveIsolTestResults 1;
BA_ "SPN" SG_ 2565899518 HVBusActiveIsolTestResults 20663;
BA_ "SPN" SG_ 2565899518 HVBusPassiveIsolTestStatus 20662;
BA_ "SPN" SG_ 2565899518 HVBusActiveIsolTestStatus 20661;
BA_ "SPN" SG_ 2565899518 DCES1NegToChassisGroundV 20660;
BA_ "SigType" SG_ 2565899518 Counter 11;
BA_ "SPN" SG_ 2565899518 Counter 20659;
BA_ "SigType" SG_ 2565899518 CRC 12;
BA_ "SPN" SG_ 2565899518 CRC 20658;
BA_ "SigType" SG_ 2565899262 HVBusPassiveIsolTestResults 1;
BA_ "SPN" SG_ 2565899262 HVBusPassiveIsolTestResults 20639;
BA_ "SigType" SG_ 2565899262 HVBusActiveIsolTestResults 1;
BA_ "SPN" SG_ 2565899262 HVBusActiveIsolTestResults 20638;
BA_ "SPN" SG_ 2565899262 HVBusPassiveIsolTestStatus 20637;
BA_ "SPN" SG_ 2565899262 HVBusActiveIsolTestStatus 20636;
BA_ "SPN" SG_ 2565899262 DCES1NegToChassisGroundV 20635;
BA_ "SigType" SG_ 2565899262 Counter 11;
BA_ "SPN" SG_ 2565899262 Counter 20634;
BA_ "SigType" SG_ 2565899262 CRC 12;
BA_ "SPN" SG_ 2565899262 CRC 20633;
BA_ "SPN" SG_ 2565899006 AbsCurRateLmt 20606;
BA_ "SigType" SG_ 2565899006 Counter 11;
BA_ "SPN" SG_ 2565899006 Counter 20605;
BA_ "SigType" SG_ 2565899006 CRC 12;
BA_ "SPN" SG_ 2565899006 CRC 20604;
BA_ "SPN" SG_ 2565898750 AvailableMinCur 20603;
BA_ "SPN" SG_ 2565898750 AvailableMaxCur 20602;
BA_ "SigType" SG_ 2565898750 Counter 11;
BA_ "SPN" SG_ 2565898750 Counter 20601;
BA_ "SigType" SG_ 2565898750 CRC 12;
BA_ "SPN" SG_ 2565898750 CRC 20600;
BA_ "SPN" SG_ 2565898494 AbsCurRateLmt 20599;
BA_ "SigType" SG_ 2565898494 Counter 11;
BA_ "SPN" SG_ 2565898494 Counter 20598;
BA_ "SigType" SG_ 2565898494 CRC 12;
BA_ "SPN" SG_ 2565898494 CRC 20597;
BA_ "SPN" SG_ 2565898238 AvailableMinCur 20596;
BA_ "SPN" SG_ 2565898238 AvailableMaxCur 20595;
BA_ "SigType" SG_ 2565898238 Counter 11;
BA_ "SPN" SG_ 2565898238 Counter 20594;
BA_ "SigType" SG_ 2565898238 CRC 12;
BA_ "SPN" SG_ 2565898238 CRC 20593;
BA_ "SigType" SG_ 2565897982 UnswitchedSLIV 1;
BA_ "SPN" SG_ 2565897982 UnswitchedSLIV 20592;
BA_ "SigType" SG_ 2565897982 SwitchedIgntV 1;
BA_ "SPN" SG_ 2565897982 SwitchedIgntV 20591;
BA_ "SPN" SG_ 2565897726 CurMin 20590;
BA_ "SPN" SG_ 2565897726 CurMax 20589;
BA_ "SPN" SG_ 2565897726 VMin 20588;
BA_ "SPN" SG_ 2565897726 VMax 20587;
BA_ "SigType" SG_ 2565897726 Counter 11;
BA_ "SPN" SG_ 2565897726 Counter 20586;
BA_ "SigType" SG_ 2565897726 CRC 12;
BA_ "SPN" SG_ 2565897726 CRC 20585;
BA_ "SPN" SG_ 2565897470 FreqMin 20584;
BA_ "SPN" SG_ 2565897470 FreqMax 20583;
BA_ "SPN" SG_ 2565897470 CurMin 20582;
BA_ "SPN" SG_ 2565897470 CurMax 20581;
BA_ "SigType" SG_ 2565897470 Counter 11;
BA_ "SPN" SG_ 2565897470 Counter 20580;
BA_ "SigType" SG_ 2565897470 CRC 12;
BA_ "SPN" SG_ 2565897470 CRC 20579;
BA_ "SPN" SG_ 2565897214 DCES1PwrMin 20578;
BA_ "SPN" SG_ 2565897214 DCES1PwrMax 20577;
BA_ "SPN" SG_ 2565897214 ElectricalPwrMin 20576;
BA_ "SPN" SG_ 2565897214 ElectricalPwrMax 20575;
BA_ "SigType" SG_ 2565897214 Counter 11;
BA_ "SPN" SG_ 2565897214 Counter 20574;
BA_ "SigType" SG_ 2565897214 CRC 12;
BA_ "SPN" SG_ 2565897214 CRC 20573;
BA_ "SigType" SG_ 2364570366 HVILStatus 4;
BA_ "SPN" SG_ 2364570366 HVILStatus 20572;
BA_ "SPN" SG_ 2364570366 CtrlSetpointMode 20571;
BA_ "SPN" SG_ 2364570366 CtrlLimitsOvrdMode 20570;
BA_ "SigType" SG_ 2364570366 Counter 11;
BA_ "SPN" SG_ 2364570366 Counter 20569;
BA_ "SigType" SG_ 2364570366 CRC 12;
BA_ "SPN" SG_ 2364570366 CRC 20568;
BA_ "SigType" SG_ 2565896702 UnswitchedSLIV 1;
BA_ "SPN" SG_ 2565896702 UnswitchedSLIV 20567;
BA_ "SigType" SG_ 2565896702 SwitchedIgntV 1;
BA_ "SPN" SG_ 2565896702 SwitchedIgntV 20566;
BA_ "SPN" SG_ 2565896446 CurMin 20565;
BA_ "SPN" SG_ 2565896446 CurMax 20564;
BA_ "SPN" SG_ 2565896446 VMin 20563;
BA_ "SPN" SG_ 2565896446 VMax 20562;
BA_ "SigType" SG_ 2565896446 Counter 11;
BA_ "SPN" SG_ 2565896446 Counter 20561;
BA_ "SigType" SG_ 2565896446 CRC 12;
BA_ "SPN" SG_ 2565896446 CRC 20560;
BA_ "SPN" SG_ 2565896190 FreqMin 20559;
BA_ "SPN" SG_ 2565896190 FreqMax 20558;
BA_ "SPN" SG_ 2565896190 CurMin 20557;
BA_ "SPN" SG_ 2565896190 CurMax 20556;
BA_ "SigType" SG_ 2565896190 Counter 11;
BA_ "SPN" SG_ 2565896190 Counter 20555;
BA_ "SigType" SG_ 2565896190 CRC 12;
BA_ "SPN" SG_ 2565896190 CRC 20554;
BA_ "SPN" SG_ 2565895934 DCES1PwrMin 20553;
BA_ "SPN" SG_ 2565895934 DCES1PwrMax 20552;
BA_ "SPN" SG_ 2565895934 ElectricalPwrMin 20551;
BA_ "SPN" SG_ 2565895934 ElectricalPwrMax 20550;
BA_ "SigType" SG_ 2565895934 Counter 11;
BA_ "SPN" SG_ 2565895934 Counter 20549;
BA_ "SigType" SG_ 2565895934 CRC 12;
BA_ "SPN" SG_ 2565895934 CRC 20548;
BA_ "SigType" SG_ 2364569086 HVILStatus 4;
BA_ "SPN" SG_ 2364569086 HVILStatus 20547;
BA_ "SPN" SG_ 2364569086 CtrlSetpointMode 20546;
BA_ "SPN" SG_ 2364569086 CtrlLimitsOvrdMode 20545;
BA_ "SigType" SG_ 2364569086 Counter 11;
BA_ "SPN" SG_ 2364569086 Counter 20544;
BA_ "SigType" SG_ 2364569086 CRC 12;
BA_ "SPN" SG_ 2364569086 CRC 20543;
BA_ "SPN" SG_ 2364568830 PIDCtrlNormalizedPropGain 20498;
BA_ "SigType" SG_ 2364568830 PIDCtrlNormalizedIntegralGain 1;
BA_ "SPN" SG_ 2364568830 PIDCtrlNormalizedIntegralGain 20497;
BA_ "SigType" SG_ 2364568830 PIDCtrlNormalizedDiffGain 1;
BA_ "SPN" SG_ 2364568830 PIDCtrlNormalizedDiffGain 20496;
BA_ "SPN" SG_ 2364568830 PIDCtrlApplicableMode 20495;
BA_ "SigType" SG_ 2364568830 Counter 11;
BA_ "SPN" SG_ 2364568830 Counter 20494;
BA_ "SigType" SG_ 2364568830 CRC 12;
BA_ "SPN" SG_ 2364568830 CRC 20493;
BA_ "SPN" SG_ 2364568574 PIDCtrlNormalizedPropGain 20492;
BA_ "SigType" SG_ 2364568574 PIDCtrlNormalizedIntegralGain 1;
BA_ "SPN" SG_ 2364568574 PIDCtrlNormalizedIntegralGain 20491;
BA_ "SigType" SG_ 2364568574 PIDCtrlNormalizedDiffGain 1;
BA_ "SPN" SG_ 2364568574 PIDCtrlNormalizedDiffGain 20490;
BA_ "SPN" SG_ 2364568574 PIDCtrlApplicableMode 20489;
BA_ "SigType" SG_ 2364568574 Counter 11;
BA_ "SPN" SG_ 2364568574 Counter 20488;
BA_ "SigType" SG_ 2364568574 CRC 12;
BA_ "SPN" SG_ 2364568574 CRC 20487;
BA_ "SPN" SG_ 2565894910 AbsCurRateLmt 20486;
BA_ "SPN" SG_ 2565894910 AbsFreqRateLmt 20485;
BA_ "SigType" SG_ 2565894910 Counter 11;
BA_ "SPN" SG_ 2565894910 Counter 20484;
BA_ "SigType" SG_ 2565894910 CRC 12;
BA_ "SPN" SG_ 2565894910 CRC 20483;
BA_ "SPN" SG_ 2565894654 AbsCurRateLmt 20482;
BA_ "SPN" SG_ 2565894654 AbsFreqRateLmt 20481;
BA_ "SigType" SG_ 2565894654 Counter 11;
BA_ "SPN" SG_ 2565894654 Counter 20480;
BA_ "SigType" SG_ 2565894654 CRC 12;
BA_ "SPN" SG_ 2565894654 CRC 20479;
BA_ "SigType" SG_ 2364567806 SetpointReq 1;
BA_ "SPN" SG_ 2364567806 SetpointReq 20478;
BA_ "SPN" SG_ 2364567806 SetpointModeReq 20477;
BA_ "SPN" SG_ 2364567806 LimitsReqOvrdMin 20476;
BA_ "SPN" SG_ 2364567806 LimitsReqOvrdMax 20475;
BA_ "SPN" SG_ 2364567806 LimitsReqOvrdMode 20474;
BA_ "SigType" SG_ 2364567806 Counter 11;
BA_ "SPN" SG_ 2364567806 Counter 20473;
BA_ "SigType" SG_ 2364567806 CRC 12;
BA_ "SPN" SG_ 2364567806 CRC 20472;
BA_ "SigType" SG_ 2364567550 SetpointReq 1;
BA_ "SPN" SG_ 2364567550 SetpointReq 20471;
BA_ "SPN" SG_ 2364567550 SetpointModeReq 20470;
BA_ "SPN" SG_ 2364567550 LimitsReqOvrdMin 20469;
BA_ "SPN" SG_ 2364567550 LimitsReqOvrdMax 20468;
BA_ "SPN" SG_ 2364567550 LimitsReqOvrdMode 20467;
BA_ "SigType" SG_ 2364567550 Counter 11;
BA_ "SPN" SG_ 2364567550 Counter 20466;
BA_ "SigType" SG_ 2364567550 CRC 12;
BA_ "SPN" SG_ 2364567550 CRC 20465;
BA_ "SigType" SG_ 2555182846 ElectricPumpPercentSpd 1;
BA_ "SPN" SG_ 2555182846 ElectricPumpPercentSpd 20175;
BA_ "SigType" SG_ 2555182846 ElectricPumpSpdCmd 1;
BA_ "SPN" SG_ 2555182846 ElectricPumpSpdCmd 20174;
BA_ "SigType" SG_ 2555182846 ElectricPumpDriveSource 5;
BA_ "SPN" SG_ 2555182846 ElectricPumpDriveSource 20173;
BA_ "SigType" SG_ 2555182846 ElectricPumpPwrHold 5;
BA_ "SPN" SG_ 2555182846 ElectricPumpPwrHold 20172;
BA_ "SigType" SG_ 2555182846 ElectricPumpEnableCmd 5;
BA_ "SPN" SG_ 2555182846 ElectricPumpEnableCmd 20171;
BA_ "SigType" SG_ 2351103742 Ctrl1CRC 12;
BA_ "SPN" SG_ 2351103742 Ctrl1CRC 17409;
BA_ "SigType" SG_ 2351103742 Ctrl1Counter 11;
BA_ "SPN" SG_ 2351103742 Ctrl1Counter 17408;
BA_ "SigType" SG_ 2351103742 ThermalMnmgtMaintenanceReq 5;
BA_ "SPN" SG_ 2351103742 ThermalMnmgtMaintenanceReq 20904;
BA_ "SigType" SG_ 2351103742 HVBusLowSideResistorConnectReq 5;
BA_ "SPN" SG_ 2351103742 HVBusLowSideResistorConnectReq 17407;
BA_ "SigType" SG_ 2351103742 HVBusHiSideResistorConnectReq 5;
BA_ "SPN" SG_ 2351103742 HVBusHiSideResistorConnectReq 17406;
BA_ "SigType" SG_ 2351103742 OpConsent 4;
BA_ "SPN" SG_ 2351103742 OpConsent 17405;
BA_ "SigType" SG_ 2351103742 EnableInternalChargerCmd 5;
BA_ "SPN" SG_ 2351103742 EnableInternalChargerCmd 17404;
BA_ "SigType" SG_ 2351103742 CellBalancingCmd 5;
BA_ "SPN" SG_ 2351103742 CellBalancingCmd 17403;
BA_ "SigType" SG_ 2351103742 HVBusPassiveIsolTestCmd 5;
BA_ "SPN" SG_ 2351103742 HVBusPassiveIsolTestCmd 17402;
BA_ "SigType" SG_ 2351103742 HVBusActiveIsolTestCmd 5;
BA_ "SPN" SG_ 2351103742 HVBusActiveIsolTestCmd 17401;
BA_ "SigType" SG_ 2351103742 PwrDownCmd 5;
BA_ "SPN" SG_ 2351103742 PwrDownCmd 17400;
BA_ "SigType" SG_ 2351103742 HVBusConnectCmd 5;
BA_ "SPN" SG_ 2351103742 HVBusConnectCmd 17399;
BA_ "SigType" SG_ 2351038206 Ctrl1CRC 12;
BA_ "SPN" SG_ 2351038206 Ctrl1CRC 17267;
BA_ "SigType" SG_ 2351038206 Ctrl1Counter 11;
BA_ "SPN" SG_ 2351038206 Ctrl1Counter 17266;
BA_ "SigType" SG_ 2351038206 ThermalMnmgtMaintenanceReq 5;
BA_ "SPN" SG_ 2351038206 ThermalMnmgtMaintenanceReq 20903;
BA_ "SigType" SG_ 2351038206 HVBusLowSideResistorConnectReq 5;
BA_ "SPN" SG_ 2351038206 HVBusLowSideResistorConnectReq 17265;
BA_ "SigType" SG_ 2351038206 HVBusHiSideResistorConnectReq 5;
BA_ "SPN" SG_ 2351038206 HVBusHiSideResistorConnectReq 17264;
BA_ "SigType" SG_ 2351038206 OpConsent 4;
BA_ "SPN" SG_ 2351038206 OpConsent 17263;
BA_ "SigType" SG_ 2351038206 EnableInternalChargerCmd 5;
BA_ "SPN" SG_ 2351038206 EnableInternalChargerCmd 17262;
BA_ "SigType" SG_ 2351038206 CellBalancingCmd 5;
BA_ "SPN" SG_ 2351038206 CellBalancingCmd 17261;
BA_ "SigType" SG_ 2351038206 HVBusPassiveIsolTestCmd 5;
BA_ "SPN" SG_ 2351038206 HVBusPassiveIsolTestCmd 17260;
BA_ "SigType" SG_ 2351038206 HVBusActiveIsolTestCmd 5;
BA_ "SPN" SG_ 2351038206 HVBusActiveIsolTestCmd 17259;
BA_ "SigType" SG_ 2351038206 PwrDownCmd 5;
BA_ "SPN" SG_ 2351038206 PwrDownCmd 17258;
BA_ "SigType" SG_ 2351038206 HVBusConnectCmd 5;
BA_ "SPN" SG_ 2351038206 HVBusConnectCmd 17257;
BA_ "SigType" SG_ 2350972670 Ctrl1CRC 12;
BA_ "SPN" SG_ 2350972670 Ctrl1CRC 17125;
BA_ "SigType" SG_ 2350972670 Ctrl1Counter 11;
BA_ "SPN" SG_ 2350972670 Ctrl1Counter 17124;
BA_ "SigType" SG_ 2350972670 ThermalMnmgtMaintenanceReq 5;
BA_ "SPN" SG_ 2350972670 ThermalMnmgtMaintenanceReq 20902;
BA_ "SigType" SG_ 2350972670 HVBusLowSideResistorConnectReq 5;
BA_ "SPN" SG_ 2350972670 HVBusLowSideResistorConnectReq 17123;
BA_ "SigType" SG_ 2350972670 HVBusHiSideResistorConnectReq 5;
BA_ "SPN" SG_ 2350972670 HVBusHiSideResistorConnectReq 17122;
BA_ "SigType" SG_ 2350972670 OpConsent 4;
BA_ "SPN" SG_ 2350972670 OpConsent 17121;
BA_ "SigType" SG_ 2350972670 EnableInternalChargerCmd 5;
BA_ "SPN" SG_ 2350972670 EnableInternalChargerCmd 17120;
BA_ "SigType" SG_ 2350972670 CellBalancingCmd 5;
BA_ "SPN" SG_ 2350972670 CellBalancingCmd 17119;
BA_ "SigType" SG_ 2350972670 HVBusPassiveIsolTestCmd 5;
BA_ "SPN" SG_ 2350972670 HVBusPassiveIsolTestCmd 17118;
BA_ "SigType" SG_ 2350972670 HVBusActiveIsolTestCmd 5;
BA_ "SPN" SG_ 2350972670 HVBusActiveIsolTestCmd 17117;
BA_ "SigType" SG_ 2350972670 PwrDownCmd 5;
BA_ "SPN" SG_ 2350972670 PwrDownCmd 17116;
BA_ "SigType" SG_ 2350972670 HVBusConnectCmd 5;
BA_ "SPN" SG_ 2350972670 HVBusConnectCmd 17115;
BA_ "SigType" SG_ 2350907134 Ctrl1CRC 12;
BA_ "SPN" SG_ 2350907134 Ctrl1CRC 16983;
BA_ "SigType" SG_ 2350907134 Ctrl1Counter 11;
BA_ "SPN" SG_ 2350907134 Ctrl1Counter 16982;
BA_ "SigType" SG_ 2350907134 ThermalMnmgtMaintenanceReq 5;
BA_ "SPN" SG_ 2350907134 ThermalMnmgtMaintenanceReq 20901;
BA_ "SigType" SG_ 2350907134 HVBusLowSideResistorConnectReq 5;
BA_ "SPN" SG_ 2350907134 HVBusLowSideResistorConnectReq 16981;
BA_ "SigType" SG_ 2350907134 HVBusHiSideResistorConnectReq 5;
BA_ "SPN" SG_ 2350907134 HVBusHiSideResistorConnectReq 16980;
BA_ "SigType" SG_ 2350907134 OpConsent 4;
BA_ "SPN" SG_ 2350907134 OpConsent 16979;
BA_ "SigType" SG_ 2350907134 EnableInternalChargerCmd 5;
BA_ "SPN" SG_ 2350907134 EnableInternalChargerCmd 16978;
BA_ "SigType" SG_ 2350907134 CellBalancingCmd 5;
BA_ "SPN" SG_ 2350907134 CellBalancingCmd 16977;
BA_ "SigType" SG_ 2350907134 HVBusPassiveIsolTestCmd 5;
BA_ "SPN" SG_ 2350907134 HVBusPassiveIsolTestCmd 16976;
BA_ "SigType" SG_ 2350907134 HVBusActiveIsolTestCmd 5;
BA_ "SPN" SG_ 2350907134 HVBusActiveIsolTestCmd 16975;
BA_ "SigType" SG_ 2350907134 PwrDownCmd 5;
BA_ "SPN" SG_ 2350907134 PwrDownCmd 16974;
BA_ "SigType" SG_ 2350907134 HVBusConnectCmd 5;
BA_ "SPN" SG_ 2350907134 HVBusConnectCmd 16973;
BA_ "SigType" SG_ 2350579454 Ctrl1CRC 12;
BA_ "SPN" SG_ 2350579454 Ctrl1CRC 16841;
BA_ "SigType" SG_ 2350579454 Ctrl1Counter 11;
BA_ "SPN" SG_ 2350579454 Ctrl1Counter 16840;
BA_ "SigType" SG_ 2350579454 ThermalMnmgtMaintenanceReq 5;
BA_ "SPN" SG_ 2350579454 ThermalMnmgtMaintenanceReq 20900;
BA_ "SigType" SG_ 2350579454 HVBusLowSideResistorConnectReq 5;
BA_ "SPN" SG_ 2350579454 HVBusLowSideResistorConnectReq 16839;
BA_ "SigType" SG_ 2350579454 HVBusHiSideResistorConnectReq 5;
BA_ "SPN" SG_ 2350579454 HVBusHiSideResistorConnectReq 16838;
BA_ "SigType" SG_ 2350579454 OpConsent 4;
BA_ "SPN" SG_ 2350579454 OpConsent 16837;
BA_ "SigType" SG_ 2350579454 EnableInternalChargerCmd 5;
BA_ "SPN" SG_ 2350579454 EnableInternalChargerCmd 16836;
BA_ "SigType" SG_ 2350579454 CellBalancingCmd 5;
BA_ "SPN" SG_ 2350579454 CellBalancingCmd 16835;
BA_ "SigType" SG_ 2350579454 HVBusPassiveIsolTestCmd 5;
BA_ "SPN" SG_ 2350579454 HVBusPassiveIsolTestCmd 16834;
BA_ "SigType" SG_ 2350579454 HVBusActiveIsolTestCmd 5;
BA_ "SPN" SG_ 2350579454 HVBusActiveIsolTestCmd 16833;
BA_ "SigType" SG_ 2350579454 PwrDownCmd 5;
BA_ "SPN" SG_ 2350579454 PwrDownCmd 16832;
BA_ "SigType" SG_ 2350579454 HVBusConnectCmd 5;
BA_ "SPN" SG_ 2350579454 HVBusConnectCmd 16831;
BA_ "SigType" SG_ 2350513918 Ctrl1CRC 12;
BA_ "SPN" SG_ 2350513918 Ctrl1CRC 16699;
BA_ "SigType" SG_ 2350513918 Ctrl1Counter 11;
BA_ "SPN" SG_ 2350513918 Ctrl1Counter 16698;
BA_ "SigType" SG_ 2350513918 ThermalMnmgtMaintenanceReq 5;
BA_ "SPN" SG_ 2350513918 ThermalMnmgtMaintenanceReq 20899;
BA_ "SigType" SG_ 2350513918 HVBusLowSideResistorConnectReq 5;
BA_ "SPN" SG_ 2350513918 HVBusLowSideResistorConnectReq 16697;
BA_ "SigType" SG_ 2350513918 HVBusHiSideResistorConnectReq 5;
BA_ "SPN" SG_ 2350513918 HVBusHiSideResistorConnectReq 16696;
BA_ "SigType" SG_ 2350513918 OpConsent 4;
BA_ "SPN" SG_ 2350513918 OpConsent 16695;
BA_ "SigType" SG_ 2350513918 EnableInternalChargerCmd 5;
BA_ "SPN" SG_ 2350513918 EnableInternalChargerCmd 16694;
BA_ "SigType" SG_ 2350513918 CellBalancingCmd 5;
BA_ "SPN" SG_ 2350513918 CellBalancingCmd 16693;
BA_ "SigType" SG_ 2350513918 HVBusPassiveIsolTestCmd 5;
BA_ "SPN" SG_ 2350513918 HVBusPassiveIsolTestCmd 16692;
BA_ "SigType" SG_ 2350513918 HVBusActiveIsolTestCmd 5;
BA_ "SPN" SG_ 2350513918 HVBusActiveIsolTestCmd 16691;
BA_ "SigType" SG_ 2350513918 PwrDownCmd 5;
BA_ "SPN" SG_ 2350513918 PwrDownCmd 16690;
BA_ "SigType" SG_ 2350513918 HVBusConnectCmd 5;
BA_ "SPN" SG_ 2350513918 HVBusConnectCmd 16689;
BA_ "SigType" SG_ 2350448382 Ctrl1CRC 12;
BA_ "SPN" SG_ 2350448382 Ctrl1CRC 16557;
BA_ "SigType" SG_ 2350448382 Ctrl1Counter 11;
BA_ "SPN" SG_ 2350448382 Ctrl1Counter 16556;
BA_ "SigType" SG_ 2350448382 ThermalMnmgtMaintenanceReq 5;
BA_ "SPN" SG_ 2350448382 ThermalMnmgtMaintenanceReq 20898;
BA_ "SigType" SG_ 2350448382 HVBusLowSideResistorConnectReq 5;
BA_ "SPN" SG_ 2350448382 HVBusLowSideResistorConnectReq 16555;
BA_ "SigType" SG_ 2350448382 HVBusHiSideResistorConnectReq 5;
BA_ "SPN" SG_ 2350448382 HVBusHiSideResistorConnectReq 16554;
BA_ "SigType" SG_ 2350448382 OpConsent 4;
BA_ "SPN" SG_ 2350448382 OpConsent 16553;
BA_ "SigType" SG_ 2350448382 EnableInternalChargerCmd 5;
BA_ "SPN" SG_ 2350448382 EnableInternalChargerCmd 16552;
BA_ "SigType" SG_ 2350448382 CellBalancingCmd 5;
BA_ "SPN" SG_ 2350448382 CellBalancingCmd 16551;
BA_ "SigType" SG_ 2350448382 HVBusPassiveIsolTestCmd 5;
BA_ "SPN" SG_ 2350448382 HVBusPassiveIsolTestCmd 16550;
BA_ "SigType" SG_ 2350448382 HVBusActiveIsolTestCmd 5;
BA_ "SPN" SG_ 2350448382 HVBusActiveIsolTestCmd 16549;
BA_ "SigType" SG_ 2350448382 PwrDownCmd 5;
BA_ "SPN" SG_ 2350448382 PwrDownCmd 16548;
BA_ "SigType" SG_ 2350448382 HVBusConnectCmd 5;
BA_ "SPN" SG_ 2350448382 HVBusConnectCmd 16547;
BA_ "SigType" SG_ 2350382846 Ctrl1CRC 12;
BA_ "SPN" SG_ 2350382846 Ctrl1CRC 16415;
BA_ "SigType" SG_ 2350382846 Ctrl1Counter 11;
BA_ "SPN" SG_ 2350382846 Ctrl1Counter 16414;
BA_ "SigType" SG_ 2350382846 ThermalMnmgtMaintenanceReq 5;
BA_ "SPN" SG_ 2350382846 ThermalMnmgtMaintenanceReq 20897;
BA_ "SigType" SG_ 2350382846 HVBusLowSideResistorConnectReq 5;
BA_ "SPN" SG_ 2350382846 HVBusLowSideResistorConnectReq 16413;
BA_ "SigType" SG_ 2350382846 HVBusHiSideResistorConnectReq 5;
BA_ "SPN" SG_ 2350382846 HVBusHiSideResistorConnectReq 16412;
BA_ "SigType" SG_ 2350382846 OpConsent 4;
BA_ "SPN" SG_ 2350382846 OpConsent 16411;
BA_ "SigType" SG_ 2350382846 EnableInternalChargerCmd 5;
BA_ "SPN" SG_ 2350382846 EnableInternalChargerCmd 16410;
BA_ "SigType" SG_ 2350382846 CellBalancingCmd 5;
BA_ "SPN" SG_ 2350382846 CellBalancingCmd 16409;
BA_ "SigType" SG_ 2350382846 HVBusPassiveIsolTestCmd 5;
BA_ "SPN" SG_ 2350382846 HVBusPassiveIsolTestCmd 16408;
BA_ "SigType" SG_ 2350382846 HVBusActiveIsolTestCmd 5;
BA_ "SPN" SG_ 2350382846 HVBusActiveIsolTestCmd 16407;
BA_ "SigType" SG_ 2350382846 PwrDownCmd 5;
BA_ "SPN" SG_ 2350382846 PwrDownCmd 16406;
BA_ "SigType" SG_ 2350382846 HVBusConnectCmd 5;
BA_ "SPN" SG_ 2350382846 HVBusConnectCmd 16405;
BA_ "SigType" SG_ 2350317310 Ctrl1CRC 12;
BA_ "SPN" SG_ 2350317310 Ctrl1CRC 16273;
BA_ "SigType" SG_ 2350317310 Ctrl1Counter 11;
BA_ "SPN" SG_ 2350317310 Ctrl1Counter 16272;
BA_ "SigType" SG_ 2350317310 ThermalMnmgtMaintenanceReq 5;
BA_ "SPN" SG_ 2350317310 ThermalMnmgtMaintenanceReq 20896;
BA_ "SigType" SG_ 2350317310 HVBusLowSideResistorConnectReq 5;
BA_ "SPN" SG_ 2350317310 HVBusLowSideResistorConnectReq 16271;
BA_ "SigType" SG_ 2350317310 HVBusHiSideResistorConnectReq 5;
BA_ "SPN" SG_ 2350317310 HVBusHiSideResistorConnectReq 16270;
BA_ "SigType" SG_ 2350317310 OpConsent 4;
BA_ "SPN" SG_ 2350317310 OpConsent 16269;
BA_ "SigType" SG_ 2350317310 EnableInternalChargerCmd 5;
BA_ "SPN" SG_ 2350317310 EnableInternalChargerCmd 16268;
BA_ "SigType" SG_ 2350317310 CellBalancingCmd 5;
BA_ "SPN" SG_ 2350317310 CellBalancingCmd 16267;
BA_ "SigType" SG_ 2350317310 HVBusPassiveIsolTestCmd 5;
BA_ "SPN" SG_ 2350317310 HVBusPassiveIsolTestCmd 16266;
BA_ "SigType" SG_ 2350317310 HVBusActiveIsolTestCmd 5;
BA_ "SPN" SG_ 2350317310 HVBusActiveIsolTestCmd 16265;
BA_ "SigType" SG_ 2350317310 PwrDownCmd 5;
BA_ "SPN" SG_ 2350317310 PwrDownCmd 16264;
BA_ "SigType" SG_ 2350317310 HVBusConnectCmd 5;
BA_ "SPN" SG_ 2350317310 HVBusConnectCmd 16263;
BA_ "SigType" SG_ 2350251774 Ctrl1CRC 12;
BA_ "SPN" SG_ 2350251774 Ctrl1CRC 16131;
BA_ "SigType" SG_ 2350251774 Ctrl1Counter 11;
BA_ "SPN" SG_ 2350251774 Ctrl1Counter 16130;
BA_ "SigType" SG_ 2350251774 ThermalMnmgtMaintenanceReq 5;
BA_ "SPN" SG_ 2350251774 ThermalMnmgtMaintenanceReq 20895;
BA_ "SigType" SG_ 2350251774 HVBusLowSideResistorConnectReq 5;
BA_ "SPN" SG_ 2350251774 HVBusLowSideResistorConnectReq 16129;
BA_ "SigType" SG_ 2350251774 HVBusHiSideResistorConnectReq 5;
BA_ "SPN" SG_ 2350251774 HVBusHiSideResistorConnectReq 16128;
BA_ "SigType" SG_ 2350251774 OpConsent 4;
BA_ "SPN" SG_ 2350251774 OpConsent 16127;
BA_ "SigType" SG_ 2350251774 EnableInternalChargerCmd 5;
BA_ "SPN" SG_ 2350251774 EnableInternalChargerCmd 16126;
BA_ "SigType" SG_ 2350251774 CellBalancingCmd 5;
BA_ "SPN" SG_ 2350251774 CellBalancingCmd 16125;
BA_ "SigType" SG_ 2350251774 HVBusPassiveIsolTestCmd 5;
BA_ "SPN" SG_ 2350251774 HVBusPassiveIsolTestCmd 16124;
BA_ "SigType" SG_ 2350251774 HVBusActiveIsolTestCmd 5;
BA_ "SPN" SG_ 2350251774 HVBusActiveIsolTestCmd 16123;
BA_ "SigType" SG_ 2350251774 PwrDownCmd 5;
BA_ "SPN" SG_ 2350251774 PwrDownCmd 16122;
BA_ "SigType" SG_ 2350251774 HVBusConnectCmd 5;
BA_ "SPN" SG_ 2350251774 HVBusConnectCmd 16121;
BA_ "SigType" SG_ 2350186238 Ctrl1CRC 12;
BA_ "SPN" SG_ 2350186238 Ctrl1CRC 15989;
BA_ "SigType" SG_ 2350186238 Ctrl1Counter 11;
BA_ "SPN" SG_ 2350186238 Ctrl1Counter 15988;
BA_ "SigType" SG_ 2350186238 ThermalMnmgtMaintenanceReq 5;
BA_ "SPN" SG_ 2350186238 ThermalMnmgtMaintenanceReq 20894;
BA_ "SigType" SG_ 2350186238 HVBusLowSideResistorConnectReq 5;
BA_ "SPN" SG_ 2350186238 HVBusLowSideResistorConnectReq 15987;
BA_ "SigType" SG_ 2350186238 HVBusHiSideResistorConnectReq 5;
BA_ "SPN" SG_ 2350186238 HVBusHiSideResistorConnectReq 15986;
BA_ "SigType" SG_ 2350186238 OpConsent 4;
BA_ "SPN" SG_ 2350186238 OpConsent 15985;
BA_ "SigType" SG_ 2350186238 EnableInternalChargerCmd 5;
BA_ "SPN" SG_ 2350186238 EnableInternalChargerCmd 15984;
BA_ "SigType" SG_ 2350186238 CellBalancingCmd 5;
BA_ "SPN" SG_ 2350186238 CellBalancingCmd 15983;
BA_ "SigType" SG_ 2350186238 HVBusPassiveIsolTestCmd 5;
BA_ "SPN" SG_ 2350186238 HVBusPassiveIsolTestCmd 15982;
BA_ "SigType" SG_ 2350186238 HVBusActiveIsolTestCmd 5;
BA_ "SPN" SG_ 2350186238 HVBusActiveIsolTestCmd 15981;
BA_ "SigType" SG_ 2350186238 PwrDownCmd 5;
BA_ "SPN" SG_ 2350186238 PwrDownCmd 15980;
BA_ "SigType" SG_ 2350186238 HVBusConnectCmd 5;
BA_ "SPN" SG_ 2350186238 HVBusConnectCmd 15979;
BA_ "SigType" SG_ 2350120702 Ctrl1CRC 12;
BA_ "SPN" SG_ 2350120702 Ctrl1CRC 15847;
BA_ "SigType" SG_ 2350120702 Ctrl1Counter 11;
BA_ "SPN" SG_ 2350120702 Ctrl1Counter 15846;
BA_ "SigType" SG_ 2350120702 ThermalMnmgtMaintenanceReq 5;
BA_ "SPN" SG_ 2350120702 ThermalMnmgtMaintenanceReq 20893;
BA_ "SigType" SG_ 2350120702 HVBusLowSideResistorConnectReq 5;
BA_ "SPN" SG_ 2350120702 HVBusLowSideResistorConnectReq 15845;
BA_ "SigType" SG_ 2350120702 HVBusHiSideResistorConnectReq 5;
BA_ "SPN" SG_ 2350120702 HVBusHiSideResistorConnectReq 15844;
BA_ "SigType" SG_ 2350120702 OpConsent 4;
BA_ "SPN" SG_ 2350120702 OpConsent 15843;
BA_ "SigType" SG_ 2350120702 EnableInternalChargerCmd 5;
BA_ "SPN" SG_ 2350120702 EnableInternalChargerCmd 15842;
BA_ "SigType" SG_ 2350120702 CellBalancingCmd 5;
BA_ "SPN" SG_ 2350120702 CellBalancingCmd 15841;
BA_ "SigType" SG_ 2350120702 HVBusPassiveIsolTestCmd 5;
BA_ "SPN" SG_ 2350120702 HVBusPassiveIsolTestCmd 15840;
BA_ "SigType" SG_ 2350120702 HVBusActiveIsolTestCmd 5;
BA_ "SPN" SG_ 2350120702 HVBusActiveIsolTestCmd 15839;
BA_ "SigType" SG_ 2350120702 PwrDownCmd 5;
BA_ "SPN" SG_ 2350120702 PwrDownCmd 15838;
BA_ "SigType" SG_ 2350120702 HVBusConnectCmd 5;
BA_ "SPN" SG_ 2350120702 HVBusConnectCmd 15837;
BA_ "SigType" SG_ 2350055166 Ctrl1CRC 12;
BA_ "SPN" SG_ 2350055166 Ctrl1CRC 15705;
BA_ "SigType" SG_ 2350055166 Ctrl1Counter 11;
BA_ "SPN" SG_ 2350055166 Ctrl1Counter 15704;
BA_ "SigType" SG_ 2350055166 ThermalMnmgtMaintenanceReq 5;
BA_ "SPN" SG_ 2350055166 ThermalMnmgtMaintenanceReq 20892;
BA_ "SigType" SG_ 2350055166 HVBusLowSideResistorConnectReq 5;
BA_ "SPN" SG_ 2350055166 HVBusLowSideResistorConnectReq 15703;
BA_ "SigType" SG_ 2350055166 HVBusHiSideResistorConnectReq 5;
BA_ "SPN" SG_ 2350055166 HVBusHiSideResistorConnectReq 15702;
BA_ "SigType" SG_ 2350055166 OpConsent 4;
BA_ "SPN" SG_ 2350055166 OpConsent 15701;
BA_ "SigType" SG_ 2350055166 EnableInternalChargerCmd 5;
BA_ "SPN" SG_ 2350055166 EnableInternalChargerCmd 15700;
BA_ "SigType" SG_ 2350055166 CellBalancingCmd 5;
BA_ "SPN" SG_ 2350055166 CellBalancingCmd 15699;
BA_ "SigType" SG_ 2350055166 HVBusPassiveIsolTestCmd 5;
BA_ "SPN" SG_ 2350055166 HVBusPassiveIsolTestCmd 15698;
BA_ "SigType" SG_ 2350055166 HVBusActiveIsolTestCmd 5;
BA_ "SPN" SG_ 2350055166 HVBusActiveIsolTestCmd 15697;
BA_ "SigType" SG_ 2350055166 PwrDownCmd 5;
BA_ "SPN" SG_ 2350055166 PwrDownCmd 15696;
BA_ "SigType" SG_ 2350055166 HVBusConnectCmd 5;
BA_ "SPN" SG_ 2350055166 HVBusConnectCmd 15695;
BA_ "SigType" SG_ 2349989630 Ctrl1CRC 12;
BA_ "SPN" SG_ 2349989630 Ctrl1CRC 15563;
BA_ "SigType" SG_ 2349989630 Ctrl1Counter 11;
BA_ "SPN" SG_ 2349989630 Ctrl1Counter 15562;
BA_ "SigType" SG_ 2349989630 ThermalMnmgtMaintenanceReq 5;
BA_ "SPN" SG_ 2349989630 ThermalMnmgtMaintenanceReq 20891;
BA_ "SigType" SG_ 2349989630 HVBusLowSideResistorConnectReq 5;
BA_ "SPN" SG_ 2349989630 HVBusLowSideResistorConnectReq 15561;
BA_ "SigType" SG_ 2349989630 HVBusHiSideResistorConnectReq 5;
BA_ "SPN" SG_ 2349989630 HVBusHiSideResistorConnectReq 15560;
BA_ "SigType" SG_ 2349989630 OpConsent 4;
BA_ "SPN" SG_ 2349989630 OpConsent 15559;
BA_ "SigType" SG_ 2349989630 EnableInternalChargerCmd 5;
BA_ "SPN" SG_ 2349989630 EnableInternalChargerCmd 15558;
BA_ "SigType" SG_ 2349989630 CellBalancingCmd 5;
BA_ "SPN" SG_ 2349989630 CellBalancingCmd 15557;
BA_ "SigType" SG_ 2349989630 HVBusPassiveIsolTestCmd 5;
BA_ "SPN" SG_ 2349989630 HVBusPassiveIsolTestCmd 15556;
BA_ "SigType" SG_ 2349989630 HVBusActiveIsolTestCmd 5;
BA_ "SPN" SG_ 2349989630 HVBusActiveIsolTestCmd 15555;
BA_ "SigType" SG_ 2349989630 PwrDownCmd 5;
BA_ "SPN" SG_ 2349989630 PwrDownCmd 15554;
BA_ "SigType" SG_ 2349989630 HVBusConnectCmd 5;
BA_ "SPN" SG_ 2349989630 HVBusConnectCmd 15553;
BA_ "SigType" SG_ 2349924094 Ctrl1CRC 12;
BA_ "SPN" SG_ 2349924094 Ctrl1CRC 15421;
BA_ "SigType" SG_ 2349924094 Ctrl1Counter 11;
BA_ "SPN" SG_ 2349924094 Ctrl1Counter 15420;
BA_ "SigType" SG_ 2349924094 ThermalMnmgtMaintenanceReq 5;
BA_ "SPN" SG_ 2349924094 ThermalMnmgtMaintenanceReq 20890;
BA_ "SigType" SG_ 2349924094 HVBusLowSideResistorConnectReq 5;
BA_ "SPN" SG_ 2349924094 HVBusLowSideResistorConnectReq 15419;
BA_ "SigType" SG_ 2349924094 HVBusHiSideResistorConnectReq 5;
BA_ "SPN" SG_ 2349924094 HVBusHiSideResistorConnectReq 15418;
BA_ "SigType" SG_ 2349924094 OpConsent 4;
BA_ "SPN" SG_ 2349924094 OpConsent 15417;
BA_ "SigType" SG_ 2349924094 EnableInternalChargerCmd 5;
BA_ "SPN" SG_ 2349924094 EnableInternalChargerCmd 15416;
BA_ "SigType" SG_ 2349924094 CellBalancingCmd 5;
BA_ "SPN" SG_ 2349924094 CellBalancingCmd 15415;
BA_ "SigType" SG_ 2349924094 HVBusPassiveIsolTestCmd 5;
BA_ "SPN" SG_ 2349924094 HVBusPassiveIsolTestCmd 15414;
BA_ "SigType" SG_ 2349924094 HVBusActiveIsolTestCmd 5;
BA_ "SPN" SG_ 2349924094 HVBusActiveIsolTestCmd 15413;
BA_ "SigType" SG_ 2349924094 PwrDownCmd 5;
BA_ "SPN" SG_ 2349924094 PwrDownCmd 15412;
BA_ "SigType" SG_ 2349924094 HVBusConnectCmd 5;
BA_ "SPN" SG_ 2349924094 HVBusConnectCmd 15411;
VAL_ 2364691710 CellTempDiffStatus 3 "Not Available" 2 "Error" 1 "Cell-to-cell temperature differential exceeds acceptable limits" 0 "Cell-to-cell temperature differential is within acceptable limits" ;
VAL_ 2364691454 CellVDiffStatus 15 "Not Available" 14 "Error" 13 "Reserved" 12 "Reserved" 11 "Reserved" 10 "Reserved" 9 "Reserved" 8 "Reserved" 7 "Reserved" 6 "Reserved" 5 "Reserved" 4 "Exceeds limits and it is not known whether balancing can restore performance" 3 "Exceeds limits and external maintenance balancing cannot restore performance" 2 "Exceeds limits and external maintenance balancing is required" 1 "Exceeds limits and can be corrected via auto-balancing" 0 "Is within acceptable limits" ;
VAL_ 2364690942 ChargePLDueToAnUndefinedCause 3 "Not Available" 2 "Error" 1 "Power limited for this reason" 0 "No power limit for this reason" ;
VAL_ 2364690942 ChargePLDueToBatCur 3 "Not Available" 2 "Error" 1 "Power limited for this reason" 0 "No power limit for this reason" ;
VAL_ 2364690942 ChargePLDueToBatOrCellV 3 "Not Available" 2 "Error" 1 "Power limited for this reason" 0 "No power limit for this reason" ;
VAL_ 2364690942 ChargePLDueToBatDiagCondition 3 "Not Available" 2 "Error" 1 "Power limited for this reason" 0 "No power limit for this reason" ;
VAL_ 2364690942 ChargePLDueToBatTemp 3 "Not Available" 2 "Error" 1 "Power limited for this reason" 0 "No power limit for this reason" ;
VAL_ 2364690942 ChargePLDueToStOfCharge 3 "Not Available" 2 "Error" 1 "Power limited for this reason" 0 "No power limit for this reason" ;
VAL_ 2364690942 DisPLDueToAnUndefinedCause 3 "Not Available" 2 "Error" 1 "Power limited for this reason" 0 "No power limit for this reason" ;
VAL_ 2364690942 DisPLDueToBatCur 3 "Not Available" 2 "Error" 1 "Power limited for this reason" 0 "No power limit for this reason" ;
VAL_ 2364690942 DisPLDueToBatOrCellV 3 "Not Available" 2 "Error" 1 "Power limited for this reason" 0 "No power limit for this reason" ;
VAL_ 2364690942 DisPLDueToBatDiagCondition 3 "Not Available" 2 "Error" 1 "Power limited for this reason" 0 "No power limit for this reason" ;
VAL_ 2364690942 DisPLDueToBatTemp 3 "Not Available" 2 "Error" 1 "Power limited for this reason" 0 "No power limit for this reason" ;
VAL_ 2364690942 DisPLDueToStOfCharge 3 "Not Available" 2 "Error" 1 "Power limited for this reason" 0 "No power limit for this reason" ;
VAL_ 2565899518 HVBusPassiveIsolTestStatus 15 "Not available" 14 "Error" 13 "Reserved" 12 "Reserved" 11 "Reserved" 10 "Reserved" 9 "Reserved" 8 "Reserved" 7 "Reserved" 6 "Passive Isolation Test Inhibited" 5 "Test complete,  isolation fault" 4 "Test complete,  isolation marginal" 3 "Test complete,  isolation acceptable" 2 "Test in process" 1 "Test requested but not yet in process" 0 "No test requested / No test in process" ;
VAL_ 2565899518 HVBusActiveIsolTestStatus 15 "Not available" 14 "Error" 13 "Reserved" 12 "Reserved" 11 "Reserved" 10 "Reserved" 9 "Reserved" 8 "Reserved" 7 "Reserved" 6 "Active Isolation Test Inhibited" 5 "Test complete,  isolation fault" 4 "Test complete,  isolation marginal" 3 "Test complete,  isolation acceptable" 2 "Test in process" 1 "Test requested but not yet in process" 0 "No test requested / No test in process" ;
VAL_ 2565899262 HVBusPassiveIsolTestStatus 15 "Not available" 14 "Error" 13 "Reserved" 12 "Reserved" 11 "Reserved" 10 "Reserved" 9 "Reserved" 8 "Reserved" 7 "Reserved" 6 "Passive Isolation Test Inhibited" 5 "Test complete,  isolation fault" 4 "Test complete,  isolation marginal" 3 "Test complete,  isolation acceptable" 2 "Test in process" 1 "Test requested but not yet in process" 0 "No test requested / No test in process" ;
VAL_ 2565899262 HVBusActiveIsolTestStatus 15 "Not available" 14 "Error" 13 "Reserved" 12 "Reserved" 11 "Reserved" 10 "Reserved" 9 "Reserved" 8 "Reserved" 7 "Reserved" 6 "Active Isolation Test Inhibited" 5 "Test complete,  isolation fault" 4 "Test complete,  isolation marginal" 3 "Test complete,  isolation acceptable" 2 "Test in process" 1 "Test requested but not yet in process" 0 "No test requested / No test in process" ;
VAL_ 2364570366 HVILStatus 3 "Not Available" 2 "Error" 1 "HVIL Open" 0 "HVIL Closed" ;
VAL_ 2364570366 CtrlSetpointMode 31 "Not Available" 30 "Error" 29 "Manufacturer specific special mode 2" 28 "Manufacturer specific special mode 1" 27 "SAE Reserved" 26 "SAE Reserved" 25 "SAE Reserved" 24 "SAE Reserved" 23 "SAE Reserved" 22 "SAE Reserved" 21 "Inverter power down command" 20 "Inverter active discharge mode e.g" 19 "Manufacturer specific active mode 2" 18 "Manufacturer specific active mode 1" 17 "SAE Reserved" 16 "SAE Reserved" 15 "SAE Reserved" 14 "SAE Reserved" 13 "DC Energy Source 1 Voltage Control Mode" 12 "DC Power Control Mode" 11 "Electrical Power Control Mode" 10 "DC Energy Source 1 Current Mode" 9 "DC Energy Source 1 Voltage Mode" 8 "Frequency Control Mode" 7 "Current Control Mode" 6 "Manufacturer specific passive mode 2" 5 "Manufacturer specific passive mode 1" 4 "SAE Reserved" 3 "SAE Reserved" 2 "Standby" 1 "Waiting for Operational conditions" 0 "Powered On" ;
VAL_ 2364570366 CtrlLimitsOvrdMode 15 "Not Available" 14 "Error" 13 "SAE Reserved" 12 "SAE Reserved" 11 "SAE Reserved" 10 "SAE Reserved" 9 "SAE Reserved" 8 "SAE Reserved" 7 "SAE Reserved" 6 "Electrical Power Limits Mode" 5 "DC Energy Source 1 Power Limits Mode" 4 "DC Energy Source 1 Current Limits Mode" 3 "DC Energy Source 1 Voltage Limits Mode" 2 "Frequency Limits Mode" 1 "Current Limits Mode" 0 "Operating limits are not overridden" ;
VAL_ 2364569086 HVILStatus 3 "Not Available" 2 "Error" 1 "HVIL Open" 0 "HVIL Closed" ;
VAL_ 2364569086 CtrlSetpointMode 31 "Not Available" 30 "Error" 29 "Manufacturer specific special mode 2" 28 "Manufacturer specific special mode 1" 27 "SAE Reserved" 26 "SAE Reserved" 25 "SAE Reserved" 24 "SAE Reserved" 23 "SAE Reserved" 22 "SAE Reserved" 21 "Inverter power down command" 20 "Inverter active discharge mode e.g" 19 "Manufacturer specific active mode 2" 18 "Manufacturer specific active mode 1" 17 "SAE Reserved" 16 "SAE Reserved" 15 "SAE Reserved" 14 "SAE Reserved" 13 "DC Energy Source 1 Voltage Control Mode" 12 "DC Power Control Mode" 11 "Electrical Power Control Mode" 10 "DC Energy Source 1 Current Mode" 9 "DC Energy Source 1 Voltage Mode" 8 "Frequency Control Mode" 7 "Current Control Mode" 6 "Manufacturer specific passive mode 2" 5 "Manufacturer specific passive mode 1" 4 "SAE Reserved" 3 "SAE Reserved" 2 "Standby" 1 "Waiting for Operational conditions" 0 "Powered On" ;
VAL_ 2364569086 CtrlLimitsOvrdMode 15 "Not Available" 14 "Error" 13 "SAE Reserved" 12 "SAE Reserved" 11 "SAE Reserved" 10 "SAE Reserved" 9 "SAE Reserved" 8 "SAE Reserved" 7 "SAE Reserved" 6 "Electrical Power Limits Mode" 5 "DC Energy Source 1 Power Limits Mode" 4 "DC Energy Source 1 Current Limits Mode" 3 "DC Energy Source 1 Voltage Limits Mode" 2 "Frequency Limits Mode" 1 "Current Limits Mode" 0 "Operating limits are not overridden" ;
VAL_ 2364568830 PIDCtrlApplicableMode 15 "Don't Care/Take No Action" 14 "SAE Reserved" 13 "SAE Reserved" 12 "SAE Reserved" 11 "SAE Reserved" 10 "SAE Reserved" 9 "SAE Reserved" 8 "SAE Reserved" 7 "SAE Reserved" 6 "SAE Reserved" 5 "SAE Reserved" 4 "Electrical Power Control Mode" 3 "DC Power Control Mode" 2 "DC Energy Source 1 Current Mode" 1 "DC Energy Source 1 Voltage Mode" 0 "Frequency Control Mode" ;
VAL_ 2364568574 PIDCtrlApplicableMode 15 "Don't Care/Take No Action" 14 "SAE Reserved" 13 "SAE Reserved" 12 "SAE Reserved" 11 "SAE Reserved" 10 "SAE Reserved" 9 "SAE Reserved" 8 "SAE Reserved" 7 "SAE Reserved" 6 "SAE Reserved" 5 "SAE Reserved" 4 "Electrical Power Control Mode" 3 "DC Power Control Mode" 2 "DC Energy Source 1 Current Mode" 1 "DC Energy Source 1 Voltage Mode" 0 "Frequency Control Mode" ;
VAL_ 2364567806 SetpointModeReq 31 "Don't Care/Take No Action" 30 "SAE Reserved" 29 "Manufacturer specific special mode 2" 28 "Manufacturer specific special mode 1" 27 "SAE Reserved" 26 "SAE Reserved" 25 "SAE Reserved" 24 "SAE Reserved" 23 "SAE Reserved" 22 "SAE Reserved" 21 "Inverter power down command mode" 20 "Inverter active discharge mode e.g" 19 "Manufacturer specific active mode 2" 18 "Manufacturer specific active mode 1" 17 "SAE Reserved" 16 "SAE Reserved" 15 "SAE Reserved" 14 "SAE Reserved" 13 "SAE Reserved" 12 "Enable Electrical Power Control Mode" 11 "Enable DC Power Control Mode" 10 "Enable DC Energy Source 1 Current Mode" 9 "Enable DC Energy Source 1 Voltage Mode" 8 "Enable Frequency Control Mode" 7 "Enable Current Control Mode" 6 "Manufacturer specific passive mode 2" 5 "Manufacturer specific passive mode 1" 4 "SAE Reserved" 3 "SAE Reserved" 2 "Standby" 1 "SAE Reserved" 0 "Power On" ;
VAL_ 2364567550 SetpointModeReq 31 "Don't Care/Take No Action" 30 "SAE Reserved" 29 "Manufacturer specific special mode 2" 28 "Manufacturer specific special mode 1" 27 "SAE Reserved" 26 "SAE Reserved" 25 "SAE Reserved" 24 "SAE Reserved" 23 "SAE Reserved" 22 "SAE Reserved" 21 "Inverter power down command mode" 20 "Inverter active discharge mode e.g" 19 "Manufacturer specific active mode 2" 18 "Manufacturer specific active mode 1" 17 "SAE Reserved" 16 "SAE Reserved" 15 "SAE Reserved" 14 "SAE Reserved" 13 "SAE Reserved" 12 "Enable Electrical Power Control Mode" 11 "Enable DC Power Control Mode" 10 "Enable DC Energy Source 1 Current Mode" 9 "Enable DC Energy Source 1 Voltage Mode" 8 "Enable Frequency Control Mode" 7 "Enable Current Control Mode" 6 "Manufacturer specific passive mode 2" 5 "Manufacturer specific passive mode 1" 4 "SAE Reserved" 3 "SAE Reserved" 2 "Standby" 1 "SAE Reserved" 0 "Power On" ;
VAL_ 2555182846 ElectricPumpDriveSource 3 "Not available" 2 "Error" 1 "Pump driven from another source" 0 "Pump driven from electric motor" ;
VAL_ 2555182846 ElectricPumpPwrHold 3 "Don't Care/Take no action" 2 "Reserved" 1 "Power Hold Enabled" 0 "Power Hold Disabled" ;
VAL_ 2555182846 ElectricPumpEnableCmd 3 "Don't Care/Take no action" 2 "Motor On Reverse Direction" 1 "Motor On Normal/Default Direction" 0 "Motor Off" ;
VAL_ 2351103742 ThermalMnmgtMaintenanceReq 3 "Don't care/take no action" 2 "Reserved" 1 "HVESS Thermal Management Maintenance Mode is requested" 0 "HVESS Thermal Management Maintenance Mode is not requested" ;
VAL_ 2351103742 HVBusLowSideResistorConnectReq 3 "Don't care/take no action" 2 "Reserved" 1 "Connection Requested" 0 "Connection not Requested" ;
VAL_ 2351103742 HVBusHiSideResistorConnectReq 3 "Don't care/take no action" 2 "Reserved" 1 "Connection Requested" 0 "Connection not Requested" ;
VAL_ 2351103742 OpConsent 3 "Don't care/Take no action" 2 "Error" 1 "Consent given" 0 "Consent revoked" ;
VAL_ 2351103742 EnableInternalChargerCmd 3 "Don't care/Take no action" 2 "Reserved" 1 "Enable charging" 0 "Disable charging" ;
VAL_ 2351103742 CellBalancingCmd 3 "Don't care/Take no action" 2 "Reserved" 1 "Cell Balancing requested" 0 "Cell Balancing not requested" ;
VAL_ 2351103742 HVBusPassiveIsolTestCmd 3 "Don't care/Take no action" 2 "Reserved" 1 "Passive Isolation Test request" 0 "Passive Isolation Test not requested" ;
VAL_ 2351103742 HVBusActiveIsolTestCmd 3 "Don't care/Take no action" 2 "Reserved" 1 "Active Isolation Test request" 0 "Active Isolation Test not requested" ;
VAL_ 2351103742 PwrDownCmd 3 "Don't care/Take no action" 2 "Execute emergency power-down" 1 "Execute normal power-down" 0 "Power-down not requested" ;
VAL_ 2351103742 HVBusConnectCmd 3 "Don't care/Take no action" 2 "Emergency contactor closure request" 1 "Close Contactor" 0 "Open Contactor" ;
VAL_ 2351038206 ThermalMnmgtMaintenanceReq 3 "Don't care/take no action" 2 "Reserved" 1 "HVESS Thermal Management Maintenance Mode is requested" 0 "HVESS Thermal Management Maintenance Mode is not requested" ;
VAL_ 2351038206 HVBusLowSideResistorConnectReq 3 "Don't care/take no action" 2 "Reserved" 1 "Connection Requested" 0 "Connection not Requested" ;
VAL_ 2351038206 HVBusHiSideResistorConnectReq 3 "Don't care/take no action" 2 "Reserved" 1 "Connection Requested" 0 "Connection not Requested" ;
VAL_ 2351038206 OpConsent 3 "Don't care/Take no action" 2 "Error" 1 "Consent given" 0 "Consent revoked" ;
VAL_ 2351038206 EnableInternalChargerCmd 3 "Don't care/Take no action" 2 "Reserved" 1 "Enable charging" 0 "Disable charging" ;
VAL_ 2351038206 CellBalancingCmd 3 "Don't care/Take no action" 2 "Reserved" 1 "Cell Balancing requested" 0 "Cell Balancing not requested" ;
VAL_ 2351038206 HVBusPassiveIsolTestCmd 3 "Don't care/Take no action" 2 "Reserved" 1 "Passive Isolation Test request" 0 "Passive Isolation Test not requested" ;
VAL_ 2351038206 HVBusActiveIsolTestCmd 3 "Don't care/Take no action" 2 "Reserved" 1 "Active Isolation Test request" 0 "Active Isolation Test not requested" ;
VAL_ 2351038206 PwrDownCmd 3 "Don't care/Take no action" 2 "Execute emergency power-down" 1 "Execute normal power-down" 0 "Power-down not requested" ;
VAL_ 2351038206 HVBusConnectCmd 3 "Don't care/Take no action" 2 "Emergency contactor closure request" 1 "Close Contactor" 0 "Open Contactor" ;
VAL_ 2350972670 ThermalMnmgtMaintenanceReq 3 "Don't care/take no action" 2 "Reserved" 1 "HVESS Thermal Management Maintenance Mode is requested" 0 "HVESS Thermal Management Maintenance Mode is not requested" ;
VAL_ 2350972670 HVBusLowSideResistorConnectReq 3 "Don't care/take no action" 2 "Reserved" 1 "Connection Requested" 0 "Connection not Requested" ;
VAL_ 2350972670 HVBusHiSideResistorConnectReq 3 "Don't care/take no action" 2 "Reserved" 1 "Connection Requested" 0 "Connection not Requested" ;
VAL_ 2350972670 OpConsent 3 "Don't care/Take no action" 2 "Error" 1 "Consent given" 0 "Consent revoked" ;
VAL_ 2350972670 EnableInternalChargerCmd 3 "Don't care/Take no action" 2 "Reserved" 1 "Enable charging" 0 "Disable charging" ;
VAL_ 2350972670 CellBalancingCmd 3 "Don't care/Take no action" 2 "Reserved" 1 "Cell Balancing requested" 0 "Cell Balancing not requested" ;
VAL_ 2350972670 HVBusPassiveIsolTestCmd 3 "Don't care/Take no action" 2 "Reserved" 1 "Passive Isolation Test request" 0 "Passive Isolation Test not requested" ;
VAL_ 2350972670 HVBusActiveIsolTestCmd 3 "Don't care/Take no action" 2 "Reserved" 1 "Active Isolation Test request" 0 "Active Isolation Test not requested" ;
VAL_ 2350972670 PwrDownCmd 3 "Don't care/Take no action" 2 "Execute emergency power-down" 1 "Execute normal power-down" 0 "Power-down not requested" ;
VAL_ 2350972670 HVBusConnectCmd 3 "Don't care/Take no action" 2 "Emergency contactor closure request" 1 "Close Contactor" 0 "Open Contactor" ;
VAL_ 2350907134 ThermalMnmgtMaintenanceReq 3 "Don't care/take no action" 2 "Reserved" 1 "HVESS Thermal Management Maintenance Mode is requested" 0 "HVESS Thermal Management Maintenance Mode is not requested" ;
VAL_ 2350907134 HVBusLowSideResistorConnectReq 3 "Don't care/take no action" 2 "Reserved" 1 "Connection Requested" 0 "Connection not Requested" ;
VAL_ 2350907134 HVBusHiSideResistorConnectReq 3 "Don't care/take no action" 2 "Reserved" 1 "Connection Requested" 0 "Connection not Requested" ;
VAL_ 2350907134 OpConsent 3 "Don't care/Take no action" 2 "Error" 1 "Consent given" 0 "Consent revoked" ;
VAL_ 2350907134 EnableInternalChargerCmd 3 "Don't care/Take no action" 2 "Reserved" 1 "Enable charging" 0 "Disable charging" ;
VAL_ 2350907134 CellBalancingCmd 3 "Don't care/Take no action" 2 "Reserved" 1 "Cell Balancing requested" 0 "Cell Balancing not requested" ;
VAL_ 2350907134 HVBusPassiveIsolTestCmd 3 "Don't care/Take no action" 2 "Reserved" 1 "Passive Isolation Test request" 0 "Passive Isolation Test not requested" ;
VAL_ 2350907134 HVBusActiveIsolTestCmd 3 "Don't care/Take no action" 2 "Reserved" 1 "Active Isolation Test request" 0 "Active Isolation Test not requested" ;
VAL_ 2350907134 PwrDownCmd 3 "Don't care/Take no action" 2 "Execute emergency power-down" 1 "Execute normal power-down" 0 "Power-down not requested" ;
VAL_ 2350907134 HVBusConnectCmd 3 "Don't care/Take no action" 2 "Emergency contactor closure request" 1 "Close Contactor" 0 "Open Contactor" ;
VAL_ 2350579454 ThermalMnmgtMaintenanceReq 3 "Don't care/take no action" 2 "Reserved" 1 "HVESS Thermal Management Maintenance Mode is requested" 0 "HVESS Thermal Management Maintenance Mode is not requested" ;
VAL_ 2350579454 HVBusLowSideResistorConnectReq 3 "Don't care/take no action" 2 "Reserved" 1 "Connection Requested" 0 "Connection not Requested" ;
VAL_ 2350579454 HVBusHiSideResistorConnectReq 3 "Don't care/take no action" 2 "Reserved" 1 "Connection Requested" 0 "Connection not Requested" ;
VAL_ 2350579454 OpConsent 3 "Don't care/Take no action" 2 "Error" 1 "Consent given" 0 "Consent revoked" ;
VAL_ 2350579454 EnableInternalChargerCmd 3 "Don't care/Take no action" 2 "Reserved" 1 "Enable charging" 0 "Disable charging" ;
VAL_ 2350579454 CellBalancingCmd 3 "Don't care/Take no action" 2 "Reserved" 1 "Cell Balancing requested" 0 "Cell Balancing not requested" ;
VAL_ 2350579454 HVBusPassiveIsolTestCmd 3 "Don't care/Take no action" 2 "Reserved" 1 "Passive Isolation Test request" 0 "Passive Isolation Test not requested" ;
VAL_ 2350579454 HVBusActiveIsolTestCmd 3 "Don't care/Take no action" 2 "Reserved" 1 "Active Isolation Test request" 0 "Active Isolation Test not requested" ;
VAL_ 2350579454 PwrDownCmd 3 "Don't care/Take no action" 2 "Execute emergency power-down" 1 "Execute normal power-down" 0 "Power-down not requested" ;
VAL_ 2350579454 HVBusConnectCmd 3 "Don't care/Take no action" 2 "Emergency contactor closure request" 1 "Close Contactor" 0 "Open Contactor" ;
VAL_ 2350513918 ThermalMnmgtMaintenanceReq 3 "Don't care/take no action" 2 "Reserved" 1 "HVESS Thermal Management Maintenance Mode is requested" 0 "HVESS Thermal Management Maintenance Mode is not requested" ;
VAL_ 2350513918 HVBusLowSideResistorConnectReq 3 "Don't care/take no action" 2 "Reserved" 1 "Connection Requested" 0 "Connection not Requested" ;
VAL_ 2350513918 HVBusHiSideResistorConnectReq 3 "Don't care/take no action" 2 "Reserved" 1 "Connection Requested" 0 "Connection not Requested" ;
VAL_ 2350513918 OpConsent 3 "Don't care/Take no action" 2 "Error" 1 "Consent given" 0 "Consent revoked" ;
VAL_ 2350513918 EnableInternalChargerCmd 3 "Don't care/Take no action" 2 "Reserved" 1 "Enable charging" 0 "Disable charging" ;
VAL_ 2350513918 CellBalancingCmd 3 "Don't care/Take no action" 2 "Reserved" 1 "Cell Balancing requested" 0 "Cell Balancing not requested" ;
VAL_ 2350513918 HVBusPassiveIsolTestCmd 3 "Don't care/Take no action" 2 "Reserved" 1 "Passive Isolation Test request" 0 "Passive Isolation Test not requested" ;
VAL_ 2350513918 HVBusActiveIsolTestCmd 3 "Don't care/Take no action" 2 "Reserved" 1 "Active Isolation Test request" 0 "Active Isolation Test not requested" ;
VAL_ 2350513918 PwrDownCmd 3 "Don't care/Take no action" 2 "Execute emergency power-down" 1 "Execute normal power-down" 0 "Power-down not requested" ;
VAL_ 2350513918 HVBusConnectCmd 3 "Don't care/Take no action" 2 "Emergency contactor closure request" 1 "Close Contactor" 0 "Open Contactor" ;
VAL_ 2350448382 ThermalMnmgtMaintenanceReq 3 "Don't care/take no action" 2 "Reserved" 1 "HVESS Thermal Management Maintenance Mode is requested" 0 "HVESS Thermal Management Maintenance Mode is not requested" ;
VAL_ 2350448382 HVBusLowSideResistorConnectReq 3 "Don't care/take no action" 2 "Reserved" 1 "Connection Requested" 0 "Connection not Requested" ;
VAL_ 2350448382 HVBusHiSideResistorConnectReq 3 "Don't care/take no action" 2 "Reserved" 1 "Connection Requested" 0 "Connection not Requested" ;
VAL_ 2350448382 OpConsent 3 "Don't care/Take no action" 2 "Error" 1 "Consent given" 0 "Consent revoked" ;
VAL_ 2350448382 EnableInternalChargerCmd 3 "Don't care/Take no action" 2 "Reserved" 1 "Enable charging" 0 "Disable charging" ;
VAL_ 2350448382 CellBalancingCmd 3 "Don't care/Take no action" 2 "Reserved" 1 "Cell Balancing requested" 0 "Cell Balancing not requested" ;
VAL_ 2350448382 HVBusPassiveIsolTestCmd 3 "Don't care/Take no action" 2 "Reserved" 1 "Passive Isolation Test request" 0 "Passive Isolation Test not requested" ;
VAL_ 2350448382 HVBusActiveIsolTestCmd 3 "Don't care/Take no action" 2 "Reserved" 1 "Active Isolation Test request" 0 "Active Isolation Test not requested" ;
VAL_ 2350448382 PwrDownCmd 3 "Don't care/Take no action" 2 "Execute emergency power-down" 1 "Execute normal power-down" 0 "Power-down not requested" ;
VAL_ 2350448382 HVBusConnectCmd 3 "Don't care/Take no action" 2 "Emergency contactor closure request" 1 "Close Contactor" 0 "Open Contactor" ;
VAL_ 2350382846 ThermalMnmgtMaintenanceReq 3 "Don't care/take no action" 2 "Reserved" 1 "HVESS Thermal Management Maintenance Mode is requested" 0 "HVESS Thermal Management Maintenance Mode is not requested" ;
VAL_ 2350382846 HVBusLowSideResistorConnectReq 3 "Don't care/take no action" 2 "Reserved" 1 "Connection Requested" 0 "Connection not Requested" ;
VAL_ 2350382846 HVBusHiSideResistorConnectReq 3 "Don't care/take no action" 2 "Reserved" 1 "Connection Requested" 0 "Connection not Requested" ;
VAL_ 2350382846 OpConsent 3 "Don't care/Take no action" 2 "Error" 1 "Consent given" 0 "Consent revoked" ;
VAL_ 2350382846 EnableInternalChargerCmd 3 "Don't care/Take no action" 2 "Reserved" 1 "Enable charging" 0 "Disable charging" ;
VAL_ 2350382846 CellBalancingCmd 3 "Don't care/Take no action" 2 "Reserved" 1 "Cell Balancing requested" 0 "Cell Balancing not requested" ;
VAL_ 2350382846 HVBusPassiveIsolTestCmd 3 "Don't care/Take no action" 2 "Reserved" 1 "Passive Isolation Test request" 0 "Passive Isolation Test not requested" ;
VAL_ 2350382846 HVBusActiveIsolTestCmd 3 "Don't care/Take no action" 2 "Reserved" 1 "Active Isolation Test request" 0 "Active Isolation Test not requested" ;
VAL_ 2350382846 PwrDownCmd 3 "Don't care/Take no action" 2 "Execute emergency power-down" 1 "Execute normal power-down" 0 "Power-down not requested" ;
VAL_ 2350382846 HVBusConnectCmd 3 "Don't care/Take no action" 2 "Emergency contactor closure request" 1 "Close Contactor" 0 "Open Contactor" ;
VAL_ 2350317310 ThermalMnmgtMaintenanceReq 3 "Don't care/take no action" 2 "Reserved" 1 "HVESS Thermal Management Maintenance Mode is requested" 0 "HVESS Thermal Management Maintenance Mode is not requested" ;
VAL_ 2350317310 HVBusLowSideResistorConnectReq 3 "Don't care/take no action" 2 "Reserved" 1 "Connection Requested" 0 "Connection not Requested" ;
VAL_ 2350317310 HVBusHiSideResistorConnectReq 3 "Don't care/take no action" 2 "Reserved" 1 "Connection Requested" 0 "Connection not Requested" ;
VAL_ 2350317310 OpConsent 3 "Don't care/Take no action" 2 "Error" 1 "Consent given" 0 "Consent revoked" ;
VAL_ 2350317310 EnableInternalChargerCmd 3 "Don't care/Take no action" 2 "Reserved" 1 "Enable charging" 0 "Disable charging" ;
VAL_ 2350317310 CellBalancingCmd 3 "Don't care/Take no action" 2 "Reserved" 1 "Cell Balancing requested" 0 "Cell Balancing not requested" ;
VAL_ 2350317310 HVBusPassiveIsolTestCmd 3 "Don't care/Take no action" 2 "Reserved" 1 "Passive Isolation Test request" 0 "Passive Isolation Test not requested" ;
VAL_ 2350317310 HVBusActiveIsolTestCmd 3 "Don't care/Take no action" 2 "Reserved" 1 "Active Isolation Test request" 0 "Active Isolation Test not requested" ;
VAL_ 2350317310 PwrDownCmd 3 "Don't care/Take no action" 2 "Execute emergency power-down" 1 "Execute normal power-down" 0 "Power-down not requested" ;
VAL_ 2350317310 HVBusConnectCmd 3 "Don't care/Take no action" 2 "Emergency contactor closure request" 1 "Close Contactor" 0 "Open Contactor" ;
VAL_ 2350251774 ThermalMnmgtMaintenanceReq 3 "Don't care/take no action" 2 "Reserved" 1 "HVESS Thermal Management Maintenance Mode is requested" 0 "HVESS Thermal Management Maintenance Mode is not requested" ;
VAL_ 2350251774 HVBusLowSideResistorConnectReq 3 "Don't care/take no action" 2 "Reserved" 1 "Connection Requested" 0 "Connection not Requested" ;
VAL_ 2350251774 HVBusHiSideResistorConnectReq 3 "Don't care/take no action" 2 "Reserved" 1 "Connection Requested" 0 "Connection not Requested" ;
VAL_ 2350251774 OpConsent 3 "Don't care/Take no action" 2 "Error" 1 "Consent given" 0 "Consent revoked" ;
VAL_ 2350251774 EnableInternalChargerCmd 3 "Don't care/Take no action" 2 "Reserved" 1 "Enable charging" 0 "Disable charging" ;
VAL_ 2350251774 CellBalancingCmd 3 "Don't care/Take no action" 2 "Reserved" 1 "Cell Balancing requested" 0 "Cell Balancing not requested" ;
VAL_ 2350251774 HVBusPassiveIsolTestCmd 3 "Don't care/Take no action" 2 "Reserved" 1 "Passive Isolation Test request" 0 "Passive Isolation Test not requested" ;
VAL_ 2350251774 HVBusActiveIsolTestCmd 3 "Don't care/Take no action" 2 "Reserved" 1 "Active Isolation Test request" 0 "Active Isolation Test not requested" ;
VAL_ 2350251774 PwrDownCmd 3 "Don't care/Take no action" 2 "Execute emergency power-down" 1 "Execute normal power-down" 0 "Power-down not requested" ;
VAL_ 2350251774 HVBusConnectCmd 3 "Don't care/Take no action" 2 "Emergency contactor closure request" 1 "Close Contactor" 0 "Open Contactor" ;
VAL_ 2350186238 ThermalMnmgtMaintenanceReq 3 "Don't care/take no action" 2 "Reserved" 1 "HVESS Thermal Management Maintenance Mode is requested" 0 "HVESS Thermal Management Maintenance Mode is not requested" ;
VAL_ 2350186238 HVBusLowSideResistorConnectReq 3 "Don't care/take no action" 2 "Reserved" 1 "Connection Requested" 0 "Connection not Requested" ;
VAL_ 2350186238 HVBusHiSideResistorConnectReq 3 "Don't care/take no action" 2 "Reserved" 1 "Connection Requested" 0 "Connection not Requested" ;
VAL_ 2350186238 OpConsent 3 "Don't care/Take no action" 2 "Error" 1 "Consent given" 0 "Consent revoked" ;
VAL_ 2350186238 EnableInternalChargerCmd 3 "Don't care/Take no action" 2 "Reserved" 1 "Enable charging" 0 "Disable charging" ;
VAL_ 2350186238 CellBalancingCmd 3 "Don't care/Take no action" 2 "Reserved" 1 "Cell Balancing requested" 0 "Cell Balancing not requested" ;
VAL_ 2350186238 HVBusPassiveIsolTestCmd 3 "Don't care/Take no action" 2 "Reserved" 1 "Passive Isolation Test request" 0 "Passive Isolation Test not requested" ;
VAL_ 2350186238 HVBusActiveIsolTestCmd 3 "Don't care/Take no action" 2 "Reserved" 1 "Active Isolation Test request" 0 "Active Isolation Test not requested" ;
VAL_ 2350186238 PwrDownCmd 3 "Don't care/Take no action" 2 "Execute emergency power-down" 1 "Execute normal power-down" 0 "Power-down not requested" ;
VAL_ 2350186238 HVBusConnectCmd 3 "Don't care/Take no action" 2 "Emergency contactor closure request" 1 "Close Contactor" 0 "Open Contactor" ;
VAL_ 2350120702 ThermalMnmgtMaintenanceReq 3 "Don't care/take no action" 2 "Reserved" 1 "HVESS Thermal Management Maintenance Mode is requested" 0 "HVESS Thermal Management Maintenance Mode is not requested" ;
VAL_ 2350120702 HVBusLowSideResistorConnectReq 3 "Don't care/take no action" 2 "Reserved" 1 "Connection Requested" 0 "Connection not Requested" ;
VAL_ 2350120702 HVBusHiSideResistorConnectReq 3 "Don't care/take no action" 2 "Reserved" 1 "Connection Requested" 0 "Connection not Requested" ;
VAL_ 2350120702 OpConsent 3 "Don't care/Take no action" 2 "Error" 1 "Consent given" 0 "Consent revoked" ;
VAL_ 2350120702 EnableInternalChargerCmd 3 "Don't care/Take no action" 2 "Reserved" 1 "Enable charging" 0 "Disable charging" ;
VAL_ 2350120702 CellBalancingCmd 3 "Don't care/Take no action" 2 "Reserved" 1 "Cell Balancing requested" 0 "Cell Balancing not requested" ;
VAL_ 2350120702 HVBusPassiveIsolTestCmd 3 "Don't care/Take no action" 2 "Reserved" 1 "Passive Isolation Test request" 0 "Passive Isolation Test not requested" ;
VAL_ 2350120702 HVBusActiveIsolTestCmd 3 "Don't care/Take no action" 2 "Reserved" 1 "Active Isolation Test request" 0 "Active Isolation Test not requested" ;
VAL_ 2350120702 PwrDownCmd 3 "Don't care/Take no action" 2 "Execute emergency power-down" 1 "Execute normal power-down" 0 "Power-down not requested" ;
VAL_ 2350120702 HVBusConnectCmd 3 "Don't care/Take no action" 2 "Emergency contactor closure request" 1 "Close Contactor" 0 "Open Contactor" ;
VAL_ 2350055166 ThermalMnmgtMaintenanceReq 3 "Don't care/take no action" 2 "Reserved" 1 "HVESS Thermal Management Maintenance Mode is requested" 0 "HVESS Thermal Management Maintenance Mode is not requested" ;
VAL_ 2350055166 HVBusLowSideResistorConnectReq 3 "Don't care/take no action" 2 "Reserved" 1 "Connection Requested" 0 "Connection not Requested" ;
VAL_ 2350055166 HVBusHiSideResistorConnectReq 3 "Don't care/take no action" 2 "Reserved" 1 "Connection Requested" 0 "Connection not Requested" ;
VAL_ 2350055166 OpConsent 3 "Don't care/Take no action" 2 "Error" 1 "Consent given" 0 "Consent revoked" ;
VAL_ 2350055166 EnableInternalChargerCmd 3 "Don't care/Take no action" 2 "Reserved" 1 "Enable charging" 0 "Disable charging" ;
VAL_ 2350055166 CellBalancingCmd 3 "Don't care/Take no action" 2 "Reserved" 1 "Cell Balancing requested" 0 "Cell Balancing not requested" ;
VAL_ 2350055166 HVBusPassiveIsolTestCmd 3 "Don't care/Take no action" 2 "Reserved" 1 "Passive Isolation Test request" 0 "Passive Isolation Test not requested" ;
VAL_ 2350055166 HVBusActiveIsolTestCmd 3 "Don't care/Take no action" 2 "Reserved" 1 "Active Isolation Test request" 0 "Active Isolation Test not requested" ;
VAL_ 2350055166 PwrDownCmd 3 "Don't care/Take no action" 2 "Execute emergency power-down" 1 "Execute normal power-down" 0 "Power-down not requested" ;
VAL_ 2350055166 HVBusConnectCmd 3 "Don't care/Take no action" 2 "Emergency contactor closure request" 1 "Close Contactor" 0 "Open Contactor" ;
VAL_ 2349989630 ThermalMnmgtMaintenanceReq 3 "Don't care/take no action" 2 "Reserved" 1 "HVESS Thermal Management Maintenance Mode is requested" 0 "HVESS Thermal Management Maintenance Mode is not requested" ;
VAL_ 2349989630 HVBusLowSideResistorConnectReq 3 "Don't care/take no action" 2 "Reserved" 1 "Connection Requested" 0 "Connection not Requested" ;
VAL_ 2349989630 HVBusHiSideResistorConnectReq 3 "Don't care/take no action" 2 "Reserved" 1 "Connection Requested" 0 "Connection not Requested" ;
VAL_ 2349989630 OpConsent 3 "Don't care/Take no action" 2 "Error" 1 "Consent given" 0 "Consent revoked" ;
VAL_ 2349989630 EnableInternalChargerCmd 3 "Don't care/Take no action" 2 "Reserved" 1 "Enable charging" 0 "Disable charging" ;
VAL_ 2349989630 CellBalancingCmd 3 "Don't care/Take no action" 2 "Reserved" 1 "Cell Balancing requested" 0 "Cell Balancing not requested" ;
VAL_ 2349989630 HVBusPassiveIsolTestCmd 3 "Don't care/Take no action" 2 "Reserved" 1 "Passive Isolation Test request" 0 "Passive Isolation Test not requested" ;
VAL_ 2349989630 HVBusActiveIsolTestCmd 3 "Don't care/Take no action" 2 "Reserved" 1 "Active Isolation Test request" 0 "Active Isolation Test not requested" ;
VAL_ 2349989630 PwrDownCmd 3 "Don't care/Take no action" 2 "Execute emergency power-down" 1 "Execute normal power-down" 0 "Power-down not requested" ;
VAL_ 2349989630 HVBusConnectCmd 3 "Don't care/Take no action" 2 "Emergency contactor closure request" 1 "Close Contactor" 0 "Open Contactor" ;
VAL_ 2349924094 ThermalMnmgtMaintenanceReq 3 "Don't care/take no action" 2 "Reserved" 1 "HVESS Thermal Management Maintenance Mode is requested" 0 "HVESS Thermal Management Maintenance Mode is not requested" ;
VAL_ 2349924094 HVBusLowSideResistorConnectReq 3 "Don't care/take no action" 2 "Reserved" 1 "Connection Requested" 0 "Connection not Requested" ;
VAL_ 2349924094 HVBusHiSideResistorConnectReq 3 "Don't care/take no action" 2 "Reserved" 1 "Connection Requested" 0 "Connection not Requested" ;
VAL_ 2349924094 OpConsent 3 "Don't care/Take no action" 2 "Error" 1 "Consent given" 0 "Consent revoked" ;
VAL_ 2349924094 EnableInternalChargerCmd 3 "Don't care/Take no action" 2 "Reserved" 1 "Enable charging" 0 "Disable charging" ;
VAL_ 2349924094 CellBalancingCmd 3 "Don't care/Take no action" 2 "Reserved" 1 "Cell Balancing requested" 0 "Cell Balancing not requested" ;
VAL_ 2349924094 HVBusPassiveIsolTestCmd 3 "Don't care/Take no action" 2 "Reserved" 1 "Passive Isolation Test request" 0 "Passive Isolation Test not requested" ;
VAL_ 2349924094 HVBusActiveIsolTestCmd 3 "Don't care/Take no action" 2 "Reserved" 1 "Active Isolation Test request" 0 "Active Isolation Test not requested" ;
VAL_ 2349924094 PwrDownCmd 3 "Don't care/Take no action" 2 "Execute emergency power-down" 1 "Execute normal power-down" 0 "Power-down not requested" ;
VAL_ 2349924094 HVBusConnectCmd 3 "Don't care/Take no action" 2 "Emergency contactor closure request" 1 "Close Contactor" 0 "Open Contactor" ;
